[part 3 of 22: package /Cluster]
AUTOSAR XML (schema 4-3-0)
package /Cluster
  can cluster E3V_CCAN: baudrate=500000, protocol-name=CAN, protocol-version=2.0, bus-off-recovery={bor-counter-l-1-to-l-2=1, bor-time-l-1=0.05, bor-time-l-2=0.2}  # CAN Connect
    can physical channel CHNL: comm-connectors=CN_E3V_CCAN
      frame BCM_01_XIX_E3V_CCAN: id 0x65A, from SAM, frame-length=8, can-addressing-mode=STANDARD, can-frame-rx-behavior=CAN-20, can-frame-tx-behavior=CAN-20
        pdu BCM_01_XIX_E3V_CCAN_E2E: length=8, minimum-delay=0.03, transmission-mode-true-timing=event-controlled-timing={number-of-repetitions=0, repetition-period=0.0}, unused-bit-pattern=0  # Fuer die Botschaft ist das Cyclic-Timing 1.0 zu verwenden.
          signal BCM_01_CRC_XIX_BCM_01_XIX_E3V_CCAN: start 0, 8 bit, little-endian, data-type-policy=OVERRIDE, i-signal-type=PRIMITIVE, base-type=BT_BCM_01_CRC, compu {phys=raw for raw 0..255}, range phys 0..255, raw 0..255  # Für MLB: "Berechnung siehe Lastenheft "Kommunikationsabsicherung für FlexRay und CAN"" Ab MQB und MLBevo: "Berechnung siehe Lastenheft "End-to-End Kommunikationsabsicherung"" Endwerte siehe Begleitdokument "S-PDU Kennungsfolgen"
          signal BCM_01_BZ_XIX_BCM_01_XIX_E3V_CCAN: start 8, 4 bit, little-endian, data-type-policy=OVERRIDE, i-signal-type=PRIMITIVE, base-type=BT_BCM_01_BZ, compu {phys=raw for raw 0..15}, range phys 0..15, raw 0..15  # 4bit Botschaftszaehler; wird in jeder Sendebotschaft inkrementiert
          signal BCM_Bremsbelag_Sensor_XIX_BCM_01_XIX_E3V_CCAN: start 12, 1 bit, little-endian, data-type-policy=OVERRIDE, i-signal-type=PRIMITIVE, init-value=0, base-type=BT_BCM_Bremsbelag_Sensor, compu {0=Cx0_OK (CM_BCM_Bremsbelag_Sensor_Cx0_OK), 1=Cx1_Bremsbelag_unter_min (CM_BCM_Bremsbelag_Sensor_Cx1_Bremsbelag_unter_min)}, range raw 0..1  # Sensorsignal der Stromschleife für Bremsbelagverschleiß aktuell, entstört, unbewertet
          signal BCM_Bremsfluessigkeit_Sensor_XIX_BCM_01_XIX_E3V_CCAN: start 13, 1 bit, little-endian, data-type-policy=OVERRIDE, i-signal-type=PRIMITIVE, init-value=0, base-type=BT_BCM_Bremsfluessigkeit_Sensor, compu {0=Cx0_OK (CM_BCM_Bremsfluessigkeit_Sensor_Cx0_OK), 1=Cx1_Bremsfluessigkeit_unter_min (CM_BCM_Bremsfluessigkeit_Sensor_Cx1_Bremsfluessigkeit_unter_min)}, range raw 0..1  # Kontaktsignal des Sensorschalters für die Bremsflüssigkeitsreserve aktuell, entstört, unbewertet
          signal ISignalVoid_BCM_01_XIX_E3V_CCAN_0: start 14, 1 bit, little-endian, system signal SignalVoid_BCM_01_0, data-type-policy=OVERRIDE, i-signal-type=PRIMITIVE, base-type=BT_SignalVoid
          signal BCM_Waschwasser_Sensor_XIX_BCM_01_XIX_E3V_CCAN: start 15, 1 bit, little-endian, data-type-policy=OVERRIDE, i-signal-type=PRIMITIVE, init-value=0, base-type=BT_BCM_Waschwasser_Sensor, compu {0=Cx0_OK (CM_BCM_Waschwasser_Sensor_Cx0_OK), 1=Cx1_Waschwasser_unter_min (CM_BCM_Waschwasser_Sensor_Cx1_Waschwasser_unter_min)}, range raw 0..1  # Signal der Sensorelektroden für die Waschwasserreserve aktuell, entstört, bewertet (OK/Mangel)
          signal BCM_Kuehlmittel_Sensor_XIX_BCM_01_XIX_E3V_CCAN: start 16, 1 bit, little-endian, data-type-policy=OVERRIDE, i-signal-type=PRIMITIVE, init-value=0, base-type=BT_BCM_Kuehlmittel_Sensor, compu {0=Cx0_OK (CM_BCM_Kuehlmittel_Sensor_Cx0_OK), 1=Cx1_Kuehlmittel_unter_min (CM_BCM_Kuehlmittel_Sensor_Cx1_Kuehlmittel_unter_min)}, range raw 0..1  # Signal der Sensorelektroden für die Kühlmittelreserve aktuell, entstört, bewertet (OK/Mangel)
          signal BCM1_Kl_15_HW_erkannt_XIX_BCM_01_XIX_E3V_CCAN: start 17, 1 bit, little-endian, data-type-policy=OVERRIDE, i-signal-type=PRIMITIVE, init-value=0, base-type=BT_BCM1_Kl_15_HW_erkannt, compu {1=Cx1_Klemme_15_erkannt (CM_BCM1_Kl_15_HW_erkannt_Cx1_Klemme_15_erkannt) (Klemme 15 erkannt)}, range raw 1  # Erkennung Klemme 15 (Hardware) vom BCM1
          signal BCM1_Kl_15_Sig_HW_erkannt_XIX_BCM_01_XIX_E3V_CCAN: start 18, 1 bit, little-endian, data-type-policy=OVERRIDE, i-signal-type=PRIMITIVE, init-value=0, base-type=BT_BCM1_Kl_15_Sig_HW_erkannt, compu {0=Cx0_KL15_HW_Signal_von_BCM1_nicht_erkannt (CM_BCM1_Kl_15_Sig_HW_erkannt_Cx0_KL15_HW_Signal_von_BCM1_nicht_erkannt), 1=Cx1_KL15_HW_Signal_von_BCM1_erkannt (CM_BCM1_Kl_15_Sig_HW_erkannt_Cx1_KL15_HW_Signal_von_BCM1_erkannt)}, range raw 0..1  # Erkennung Klemme 15 Signal (Hardware) vom BCM1
          signal BCM_Kuehlmittel_Sensor_02_XIX_BCM_01_XIX_E3V_CCAN: start 19, 1 bit, little-endian, data-type-policy=OVERRIDE, i-signal-type=PRIMITIVE, init-value=0, base-type=BT_BCM_Kuehlmittel_Sensor_02, compu {0=Cx0_OK (CM_BCM_Kuehlmittel_Sensor_02_Cx0_OK), 1=Cx1_Kuehlmittel_unter_min (CM_BCM_Kuehlmittel_Sensor_02_Cx1_Kuehlmittel_unter_min)}, range raw 0..1  # Signal der zweiten Sensorelektroden für die Kühlmittelreserve aktuell, entstört, bewertet (OK/Mangel)
          signal ISignalVoid_BCM_01_XIX_E3V_CCAN_1: start 20, 1 bit, little-endian, system signal SignalVoid_BCM_01_1, data-type-policy=OVERRIDE, i-signal-type=PRIMITIVE, base-type=BT_SignalVoid
          signal BCM_Offroad_Taste_XIX_BCM_01_XIX_E3V_CCAN: start 21, 1 bit, little-endian, data-type-policy=OVERRIDE, i-signal-type=PRIMITIVE, init-value=0, base-type=BT_BCM_Offroad_Taste, compu {0=Cx0_Taster_nicht_betaetigt (CM_BCM_Offroad_Taste_Cx0_Taster_nicht_betaetigt), 1=Cx1_Taster_betaetigt (CM_BCM_Offroad_Taste_Cx1_Taster_betaetigt)}, range raw 0..1  # Betätigung der Offroad-Taste
          signal BCM_Charisma_Taste2_XIX_BCM_01_XIX_E3V_CCAN: start 22, 1 bit, little-endian, data-type-policy=OVERRIDE, i-signal-type=PRIMITIVE, init-value=0, base-type=BT_BCM_Charisma_Taste2, compu {0=Cx0_nicht_betaetigt (CM_BCM_Charisma_Taste2_Cx0_nicht_betaetigt), 1=Cx1_betaetigt (CM_BCM_Charisma_Taste2_Cx1_betaetigt)}, range raw 0..1  # Betätigung der Charisma-Taste 2
          signal BCM_Hybrid_StSt_Taste_Fehler_XIX_BCM_01_XIX_E3V_CCAN: start 23, 1 bit, little-endian, data-type-policy=OVERRIDE, i-signal-type=PRIMITIVE, init-value=0, base-type=BT_BCM_Hybrid_StSt_Taste_Fehler, compu {0=Cx0_kein_Fehler_StSt_Taster (CM_BCM_Hybrid_StSt_Taste_Fehler_Cx0_kein_Fehler_StSt_Taster), 1=Cx1_Fehler_StSt_Taster (CM_BCM_Hybrid_StSt_Taste_Fehler_Cx1_Fehler_StSt_Taster)}, range raw 0..1  # Fehlerflag, wenn Tasterdiagnose im BCM für den StSt-Taster anschlägt.
          signal BCM_Hybrid_StartStopp_Taste_XIX_BCM_01_XIX_E3V_CCAN: start 24, 1 bit, little-endian, data-type-policy=OVERRIDE, i-signal-type=PRIMITIVE, init-value=0, base-type=BT_BCM_Hybrid_StartStopp_Taste, compu {0=Cx0_nicht_betaetigt (CM_BCM_Hybrid_StartStopp_Taste_Cx0_nicht_betaetigt), 1=Cx1_betaetigt (CM_BCM_Hybrid_StartStopp_Taste_Cx1_betaetigt)}, range raw 0..1  # Betaetigung Taster "Hybrid" oder alternativ Taster "Start/Stopp Deaktivierung", je nach Verbau
          signal BCM1_Warnblink_Taster_XIX_BCM_01_XIX_E3V_CCAN: start 25, 1 bit, little-endian, data-type-policy=OVERRIDE, i-signal-type=PRIMITIVE, init-value=0, base-type=BT_BCM1_Warnblink_Taster, compu {0=Cx0_nicht_betaetigt (CM_BCM1_Warnblink_Taster_Cx0_nicht_betaetigt), 1=Cx1_betaetigt (CM_BCM1_Warnblink_Taster_Cx1_betaetigt)}, range raw 0..1  # Warnblinktaster
          signal BCM1_Valet_Parking_Taster_XIX_BCM_01_XIX_E3V_CCAN: start 26, 1 bit, little-endian, data-type-policy=OVERRIDE, i-signal-type=PRIMITIVE, init-value=0, base-type=BT_BCM1_Valet_Parking_Taster, compu {0=Cx0_nicht_betaetigt (CM_BCM1_Valet_Parking_Taster_Cx0_nicht_betaetigt), 1=Cx1_betaetigt (CM_BCM1_Valet_Parking_Taster_Cx1_betaetigt)}, range raw 0..1  # Valet Parking Taster
          signal ISignalVoid_BCM_01_XIX_E3V_CCAN_2: start 27, 3 bit, little-endian, system signal SignalVoid_BCM_01_2, data-type-policy=OVERRIDE, i-signal-type=PRIMITIVE, base-type=BT_SignalVoid
          signal BCM1_Rueckfahrlicht_Schalter_XIX_BCM_01_XIX_E3V_CCAN: start 30, 1 bit, little-endian, data-type-policy=OVERRIDE, i-signal-type=PRIMITIVE, init-value=0, base-type=BT_BCM1_Rueckfahrlicht_Schalter, compu {0=Cx0_nicht_betaetigt (CM_BCM1_Rueckfahrlicht_Schalter_Cx0_nicht_betaetigt), 1=Cx1_betaetigt (CM_BCM1_Rueckfahrlicht_Schalter_Cx1_betaetigt)}, range raw 0..1  # Rückfahrlichtschalter ab MQB/ MLBevo: Die Ganginformation wird unentprellt übertragen, im AT-Getriebe wird evtl. kurzzeitig der R-Gang angezeigt. Eine Entprellung muß im Empfänger erfolgen (typisch 400ms).
          signal BCM1_MH_Schalter_XIX_BCM_01_XIX_E3V_CCAN: start 31, 1 bit, little-endian, data-type-policy=OVERRIDE, i-signal-type=PRIMITIVE, init-value=0, base-type=BT_BCM1_MH_Schalter, compu {0=Cx0_MH_geschlossen (CM_BCM1_MH_Schalter_Cx0_MH_geschlossen), 1=Cx1_MH_offen (CM_BCM1_MH_Schalter_Cx1_MH_offen)}, range raw 0..1  # Motorhaubenkontakt
          signal BCM1_MH_WIV_Schalter_XIX_BCM_01_XIX_E3V_CCAN: start 32, 1 bit, little-endian, data-type-policy=OVERRIDE, i-signal-type=PRIMITIVE, init-value=0, base-type=BT_BCM1_MH_WIV_Schalter, compu {0=Cx0_MH_geschlossen (CM_BCM1_MH_WIV_Schalter_Cx0_MH_geschlossen), 1=Cx1_MH_offen (CM_BCM1_MH_WIV_Schalter_Cx1_MH_offen)}, range raw 0..1  # Bewerteter Motorhaubenkontakt fuer WIV
          signal BCM_Eco_Charisma_Taste_XIX_BCM_01_XIX_E3V_CCAN: start 33, 1 bit, little-endian, data-type-policy=OVERRIDE, i-signal-type=PRIMITIVE, init-value=0, base-type=BT_BCM_Eco_Charisma_Taste, compu {0=Cx0_nicht_betaetigt (CM_BCM_Eco_Charisma_Taste_Cx0_nicht_betaetigt), 1=Cx1_betaetigt (CM_BCM_Eco_Charisma_Taste_Cx1_betaetigt)}, range raw 0..1  # Betätigung Taster ECO alias BlueKey oder Charisma
          signal BCM1_NV_Taster_XIX_BCM_01_XIX_E3V_CCAN: start 34, 1 bit, little-endian, data-type-policy=OVERRIDE, i-signal-type=PRIMITIVE, init-value=0, base-type=BT_BCM1_NV_Taster, compu {0=Cx0_Taster_nicht_betaetigt (CM_BCM1_NV_Taster_Cx0_Taster_nicht_betaetigt), 1=Cx1_Taster_betaetigt (CM_BCM1_NV_Taster_Cx1_Taster_betaetigt)}, range raw 0..1  # BCM1_NV_Taster gibt an, ob der NightVision-Taster im Lichtdrehschalter-Modul aktuell betaetigt wird.
          signal BCM1_AFS_Lampe_XIX_BCM_01_XIX_E3V_CCAN: start 35, 1 bit, little-endian, data-type-policy=OVERRIDE, i-signal-type=PRIMITIVE, init-value=0, base-type=BT_BCM1_AFS_Lampe, compu {0=Cx0_Aus (CM_BCM1_AFS_Lampe_Cx0_Aus), 1=Cx1_Ein (CM_BCM1_AFS_Lampe_Cx1_Ein)}, range raw 0..1  # Ansteuerung der AFS-Fehlermeldung im Kombi
          signal BCM1_Reisemodus_Texte_XIX_BCM_01_XIX_E3V_CCAN: start 36, 2 bit, little-endian, data-type-policy=OVERRIDE, i-signal-type=PRIMITIVE, init-value=0, base-type=BT_BCM1_Reisemodus_Texte, compu {0=Cx0_keine_Anzeige (CM_BCM1_Reisemodus_Texte_Cx0_keine_Anzeige), 1=Cx1_Umschaltung_auf_Linksverkehr_aktiv (CM_BCM1_Reisemodus_Texte_Cx1_Umschaltung_auf_Linksverkehr_aktiv), 2=Cx2_Umschaltung_auf_Rechtsverkehr_aktiv (CM_BCM1_Reisemodus_Texte_Cx2_Umschaltung_auf_Rechtsverkehr_aktiv)}, range raw 0..2  # Ansteuerung der Reisemodus-Texte im Kombi
          signal ISignalVoid_BCM_01_XIX_E3V_CCAN_3: start 38, 2 bit, little-endian, system signal SignalVoid_BCM_01_3, data-type-policy=OVERRIDE, i-signal-type=PRIMITIVE, base-type=BT_SignalVoid
          signal Gong_TFL_Umschaltung_XIX_BCM_01_XIX_E3V_CCAN: start 40, 1 bit, little-endian, data-type-policy=OVERRIDE, i-signal-type=PRIMITIVE, init-value=0, base-type=BT_Gong_TFL_Umschaltung, compu {0=Cx0_kein_Gong (CM_Gong_TFL_Umschaltung_Cx0_kein_Gong), 1=Cx1_Gong_einmalig (CM_Gong_TFL_Umschaltung_Cx1_Gong_einmalig)}, range raw 0..1  # Aktivierung / Deaktivierung des TFL per Affengriff wird mit einem Gong im Kombi quittiert.
          signal ISignalVoid_BCM_01_XIX_E3V_CCAN_4: start 41, 1 bit, little-endian, system signal SignalVoid_BCM_01_4, data-type-policy=OVERRIDE, i-signal-type=PRIMITIVE, base-type=BT_SignalVoid
          signal BCM_ValetTaster_Fkts_LED_XIX_BCM_01_XIX_E3V_CCAN: start 42, 1 bit, little-endian, data-type-policy=OVERRIDE, i-signal-type=PRIMITIVE, init-value=0, base-type=BT_BCM_ValetTaster_Fkts_LED, compu {0=Cx0_LED_aus (CM_BCM_ValetTaster_Fkts_LED_Cx0_LED_aus), 1=Cx1_LED_ein (CM_BCM_ValetTaster_Fkts_LED_Cx1_LED_ein)}, range raw 0..1  # Im MQB beschreibt das Signal nur den Zustand der Funktion Valet Parking (aktiv/ inaktiv) Im MLBevo wird über das Signal zusätzlich die ValetTaster_Fkts_LED (an/ aus) gesteuert
          signal LRH_Taster_XIX_BCM_01_XIX_E3V_CCAN: start 43, 1 bit, little-endian, data-type-policy=OVERRIDE, i-signal-type=PRIMITIVE, init-value=0, base-type=BT_LRH_Taster, compu {0=Cx0_nicht_betaetigt (CM_LRH_Taster_Cx0_nicht_betaetigt), 1=Cx1_betaetigt (CM_LRH_Taster_Cx1_betaetigt)}, range raw 0..1  # Tasterbetätigung Lenkradheizung
          signal APS_Tongeber_defekt_XIX_BCM_01_XIX_E3V_CCAN: start 44, 1 bit, little-endian, data-type-policy=OVERRIDE, i-signal-type=PRIMITIVE, init-value=0, base-type=BT_APS_Tongeber_defekt, compu {0=Cx0_iO (CM_APS_Tongeber_defekt_Cx0_iO), 1=Cx1_defekt (CM_APS_Tongeber_defekt_Cx1_defekt)}, range raw 0..1  # Status APS-Tongeber zur HMI-Ansteuerng der RCTA-Funktion
          signal BCM1_EasyEntry_Status_XIX_BCM_01_XIX_E3V_CCAN: start 45, 1 bit, little-endian, data-type-policy=OVERRIDE, i-signal-type=PRIMITIVE, init-value=0, base-type=BT_BCM1_EasyEntry_Status, compu {0=Cx0_Aus (CM_BCM1_EasyEntry_Status_Cx0_Aus), 1=Cx1_Ein (CM_BCM1_EasyEntry_Status_Cx1_Ein)}, range raw 0..1  # Status EasyEntry für Lenksäule (wird auch von IVB verwendet)
          signal BCM1_Lenksaeule_aktiv_XIX_BCM_01_XIX_E3V_CCAN: start 46, 1 bit, little-endian, data-type-policy=OVERRIDE, i-signal-type=PRIMITIVE, init-value=0, base-type=BT_BCM1_Lenksaeule_aktiv, compu {0=Cx0_Lenksaeulenverstellung_nicht_aktiv (CM_BCM1_Lenksaeule_aktiv_Cx0_Lenksaeulenverstellung_nicht_aktiv) (Lenksaeulenverstellung nicht aktiv), 1=Cx1_Lenksaeulenverstellung_aktiv (CM_BCM1_Lenksaeule_aktiv_Cx1_Lenksaeulenverstellung_aktiv) (Lenksaeulenverstellung aktiv)}, range raw 0..1  # Lenksaeulenverstellung aktiv
          signal BCM1_Spannungs_Anf_XIX_BCM_01_XIX_E3V_CCAN: start 47, 2 bit, little-endian, data-type-policy=OVERRIDE, i-signal-type=PRIMITIVE, init-value=0, base-type=BT_BCM1_Spannungs_Anf, compu {0=Cx0_keine_Anforderung (CM_BCM1_Spannungs_Anf_Cx0_keine_Anforderung), 1=Cx1_Anforderung_Stufe_1 (CM_BCM1_Spannungs_Anf_Cx1_Anforderung_Stufe_1), 2=Cx2_Anforderung_Stufe_2 (CM_BCM1_Spannungs_Anf_Cx2_Anforderung_Stufe_2), 3=Cx3_Anforderung_Stufe_3 (CM_BCM1_Spannungs_Anf_Cx3_Anforderung_Stufe_3)}, range raw 0..3  # Forderung des BCM1-SG's zur Spannungsanhebung.
          signal ISignalVoid_BCM_01_XIX_E3V_CCAN_5: start 49, 7 bit, little-endian, system signal SignalVoid_BCM_01_5, data-type-policy=OVERRIDE, i-signal-type=PRIMITIVE, base-type=BT_SignalVoid
          signal ISignalVoid_BCM_01_XIX_E3V_CCAN_6: start 56, 2 bit, little-endian, system signal SignalVoid_BCM_01_6, data-type-policy=OVERRIDE, i-signal-type=PRIMITIVE, base-type=BT_SignalVoid
          signal BCM_Anf_AAW_MoLaWa_XIX_BCM_01_XIX_E3V_CCAN: start 58, 2 bit, little-endian, data-type-policy=OVERRIDE, i-signal-type=PRIMITIVE, init-value=0, base-type=BT_BCM_Anf_AAW_MoLaWa, compu {0=Cx0_Init (CM_BCM_Anf_AAW_MoLaWa_Cx0_Init), 1=Cx1_AAW_angefordert (CM_BCM_Anf_AAW_MoLaWa_Cx1_AAW_angefordert), 2=Cx2_MoLaWa_angefordert (CM_BCM_Anf_AAW_MoLaWa_Cx2_MoLaWa_angefordert)}, range raw 0..2  # Signal zur Anforderung der Antrieb-Aktiv-Warnung und Motorlaufwarnung. Die Berechnung erfolgt im BCM. Die Ausgabe der Warnungen wird vom Kombiinstrument realisiert
          signal BCM_Handbremse_Hinweis_XIX_BCM_01_XIX_E3V_CCAN: start 60, 1 bit, little-endian, data-type-policy=OVERRIDE, i-signal-type=PRIMITIVE, init-value=0, base-type=BT_BCM_Handbremse_Hinweis, compu {0=Cx0_inaktiv (CM_BCM_Handbremse_Hinweis_Cx0_inaktiv), 1=Cx1_aktiv (CM_BCM_Handbremse_Hinweis_Cx1_aktiv)}, range raw 0..1  # Infotext fuer das Kombiinstrument zur Oeffnung der elektr. Heckklappe.
          signal ISignalVoid_BCM_01_XIX_E3V_CCAN_7: start 61, 2 bit, little-endian, system signal SignalVoid_BCM_01_7, data-type-policy=OVERRIDE, i-signal-type=PRIMITIVE, base-type=BT_SignalVoid
          signal BCM_HDF_betaetigt_XIX_BCM_01_XIX_E3V_CCAN: start 63, 1 bit, little-endian, data-type-policy=OVERRIDE, i-signal-type=PRIMITIVE, init-value=0, base-type=BT_BCM_HDF_betaetigt, compu {0=Cx0_nicht_betaetigt (CM_BCM_HDF_betaetigt_Cx0_nicht_betaetigt), 1=Cx1_betaetigt (CM_BCM_HDF_betaetigt_Cx1_betaetigt)}, range raw 0..1  # Betätigung Taster für Heckdeckelfernentriegelung in Mittelkonsole
          mapping SG_BCM_01_XIX_E3V_CCAN: i-signal-group=SG_BCM_01_XIX_E3V_CCAN, transfer-property=TRIGGERED-WITHOUT-REPETITION
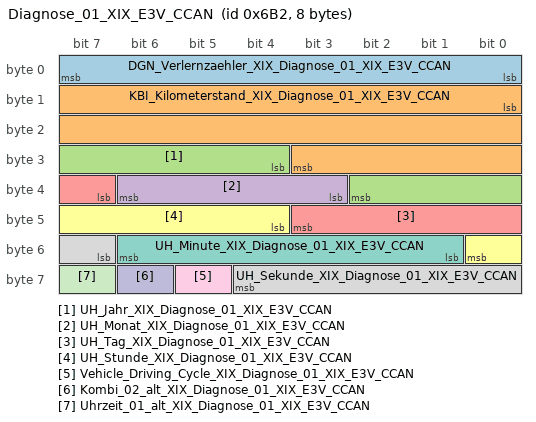
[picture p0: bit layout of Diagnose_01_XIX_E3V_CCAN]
      frame Diagnose_01_XIX_E3V_CCAN: id 0x6B2, to SAM, frame-length=8, can-addressing-mode=STANDARD, can-frame-rx-behavior=CAN-20, can-frame-tx-behavior=CAN-20
        pdu Diagnose_01_XIX_E3V_CCAN: length=8, transmission-mode-true-timing=cyclic-timing={time-offset=0.0, time-period=1.0}, unused-bit-pattern=0
          signal DGN_Verlernzaehler_XIX_Diagnose_01_XIX_E3V_CCAN: start 0, 8 bit, little-endian, data-type-policy=OVERRIDE, i-signal-type=PRIMITIVE, init-value=0, base-type=BT_DGN_Verlernzaehler, compu {phys=raw for raw 0..254, 255=Cxff_ungueltiger_Zaehlerstand_oder_kein_gueltiger_Fahrzyklus (CM_DGN_Verlernzaehler_Cxff_ungueltiger_Zaehlerstand_oder_kein_gueltiger_Fahrzyklus) (ungültiger Zählerstand oder kein gültiger Fahrzyklus)}, range phys 0..254, raw 0..255, transfer-property=PENDING, to SAM(timeout 5 s)  # wrap around 254 --> 0
          signal KBI_Kilometerstand_XIX_Diagnose_01_XIX_E3V_CCAN: start 8, 20 bit, little-endian, data-type-policy=OVERRIDE, i-signal-type=PRIMITIVE, init-value=1048574, base-type=BT_KBI_Kilometerstand, invalid-value=Invalid_KBI_Kilometerstand_XIX_Diagnose_01_XIX_E3V_CCAN:1048575, compu {phys=raw for raw 0..1048573, 1048574=Cxffffe_Init (CM_KBI_Kilometerstand_Cxffffe_Init), 1048575=Cxfffff_Fehler (CM_KBI_Kilometerstand_Cxfffff_Fehler); unit Unit_KiloMeter}, range phys 0..1048573 Unit_KiloMeter, raw 0..1048575, unit=Unit_KiloMeter, transfer-property=PENDING, to SAM(timeout 5 s)  # Fehler wird ausgegeben, falls Kilometerstand nicht restaurierbar
          signal UH_Jahr_XIX_Diagnose_01_XIX_E3V_CCAN: start 28, 7 bit, little-endian, data-type-policy=OVERRIDE, i-signal-type=PRIMITIVE, init-value=0, base-type=BT_UH_Jahr, compu {phys=raw+2000 for raw 0..127; unit Unit_Year}, range phys 2000..2127 Unit_Year, raw 0..127, unit=Unit_Year, transfer-property=PENDING, to SAM(timeout 5 s)
          signal UH_Monat_XIX_Diagnose_01_XIX_E3V_CCAN: start 35, 4 bit, little-endian, data-type-policy=OVERRIDE, i-signal-type=PRIMITIVE, init-value=0, base-type=BT_UH_Monat, invalid-value=Invalid_UH_Monat_XIX_Diagnose_01_XIX_E3V_CCAN:15, compu {0=Cx0_Init (CM_UH_Monat_Cx0_Init), phys=raw for raw 1..12, 14=Cxe_Relatives_Datum (CM_UH_Monat_Cxe_Relatives_Datum), 15=Cxf_Fehler (CM_UH_Monat_Cxf_Fehler); unit Unit_Month}, range phys 1..12 Unit_Month, raw 0..15, unit=Unit_Month, transfer-property=PENDING, to SAM(timeout 5 s)  # 0x0D, 0xF = Werte ungültig 0x0E = Relatives Datum (nur VW)
          signal UH_Tag_XIX_Diagnose_01_XIX_E3V_CCAN: start 39, 5 bit, little-endian, data-type-policy=OVERRIDE, i-signal-type=PRIMITIVE, init-value=0, base-type=BT_UH_Tag, compu {0=Cx0_Init (CM_UH_Tag_Cx0_Init), phys=raw for raw 1..31; unit Unit_Day}, range phys 1..31 Unit_Day, raw 0..31, unit=Unit_Day, transfer-property=PENDING, to SAM(timeout 5 s)  # 0x0: reserviert bei VW
          signal UH_Stunde_XIX_Diagnose_01_XIX_E3V_CCAN: start 44, 5 bit, little-endian, data-type-policy=OVERRIDE, i-signal-type=PRIMITIVE, init-value=0, base-type=BT_UH_Stunde, compu {phys=raw for raw 0..23; unit Unit_Hours}, range phys 0..23 Unit_Hours, raw 0..23, unit=Unit_Hours, transfer-property=PENDING, to SAM(timeout 5 s)  # 0x18 - 0x1F = Werte ungültig
          signal UH_Minute_XIX_Diagnose_01_XIX_E3V_CCAN: start 49, 6 bit, little-endian, data-type-policy=OVERRIDE, i-signal-type=PRIMITIVE, init-value=0, base-type=BT_UH_Minute, compu {phys=raw for raw 0..59; unit Unit_Minut}, range phys 0..59 Unit_Minut, raw 0..59, unit=Unit_Minut, transfer-property=PENDING, to SAM(timeout 5 s)  # 0x3C- 0x3f = Werte ungültig
          signal UH_Sekunde_XIX_Diagnose_01_XIX_E3V_CCAN: start 55, 6 bit, little-endian, data-type-policy=OVERRIDE, i-signal-type=PRIMITIVE, init-value=0, base-type=BT_UH_Sekunde, compu {phys=raw for raw 0..59; unit Unit_Secon}, range phys 0..59 Unit_Secon, raw 0..59, unit=Unit_Secon, transfer-property=PENDING, to SAM(timeout 5 s)  # 0x3C- 0x3f = Werte ungültig
          signal Vehicle_Driving_Cycle_XIX_Diagnose_01_XIX_E3V_CCAN: start 61, 1 bit, little-endian, data-type-policy=OVERRIDE, i-signal-type=PRIMITIVE, init-value=0, base-type=BT_Vehicle_Driving_Cycle, compu {0=Cx0_kein_Driving_Cycle_erkannt (CM_Vehicle_Driving_Cycle_Cx0_kein_Driving_Cycle_erkannt), 1=Cx1_Driving_Cycle_erkannt (CM_Vehicle_Driving_Cycle_Cx1_Driving_Cycle_erkannt)}, range raw 0..1, transfer-property=PENDING  # Optimierung der Inbetriebnahme von Steuergeräten in einem Teilverbau in der Produktion. Siehe VW80114. Signal bildet (durch eine Gateway-Funktion) den Inhalt des Signals OBD_Driving_Cycle ab.
          signal Kombi_02_alt_XIX_Diagnose_01_XIX_E3V_CCAN: start 62, 1 bit, little-endian, data-type-policy=OVERRIDE, i-signal-type=PRIMITIVE, init-value=1, base-type=BT_Kombi_02_alt, compu {0=Cx0_aktuell (CM_Kombi_02_alt_Cx0_aktuell), 1=Cx1_veraltet (CM_Kombi_02_alt_Cx1_veraltet)}, range raw 0..1, transfer-property=PENDING
          signal Uhrzeit_01_alt_XIX_Diagnose_01_XIX_E3V_CCAN: start 63, 1 bit, little-endian, data-type-policy=OVERRIDE, i-signal-type=PRIMITIVE, init-value=1, base-type=BT_Uhrzeit_01_alt, compu {0=Cx0_aktuell (CM_Uhrzeit_01_alt_Cx0_aktuell), 1=Cx1_veraltet (CM_Uhrzeit_01_alt_Cx1_veraltet)}, range raw 0..1, transfer-property=PENDING
      frame EM1_HYB_13_XIX_E3V_CCAN: id 0xB8, to SAM, frame-length=8, can-addressing-mode=STANDARD, can-frame-rx-behavior=CAN-20, can-frame-tx-behavior=CAN-20
        pdu EM1_HYB_13_XIX_E3V_CCAN_E2E: length=8, minimum-delay=0.02, transmission-mode-true-timing=event-controlled-timing={number-of-repetitions=0, repetition-period=0.0}, unused-bit-pattern=0  # Fuer die Botschaft ist das Cyclic-Timing 0.5 zu verwenden.
          signal EM1_HYB_13_CRC_XIX_EM1_HYB_13_XIX_E3V_CCAN: start 0, 8 bit, little-endian, data-type-policy=OVERRIDE, i-signal-type=PRIMITIVE, init-value=0, base-type=BT_EM1_HYB_13_CRC, compu {phys=raw for raw 0..255}, range phys 0..255, raw 0..255, to SAM(timeout 5 s)  # Für MLB: "Berechnung siehe Lastenheft "Kommunikationsabsicherung für FlexRay und CAN"" Ab MQB und MLBevo: "Berechnung siehe Lastenheft "End-to-End Kommunikationsabsicherung"" Endwerte siehe Begleitdokument "S-PDU Kennungsfolgen"
          signal EM1_HYB_13_BZ_XIX_EM1_HYB_13_XIX_E3V_CCAN: start 8, 4 bit, little-endian, data-type-policy=OVERRIDE, i-signal-type=PRIMITIVE, init-value=0, base-type=BT_EM1_HYB_13_BZ, compu {phys=raw for raw 0..15}, range phys 0..15, raw 0..15, to SAM(timeout 5 s)  # Fehlende Beschreibung (Import)
          signal EM1_Freigabe_Info_WFS_XIX_EM1_HYB_13_XIX_E3V_CCAN: start 12, 1 bit, little-endian, data-type-policy=OVERRIDE, i-signal-type=PRIMITIVE, init-value=0, base-type=BT_EM1_Freigabe_Info_WFS, compu {0=Cx0_ungueltig (CM_EM1_Freigabe_Info_WFS_Cx0_ungueltig), 1=Cx1_gueltig (CM_EM1_Freigabe_Info_WFS_Cx1_gueltig)}, range raw 0..1  # WFS-Freigabeinformation
          signal EM1_Sperr_Info_WFS_XIX_EM1_HYB_13_XIX_E3V_CCAN: start 13, 1 bit, little-endian, data-type-policy=OVERRIDE, i-signal-type=PRIMITIVE, init-value=0, base-type=BT_EM1_Sperr_Info_WFS, compu {0=Cx0_nicht_gesperrt (CM_EM1_Sperr_Info_WFS_Cx0_nicht_gesperrt), 1=Cx1_gesperrt (CM_EM1_Sperr_Info_WFS_Cx1_gesperrt)}, range raw 0..1  # WFS-Sperrinformation
          signal EM1_AR_aktiv_XIX_EM1_HYB_13_XIX_E3V_CCAN: start 14, 1 bit, little-endian, data-type-policy=OVERRIDE, i-signal-type=PRIMITIVE, init-value=0, base-type=BT_EM1_AR_aktiv, compu {0=Cx0_Init (CM_EM1_AR_aktiv_Cx0_Init), 1=Cx1_Ruckeldaempfer_aktiv (CM_EM1_AR_aktiv_Cx1_Ruckeldaempfer_aktiv)}, range raw 0..1  # Ruckeldämpfer aktiv
          signal EM1_Eta_Sys_XIX_EM1_HYB_13_XIX_E3V_CCAN: start 15, 9 bit, little-endian, data-type-policy=OVERRIDE, i-signal-type=PRIMITIVE, init-value=510, base-type=BT_EM1_Eta_Sys, invalid-value=Invalid_EM1_Eta_Sys_XIX_EM1_HYB_13_XIX_E3V_CCAN:511, compu {phys=raw*0.2 for raw 0..509, 510=Cx1fe_Init (CM_EM1_Eta_Sys_Cx1fe_Init), 511=Cx1ff_Fehler (CM_EM1_Eta_Sys_Cx1ff_Fehler); unit Unit_PerCent}, range phys 0..101.8 Unit_PerCent, raw 0..511, unit=Unit_PerCent  # Instantaneous efficiency of electrical drive EM1 / Momentaner Wirkungsgrad elektrischer Antrieb EM1
          signal EM1_IstStrom_XIX_EM1_HYB_13_XIX_E3V_CCAN: start 24, 11 bit, little-endian, data-type-policy=OVERRIDE, i-signal-type=PRIMITIVE, init-value=2046, base-type=BT_EM1_IstStrom, invalid-value=Invalid_EM1_IstStrom_XIX_EM1_HYB_13_XIX_E3V_CCAN:2047, compu {phys=raw-1023 for raw 0..2045, 2046=Cx7fe_Init (CM_EM1_IstStrom_Cx7fe_Init), 2047=Cx7ff_Fehler (CM_EM1_IstStrom_Cx7ff_Fehler); unit Unit_Amper}, range phys -1023..1022 Unit_Amper, raw 0..2047, unit=Unit_Amper  # Momentanwert: Strom über PWR
          signal EM1_Fehler_ElAntriebFreilauf_Anf_XIX_EM1_HYB_13_XIX_E3V_CCAN: start 35, 1 bit, little-endian, data-type-policy=OVERRIDE, i-signal-type=PRIMITIVE, init-value=0, base-type=BT_EM1_Fehler_ElAntriebFreilauf_Anf, compu {0=Cx0_Init (CM_EM1_Fehler_ElAntriebFreilauf_Anf_Cx0_Init), 1=Cx1_Fehler_EM_im_Freilauf (CM_EM1_Fehler_ElAntriebFreilauf_Anf_Cx1_Fehler_EM_im_Freilauf)}, range raw 0..1  # Wird gesetzt um den zwingenden Bedarf einer Umschaltung in den Freilauf anzuzeigen. Vergleiche Signal EM1_MaxZul_Drehzahl.
          signal EM1_Abregelung_Temperatur_XIX_EM1_HYB_13_XIX_E3V_CCAN: start 36, 1 bit, little-endian, data-type-policy=OVERRIDE, i-signal-type=PRIMITIVE, init-value=0, base-type=BT_EM1_Abregelung_Temperatur, compu {0=Cx0_Init (CM_EM1_Abregelung_Temperatur_Cx0_Init), 1=Cx1_Abregelung_Temperatur (CM_EM1_Abregelung_Temperatur_Cx1_Abregelung_Temperatur)}, range raw 0..1  # Leistungsbegrenzung aufgrund Übertemperatur der E-Maschine / des PWR
          signal ISignalVoid_EM1_HYB_13_XIX_E3V_CCAN_0: start 37, 3 bit, little-endian, system signal SignalVoid_EM1_HYB_13_0, data-type-policy=OVERRIDE, i-signal-type=PRIMITIVE, base-type=BT_SignalVoid
          signal ISignalVoid_EM1_HYB_13_XIX_E3V_CCAN_1: start 40, 3 bit, little-endian, system signal SignalVoid_EM1_HYB_13_1, data-type-policy=OVERRIDE, i-signal-type=PRIMITIVE, base-type=BT_SignalVoid
          signal EM1_AnlernenElMotor_Anf_XIX_EM1_HYB_13_XIX_E3V_CCAN: start 43, 1 bit, little-endian, data-type-policy=OVERRIDE, i-signal-type=PRIMITIVE, init-value=0, base-type=BT_EM1_AnlernenElMotor_Anf, compu {0=Cx0_kein_Diagnose_Request (CM_EM1_AnlernenElMotor_Anf_Cx0_kein_Diagnose_Request), 1=Cx1_Diagnose_Request (CM_EM1_AnlernenElMotor_Anf_Cx1_Diagnose_Request)}, range raw 0..1  # Diagnoseanforderung von E-Maschine/PWR: Hybrid-Controller schaltet über MO_EM_Sollmodus=6 bzw. MY3_EM_modeReq=6 E-Maschine/PWR aktiv in den Kalibriermodus (Strategie muss sicherstellen, dass kein Moment bei der EM angefordert wird.)
          signal EM1_Moment_HVVerbraucher_XIX_EM1_HYB_13_XIX_E3V_CCAN: start 44, 10 bit, little-endian, data-type-policy=OVERRIDE, i-signal-type=PRIMITIVE, init-value=1023, base-type=BT_EM1_Moment_HVVerbraucher, compu {phys=raw-511 for raw 0..1022, 1023=Cx3ff_Init (CM_EM1_Moment_HVVerbraucher_Cx3ff_Init); unit Unit_NewtoMeter}, range phys -511..511 Unit_NewtoMeter, raw 0..1023, unit=Unit_NewtoMeter  # rechnerisch benötigtes Generator-Moment, um den Bedarf der el. Nebenverbraucher incl. Batterieladung abzudecken
          signal ISignalVoid_EM1_HYB_13_XIX_E3V_CCAN_2: start 54, 1 bit, little-endian, system signal SignalVoid_EM1_HYB_13_2, data-type-policy=OVERRIDE, i-signal-type=PRIMITIVE, base-type=BT_SignalVoid
          signal EM1_Freigabe_Verfallsinfo_WFS_XIX_EM1_HYB_13_XIX_E3V_CCAN: start 55, 1 bit, little-endian, data-type-policy=OVERRIDE, i-signal-type=PRIMITIVE, init-value=0, base-type=BT_EM1_Freigabe_Verfallsinfo_WFS, compu {0=Cx0_Aus (CM_EM1_Freigabe_Verfallsinfo_WFS_Cx0_Aus), 1=Cx1_Ein (CM_EM1_Freigabe_Verfallsinfo_WFS_Cx1_Ein)}, range raw 0..1  # WFS
          signal EM1_Parken_WFS_Status_XIX_EM1_HYB_13_XIX_E3V_CCAN: start 56, 2 bit, little-endian, data-type-policy=OVERRIDE, i-signal-type=PRIMITIVE, init-value=0, base-type=BT_EM1_Parken_WFS_Status, compu {0=Cx0_Limitierung_Inaktiv (CM_EM1_Parken_WFS_Status_Cx0_Limitierung_Inaktiv), 1=Cx1_Limitierung_Aktiv (CM_EM1_Parken_WFS_Status_Cx1_Limitierung_Aktiv), 2=Cx2_Abbruch (CM_EM1_Parken_WFS_Status_Cx2_Abbruch)}, range raw 0..2  # Status der Limitierung
          signal EM1_HV_betriebsbereit_XIX_EM1_HYB_13_XIX_E3V_CCAN: start 58, 1 bit, little-endian, data-type-policy=OVERRIDE, i-signal-type=PRIMITIVE, init-value=0, base-type=BT_EM1_HV_betriebsbereit, compu {0=Cx0_Init (CM_EM1_HV_betriebsbereit_Cx0_Init), 1=Cx1_Ready_HV (CM_EM1_HV_betriebsbereit_Cx1_Ready_HV)}, range raw 0..1  # 1: Ready_HV / 1: HV-Netz Spannung im Betriebsbereich
          signal LE1_TorqueLockStatus_XIX_EM1_HYB_13_XIX_E3V_CCAN: start 59, 2 bit, little-endian, data-type-policy=OVERRIDE, i-signal-type=PRIMITIVE, init-value=0, base-type=BT_LE1_TorqueLockStatus, compu {0=Cx0_Idle (CM_LE1_TorqueLockStatus_Cx0_Idle), 1=Cx1_LockReleased (CM_LE1_TorqueLockStatus_Cx1_LockReleased), 2=Cx2_LockActive (CM_LE1_TorqueLockStatus_Cx2_LockActive)}, range raw 0..2, to SAM(timeout 5 s)  # Confirms the request for drive torque to zero coming from ORU_Guard2 on SAM
          signal ISignalVoid_EM1_HYB_13_XIX_E3V_CCAN_3: start 61, 3 bit, little-endian, system signal SignalVoid_EM1_HYB_13_3, data-type-policy=OVERRIDE, i-signal-type=PRIMITIVE, base-type=BT_SignalVoid
          mapping SG_EM1_HYB_13_XIX_E3V_CCAN: i-signal-group=SG_EM1_HYB_13_XIX_E3V_CCAN, transfer-property=TRIGGERED-WITHOUT-REPETITION
      frame EM2_HYB_13_XIX_E3V_CCAN: id 0xC7, to SAM, frame-length=8, can-addressing-mode=STANDARD, can-frame-rx-behavior=CAN-20, can-frame-tx-behavior=CAN-20
        pdu EM2_HYB_13_XIX_E3V_CCAN_E2E: length=8, minimum-delay=0.02, transmission-mode-true-timing=event-controlled-timing={number-of-repetitions=0, repetition-period=0.0}, unused-bit-pattern=0  # Fuer die Botschaft ist das Cyclic-Timing 0.5 zu verwenden.
          signal EM2_HYB_13_CRC_XIX_EM2_HYB_13_XIX_E3V_CCAN: start 0, 8 bit, little-endian, data-type-policy=OVERRIDE, i-signal-type=PRIMITIVE, init-value=0, base-type=BT_EM2_HYB_13_CRC, compu {phys=raw for raw 0..255}, range phys 0..255, raw 0..255, to SAM(timeout 5 s)  # Für MLB: "Berechnung siehe Lastenheft "Kommunikationsabsicherung für FlexRay und CAN"" Ab MQB und MLBevo: "Berechnung siehe Lastenheft "End-to-End Kommunikationsabsicherung"" Endwerte siehe Begleitdokument "S-PDU Kennungsfolgen"
          signal EM2_HYB_13_BZ_XIX_EM2_HYB_13_XIX_E3V_CCAN: start 8, 4 bit, little-endian, data-type-policy=OVERRIDE, i-signal-type=PRIMITIVE, init-value=0, base-type=BT_EM2_HYB_13_BZ, compu {phys=raw for raw 0..15}, range phys 0..15, raw 0..15, to SAM(timeout 5 s)  # Fehlende Beschreibung (Import)
          signal EM2_Freigabe_Info_WFS_XIX_EM2_HYB_13_XIX_E3V_CCAN: start 12, 1 bit, little-endian, data-type-policy=OVERRIDE, i-signal-type=PRIMITIVE, init-value=0, base-type=BT_EM2_Freigabe_Info_WFS, compu {0=Cx0_ungueltig (CM_EM2_Freigabe_Info_WFS_Cx0_ungueltig), 1=Cx1_gueltig (CM_EM2_Freigabe_Info_WFS_Cx1_gueltig)}, range raw 0..1  # WFS-Freigabeinformation
          signal EM2_Sperr_Info_WFS_XIX_EM2_HYB_13_XIX_E3V_CCAN: start 13, 1 bit, little-endian, data-type-policy=OVERRIDE, i-signal-type=PRIMITIVE, init-value=0, base-type=BT_EM2_Sperr_Info_WFS, compu {0=Cx0_nicht_gesperrt (CM_EM2_Sperr_Info_WFS_Cx0_nicht_gesperrt), 1=Cx1_gesperrt (CM_EM2_Sperr_Info_WFS_Cx1_gesperrt)}, range raw 0..1  # WFS-Sperrinformation
          signal EM2_AR_aktiv_XIX_EM2_HYB_13_XIX_E3V_CCAN: start 14, 1 bit, little-endian, data-type-policy=OVERRIDE, i-signal-type=PRIMITIVE, init-value=0, base-type=BT_EM2_AR_aktiv, compu {0=Cx0_Init (CM_EM2_AR_aktiv_Cx0_Init), 1=Cx1_Ruckeldaempfer_aktiv (CM_EM2_AR_aktiv_Cx1_Ruckeldaempfer_aktiv)}, range raw 0..1  # Ruckeldämpfer aktiv
          signal EM2_Eta_Sys_XIX_EM2_HYB_13_XIX_E3V_CCAN: start 15, 9 bit, little-endian, data-type-policy=OVERRIDE, i-signal-type=PRIMITIVE, init-value=510, base-type=BT_EM2_Eta_Sys, invalid-value=Invalid_EM2_Eta_Sys_XIX_EM2_HYB_13_XIX_E3V_CCAN:511, compu {phys=raw*0.2 for raw 0..509, 510=Cx1fe_Init (CM_EM2_Eta_Sys_Cx1fe_Init), 511=Cx1ff_Fehler (CM_EM2_Eta_Sys_Cx1ff_Fehler); unit Unit_PerCent}, range phys 0..101.8 Unit_PerCent, raw 0..511, unit=Unit_PerCent  # Instantaneous efficiency of electrical drive EM2 / Momentaner Wirkungsgrad elektrischer Antrieb EM2
          signal EM2_IstStrom_XIX_EM2_HYB_13_XIX_E3V_CCAN: start 24, 11 bit, little-endian, data-type-policy=OVERRIDE, i-signal-type=PRIMITIVE, init-value=2046, base-type=BT_EM2_IstStrom, invalid-value=Invalid_EM2_IstStrom_XIX_EM2_HYB_13_XIX_E3V_CCAN:2047, compu {phys=raw-1023 for raw 0..2045, 2046=Cx7fe_Init (CM_EM2_IstStrom_Cx7fe_Init), 2047=Cx7ff_Fehler (CM_EM2_IstStrom_Cx7ff_Fehler); unit Unit_Amper}, range phys -1023..1022 Unit_Amper, raw 0..2047, unit=Unit_Amper  # Momentanwert: Strom über PWR
          signal EM2_Fehler_ElAntriebFreilauf_Anf_XIX_EM2_HYB_13_XIX_E3V_CCAN: start 35, 1 bit, little-endian, data-type-policy=OVERRIDE, i-signal-type=PRIMITIVE, init-value=0, base-type=BT_EM2_Fehler_ElAntriebFreilauf_Anf, compu {0=Cx0_Init (CM_EM2_Fehler_ElAntriebFreilauf_Anf_Cx0_Init), 1=Cx1_Fehler_EM_im_Freilauf (CM_EM2_Fehler_ElAntriebFreilauf_Anf_Cx1_Fehler_EM_im_Freilauf)}, range raw 0..1  # Wird gesetzt um den zwingenden Bedarf einer Umschaltung in den Freilauf anzuzeigen. Vergleiche Signal EM1_MaxZul_Drehzahl.
          signal EM2_Abregelung_Temperatur_XIX_EM2_HYB_13_XIX_E3V_CCAN: start 36, 1 bit, little-endian, data-type-policy=OVERRIDE, i-signal-type=PRIMITIVE, init-value=0, base-type=BT_EM2_Abregelung_Temperatur, compu {0=Cx0_Init (CM_EM2_Abregelung_Temperatur_Cx0_Init), 1=Cx1_Abregelung_Temperatur (CM_EM2_Abregelung_Temperatur_Cx1_Abregelung_Temperatur)}, range raw 0..1  # Leistungsbegrenzung aufgrund Übertemperatur der E-Maschine / des PWR
          signal ISignalVoid_EM2_HYB_13_XIX_E3V_CCAN_0: start 37, 3 bit, little-endian, system signal SignalVoid_EM2_HYB_13_0, data-type-policy=OVERRIDE, i-signal-type=PRIMITIVE, base-type=BT_SignalVoid
          signal ISignalVoid_EM2_HYB_13_XIX_E3V_CCAN_1: start 40, 3 bit, little-endian, system signal SignalVoid_EM2_HYB_13_1, data-type-policy=OVERRIDE, i-signal-type=PRIMITIVE, base-type=BT_SignalVoid
          signal EM2_AnlernenElMotor_Anf_XIX_EM2_HYB_13_XIX_E3V_CCAN: start 43, 1 bit, little-endian, data-type-policy=OVERRIDE, i-signal-type=PRIMITIVE, init-value=0, base-type=BT_EM2_AnlernenElMotor_Anf, compu {0=Cx0_kein_Diagnose_Request (CM_EM2_AnlernenElMotor_Anf_Cx0_kein_Diagnose_Request), 1=Cx1_Diagnose_Request (CM_EM2_AnlernenElMotor_Anf_Cx1_Diagnose_Request)}, range raw 0..1  # Diagnoseanforderung von E-Maschine/PWR: Hybrid-Controller schaltet über MO_EM_Sollmodus=6 bzw. MY3_EM_modeReq=6 E-Maschine/PWR aktiv in den Kalibriermodus (Strategie muss sicherstellen, dass kein Moment bei der EM angefordert wird.)
          signal ISignalVoid_EM2_HYB_13_XIX_E3V_CCAN_2: start 44, 4 bit, little-endian, system signal SignalVoid_EM2_HYB_13_2, data-type-policy=OVERRIDE, i-signal-type=PRIMITIVE, base-type=BT_SignalVoid
          signal ISignalVoid_EM2_HYB_13_XIX_E3V_CCAN_3: start 48, 7 bit, little-endian, system signal SignalVoid_EM2_HYB_13_3, data-type-policy=OVERRIDE, i-signal-type=PRIMITIVE, base-type=BT_SignalVoid
          signal EM2_Freigabe_Verfallsinfo_WFS_XIX_EM2_HYB_13_XIX_E3V_CCAN: start 55, 1 bit, little-endian, data-type-policy=OVERRIDE, i-signal-type=PRIMITIVE, init-value=0, base-type=BT_EM2_Freigabe_Verfallsinfo_WFS, compu {0=Cx0_Aus (CM_EM2_Freigabe_Verfallsinfo_WFS_Cx0_Aus), 1=Cx1_Ein (CM_EM2_Freigabe_Verfallsinfo_WFS_Cx1_Ein)}, range raw 0..1  # WFS
          signal EM2_Parken_WFS_Status_XIX_EM2_HYB_13_XIX_E3V_CCAN: start 56, 2 bit, little-endian, data-type-policy=OVERRIDE, i-signal-type=PRIMITIVE, init-value=0, base-type=BT_EM2_Parken_WFS_Status, compu {0=Cx0_Limitierung_Inaktiv (CM_EM2_Parken_WFS_Status_Cx0_Limitierung_Inaktiv), 1=Cx1_Limitierung_Aktiv (CM_EM2_Parken_WFS_Status_Cx1_Limitierung_Aktiv), 2=Cx2_Abbruch (CM_EM2_Parken_WFS_Status_Cx2_Abbruch)}, range raw 0..2  # Status der Limitierung
          signal EM2_HV_betriebsbereit_XIX_EM2_HYB_13_XIX_E3V_CCAN: start 58, 1 bit, little-endian, data-type-policy=OVERRIDE, i-signal-type=PRIMITIVE, init-value=0, base-type=BT_EM2_HV_betriebsbereit, compu {0=Cx0_Init (CM_EM2_HV_betriebsbereit_Cx0_Init), 1=Cx1_Ready_HV (CM_EM2_HV_betriebsbereit_Cx1_Ready_HV)}, range raw 0..1  # 1: Ready_HV / 1: HV-Netz Spannung im Betriebsbereich
          signal LE2_TorqueLockStatus_XIX_EM2_HYB_13_XIX_E3V_CCAN: start 59, 2 bit, little-endian, data-type-policy=OVERRIDE, i-signal-type=PRIMITIVE, init-value=0, base-type=BT_LE2_TorqueLockStatus, compu {0=Cx0_Idle (CM_LE2_TorqueLockStatus_Cx0_Idle), 1=Cx1_LockReleased (CM_LE2_TorqueLockStatus_Cx1_LockReleased), 2=Cx2_LockActive (CM_LE2_TorqueLockStatus_Cx2_LockActive)}, range raw 0..2, to SAM(timeout 5 s)  # Confirms the request for drive torque to zero coming from ORU_Guard2 on SAM
          signal ISignalVoid_EM2_HYB_13_XIX_E3V_CCAN_4: start 61, 3 bit, little-endian, system signal SignalVoid_EM2_HYB_13_4, data-type-policy=OVERRIDE, i-signal-type=PRIMITIVE, base-type=BT_SignalVoid
          mapping SG_EM2_HYB_13_XIX_E3V_CCAN: i-signal-group=SG_EM2_HYB_13_XIX_E3V_CCAN, transfer-property=TRIGGERED-WITHOUT-REPETITION
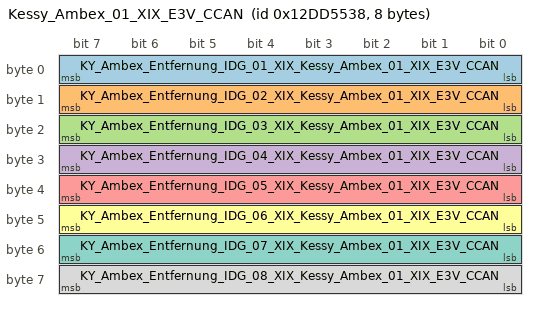
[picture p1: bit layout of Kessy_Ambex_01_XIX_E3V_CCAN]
      frame Kessy_Ambex_01_XIX_E3V_CCAN: id 0x12DD5538, to SAM, frame-length=8, can-addressing-mode=EXTENDED, can-frame-rx-behavior=CAN-20, can-frame-tx-behavior=CAN-20
        pdu Kessy_Ambex_01_XIX_E3V_CCAN: length=8, minimum-delay=0.01, transmission-mode-true-timing={cyclic-timing={time-offset=0.0, time-period=0.5}, event-controlled-timing={number-of-repetitions=0, repetition-period=0.0}}, unused-bit-pattern=0
          signal KY_Ambex_Entfernung_IDG_01_XIX_Kessy_Ambex_01_XIX_E3V_CCAN: start 0, 8 bit, little-endian, data-type-policy=OVERRIDE, i-signal-type=PRIMITIVE, init-value=254, base-type=BT_KY_Ambex_Entfernung_IDG_01, compu {phys=raw*0.05 for raw 0..250, 254=Cxfe_Init (CM_KY_Ambex_Entfernung_IDG_01_Cxfe_Init); unit Unit_Meter}, range phys 0..12.5 Unit_Meter, raw 0..254, unit=Unit_Meter, transfer-property=TRIGGERED-ON-CHANGE-WITHOUT-REPETITION, to SAM(timeout 5 s)  # Entfernung für ID-Geber 1 = Distanz zum Fahrzeugmittelpunkt in der der ID-Geber gefunden wurde
          signal KY_Ambex_Entfernung_IDG_02_XIX_Kessy_Ambex_01_XIX_E3V_CCAN: start 8, 8 bit, little-endian, data-type-policy=OVERRIDE, i-signal-type=PRIMITIVE, init-value=254, base-type=BT_KY_Ambex_Entfernung_IDG_02, compu {phys=raw*0.05 for raw 0..250, 254=Cxfe_Init (CM_KY_Ambex_Entfernung_IDG_02_Cxfe_Init); unit Unit_Meter}, range phys 0..12.5 Unit_Meter, raw 0..254, unit=Unit_Meter, transfer-property=TRIGGERED-ON-CHANGE-WITHOUT-REPETITION, to SAM(timeout 5 s)  # Entfernung für ID-Geber 2 = Distanz zum Fahrzeugmittelpunkt in der der ID-Geber gefunden wurde
          signal KY_Ambex_Entfernung_IDG_03_XIX_Kessy_Ambex_01_XIX_E3V_CCAN: start 16, 8 bit, little-endian, data-type-policy=OVERRIDE, i-signal-type=PRIMITIVE, init-value=254, base-type=BT_KY_Ambex_Entfernung_IDG_03, compu {phys=raw*0.05 for raw 0..250, 254=Cxfe_Init (CM_KY_Ambex_Entfernung_IDG_03_Cxfe_Init); unit Unit_Meter}, range phys 0..12.5 Unit_Meter, raw 0..254, unit=Unit_Meter, transfer-property=TRIGGERED-ON-CHANGE-WITHOUT-REPETITION, to SAM(timeout 5 s)  # Entfernung für ID-Geber 3 = Distanz zum Fahrzeugmittelpunkt in der der ID-Geber gefunden wurde
          signal KY_Ambex_Entfernung_IDG_04_XIX_Kessy_Ambex_01_XIX_E3V_CCAN: start 24, 8 bit, little-endian, data-type-policy=OVERRIDE, i-signal-type=PRIMITIVE, init-value=254, base-type=BT_KY_Ambex_Entfernung_IDG_04, compu {phys=raw*0.05 for raw 0..250, 254=Cxfe_Init (CM_KY_Ambex_Entfernung_IDG_04_Cxfe_Init); unit Unit_Meter}, range phys 0..12.5 Unit_Meter, raw 0..254, unit=Unit_Meter, transfer-property=TRIGGERED-ON-CHANGE-WITHOUT-REPETITION, to SAM(timeout 5 s)  # Entfernung für ID-Geber 4 = Distanz zum Fahrzeugmittelpunkt in der der ID-Geber gefunden wurde
          signal KY_Ambex_Entfernung_IDG_05_XIX_Kessy_Ambex_01_XIX_E3V_CCAN: start 32, 8 bit, little-endian, data-type-policy=OVERRIDE, i-signal-type=PRIMITIVE, init-value=254, base-type=BT_KY_Ambex_Entfernung_IDG_05, compu {phys=raw*0.05 for raw 0..250, 254=Cxfe_Init (CM_KY_Ambex_Entfernung_IDG_05_Cxfe_Init); unit Unit_Meter}, range phys 0..12.5 Unit_Meter, raw 0..254, unit=Unit_Meter, transfer-property=TRIGGERED-ON-CHANGE-WITHOUT-REPETITION, to SAM(timeout 5 s)  # Entfernung für ID-Geber 5 = Distanz zum Fahrzeugmittelpunkt in der der ID-Geber gefunden wurde
          signal KY_Ambex_Entfernung_IDG_06_XIX_Kessy_Ambex_01_XIX_E3V_CCAN: start 40, 8 bit, little-endian, data-type-policy=OVERRIDE, i-signal-type=PRIMITIVE, init-value=254, base-type=BT_KY_Ambex_Entfernung_IDG_06, compu {phys=raw*0.05 for raw 0..250, 254=Cxfe_Init (CM_KY_Ambex_Entfernung_IDG_06_Cxfe_Init); unit Unit_Meter}, range phys 0..12.5 Unit_Meter, raw 0..254, unit=Unit_Meter, transfer-property=TRIGGERED-ON-CHANGE-WITHOUT-REPETITION, to SAM(timeout 5 s)  # Entfernung für ID-Geber 6 = Distanz zum Fahrzeugmittelpunkt in der der ID-Geber gefunden wurde
          signal KY_Ambex_Entfernung_IDG_07_XIX_Kessy_Ambex_01_XIX_E3V_CCAN: start 48, 8 bit, little-endian, data-type-policy=OVERRIDE, i-signal-type=PRIMITIVE, init-value=254, base-type=BT_KY_Ambex_Entfernung_IDG_07, compu {phys=raw*0.05 for raw 0..250, 254=Cxfe_Init (CM_KY_Ambex_Entfernung_IDG_07_Cxfe_Init); unit Unit_Meter}, range phys 0..12.5 Unit_Meter, raw 0..254, unit=Unit_Meter, transfer-property=TRIGGERED-ON-CHANGE-WITHOUT-REPETITION, to SAM(timeout 5 s)  # Entfernung für ID-Geber 7 = Distanz zum Fahrzeugmittelpunkt in der der ID-Geber gefunden wurde
          signal KY_Ambex_Entfernung_IDG_08_XIX_Kessy_Ambex_01_XIX_E3V_CCAN: start 56, 8 bit, little-endian, data-type-policy=OVERRIDE, i-signal-type=PRIMITIVE, init-value=254, base-type=BT_KY_Ambex_Entfernung_IDG_08, compu {phys=raw*0.05 for raw 0..250, 254=Cxfe_Init (CM_KY_Ambex_Entfernung_IDG_08_Cxfe_Init); unit Unit_Meter}, range phys 0..12.5 Unit_Meter, raw 0..254, unit=Unit_Meter, transfer-property=TRIGGERED-ON-CHANGE-WITHOUT-REPETITION, to SAM(timeout 5 s)  # Entfernung für ID-Geber 8 = Distanz zum Fahrzeugmittelpunkt in der der ID-Geber gefunden wurde
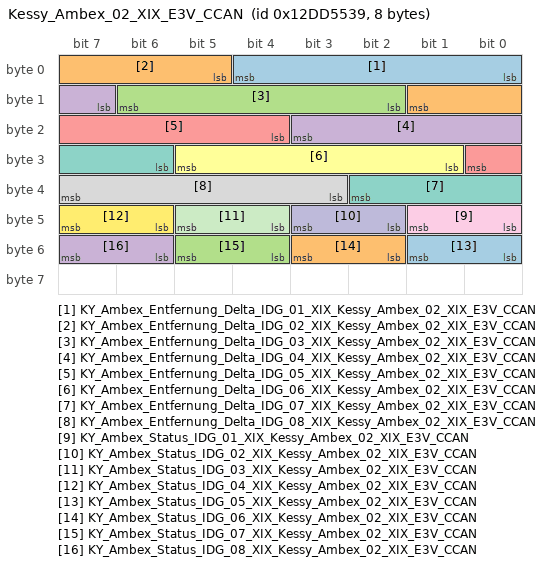
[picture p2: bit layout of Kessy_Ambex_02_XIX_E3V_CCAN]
      frame Kessy_Ambex_02_XIX_E3V_CCAN: id 0x12DD5539, to SAM, frame-length=8, can-addressing-mode=EXTENDED, can-frame-rx-behavior=CAN-20, can-frame-tx-behavior=CAN-20
        pdu Kessy_Ambex_02_XIX_E3V_CCAN: length=8, minimum-delay=0.01, transmission-mode-true-timing={cyclic-timing={time-offset=0.0, time-period=0.5}, event-controlled-timing={number-of-repetitions=0, repetition-period=0.0}}, unused-bit-pattern=0
          signal KY_Ambex_Entfernung_Delta_IDG_01_XIX_Kessy_Ambex_02_XIX_E3V_CCAN: start 0, 5 bit, little-endian, data-type-policy=OVERRIDE, i-signal-type=PRIMITIVE, init-value=0, base-type=BT_KY_Ambex_Entfernung_Delta_IDG_01, compu {phys=raw*0.05 for raw 0..20; unit Unit_Meter}, range phys 0..1 Unit_Meter, raw 0..20, unit=Unit_Meter, transfer-property=TRIGGERED-ON-CHANGE-WITHOUT-REPETITION, to SAM(timeout 5 s)  # Entfernungsabweichung für ID-Geber 1 = Maximale (betragsmäßige) Abweichung von der Distanz in der der ID-Geber gefunden wurde
          signal KY_Ambex_Entfernung_Delta_IDG_02_XIX_Kessy_Ambex_02_XIX_E3V_CCAN: start 5, 5 bit, little-endian, data-type-policy=OVERRIDE, i-signal-type=PRIMITIVE, init-value=0, base-type=BT_KY_Ambex_Entfernung_Delta_IDG_02, compu {phys=raw*0.05 for raw 0..20; unit Unit_Meter}, range phys 0..1 Unit_Meter, raw 0..20, unit=Unit_Meter, transfer-property=TRIGGERED-ON-CHANGE-WITHOUT-REPETITION, to SAM(timeout 5 s)  # Entfernungsabweichung für ID-Geber 2 = Maximale (betragsmäßige) Abweichung von der Distanz in der der ID-Geber gefunden wurde
          signal KY_Ambex_Entfernung_Delta_IDG_03_XIX_Kessy_Ambex_02_XIX_E3V_CCAN: start 10, 5 bit, little-endian, data-type-policy=OVERRIDE, i-signal-type=PRIMITIVE, init-value=0, base-type=BT_KY_Ambex_Entfernung_Delta_IDG_03, compu {phys=raw*0.05 for raw 0..20; unit Unit_Meter}, range phys 0..1 Unit_Meter, raw 0..20, unit=Unit_Meter, transfer-property=TRIGGERED-ON-CHANGE-WITHOUT-REPETITION, to SAM(timeout 5 s)  # Entfernungsabweichung für ID-Geber 3 = Maximale (betragsmäßige) Abweichung von der Distanz in der der ID-Geber gefunden wurde
          signal KY_Ambex_Entfernung_Delta_IDG_04_XIX_Kessy_Ambex_02_XIX_E3V_CCAN: start 15, 5 bit, little-endian, data-type-policy=OVERRIDE, i-signal-type=PRIMITIVE, init-value=0, base-type=BT_KY_Ambex_Entfernung_Delta_IDG_04, compu {phys=raw*0.05 for raw 0..20; unit Unit_Meter}, range phys 0..1 Unit_Meter, raw 0..20, unit=Unit_Meter, transfer-property=TRIGGERED-ON-CHANGE-WITHOUT-REPETITION, to SAM(timeout 5 s)  # Entfernungsabweichung für ID-Geber 4 = Maximale (betragsmäßige) Abweichung von der Distanz in der der ID-Geber gefunden wurde
          signal KY_Ambex_Entfernung_Delta_IDG_05_XIX_Kessy_Ambex_02_XIX_E3V_CCAN: start 20, 5 bit, little-endian, data-type-policy=OVERRIDE, i-signal-type=PRIMITIVE, init-value=0, base-type=BT_KY_Ambex_Entfernung_Delta_IDG_05, compu {phys=raw*0.05 for raw 0..20; unit Unit_Meter}, range phys 0..1 Unit_Meter, raw 0..20, unit=Unit_Meter, transfer-property=TRIGGERED-ON-CHANGE-WITHOUT-REPETITION, to SAM(timeout 5 s)  # Entfernungsabweichung für ID-Geber 5 = Maximale (betragsmäßige) Abweichung von der Distanz in der der ID-Geber gefunden wurde
          signal KY_Ambex_Entfernung_Delta_IDG_06_XIX_Kessy_Ambex_02_XIX_E3V_CCAN: start 25, 5 bit, little-endian, data-type-policy=OVERRIDE, i-signal-type=PRIMITIVE, init-value=0, base-type=BT_KY_Ambex_Entfernung_Delta_IDG_06, compu {phys=raw*0.05 for raw 0..20; unit Unit_Meter}, range phys 0..1 Unit_Meter, raw 0..20, unit=Unit_Meter, transfer-property=TRIGGERED-ON-CHANGE-WITHOUT-REPETITION, to SAM(timeout 5 s)  # Entfernungsabweichung für ID-Geber 6 = Maximale (betragsmäßige) Abweichung von der Distanz in der der ID-Geber gefunden wurde
          signal KY_Ambex_Entfernung_Delta_IDG_07_XIX_Kessy_Ambex_02_XIX_E3V_CCAN: start 30, 5 bit, little-endian, data-type-policy=OVERRIDE, i-signal-type=PRIMITIVE, init-value=0, base-type=BT_KY_Ambex_Entfernung_Delta_IDG_07, compu {phys=raw*0.05 for raw 0..20; unit Unit_Meter}, range phys 0..1 Unit_Meter, raw 0..20, unit=Unit_Meter, transfer-property=TRIGGERED-ON-CHANGE-WITHOUT-REPETITION, to SAM(timeout 5 s)  # Entfernungsabweichung für ID-Geber 7 = Maximale (betragsmäßige) Abweichung von der Distanz in der der ID-Geber gefunden wurde
          signal KY_Ambex_Entfernung_Delta_IDG_08_XIX_Kessy_Ambex_02_XIX_E3V_CCAN: start 35, 5 bit, little-endian, data-type-policy=OVERRIDE, i-signal-type=PRIMITIVE, init-value=0, base-type=BT_KY_Ambex_Entfernung_Delta_IDG_08, compu {phys=raw*0.05 for raw 0..20; unit Unit_Meter}, range phys 0..1 Unit_Meter, raw 0..20, unit=Unit_Meter, transfer-property=TRIGGERED-ON-CHANGE-WITHOUT-REPETITION, to SAM(timeout 5 s)  # Entfernungsabweichung für ID-Geber 8 = Maximale (betragsmäßige) Abweichung von der Distanz in der der ID-Geber gefunden wurde
          signal KY_Ambex_Status_IDG_01_XIX_Kessy_Ambex_02_XIX_E3V_CCAN: start 40, 2 bit, little-endian, data-type-policy=OVERRIDE, i-signal-type=PRIMITIVE, init-value=0, base-type=BT_KY_Ambex_Status_IDG_01, compu {0=Cx0_Init (CM_KY_Ambex_Status_IDG_01_Cx0_Init), 1=Cx1_nicht_gefunden (CM_KY_Ambex_Status_IDG_01_Cx1_nicht_gefunden), 2=Cx2_gefunden_nicht_authentifiziert (CM_KY_Ambex_Status_IDG_01_Cx2_gefunden_nicht_authentifiziert), 3=Cx3_gefunden_authentifiziert (CM_KY_Ambex_Status_IDG_01_Cx3_gefunden_authentifiziert)}, range raw 0..3, transfer-property=TRIGGERED-ON-CHANGE-WITHOUT-REPETITION  # Status des ID-Gebers 1 aus der letzten durchgeführten ID-Geber-Suche
          signal KY_Ambex_Status_IDG_02_XIX_Kessy_Ambex_02_XIX_E3V_CCAN: start 42, 2 bit, little-endian, data-type-policy=OVERRIDE, i-signal-type=PRIMITIVE, init-value=0, base-type=BT_KY_Ambex_Status_IDG_02, compu {0=Cx0_Init (CM_KY_Ambex_Status_IDG_02_Cx0_Init), 1=Cx1_nicht_gefunden (CM_KY_Ambex_Status_IDG_02_Cx1_nicht_gefunden), 2=Cx2_gefunden_nicht_authentifiziert (CM_KY_Ambex_Status_IDG_02_Cx2_gefunden_nicht_authentifiziert), 3=Cx3_gefunden_authentifiziert (CM_KY_Ambex_Status_IDG_02_Cx3_gefunden_authentifiziert)}, range raw 0..3, transfer-property=TRIGGERED-ON-CHANGE-WITHOUT-REPETITION  # Status des ID-Gebers 2 aus der letzten durchgeführten ID-Geber-Suche
          signal KY_Ambex_Status_IDG_03_XIX_Kessy_Ambex_02_XIX_E3V_CCAN: start 44, 2 bit, little-endian, data-type-policy=OVERRIDE, i-signal-type=PRIMITIVE, init-value=0, base-type=BT_KY_Ambex_Status_IDG_03, compu {0=Cx0_Init (CM_KY_Ambex_Status_IDG_03_Cx0_Init), 1=Cx1_nicht_gefunden (CM_KY_Ambex_Status_IDG_03_Cx1_nicht_gefunden), 2=Cx2_gefunden_nicht_authentifiziert (CM_KY_Ambex_Status_IDG_03_Cx2_gefunden_nicht_authentifiziert), 3=Cx3_gefunden_authentifiziert (CM_KY_Ambex_Status_IDG_03_Cx3_gefunden_authentifiziert)}, range raw 0..3, transfer-property=TRIGGERED-ON-CHANGE-WITHOUT-REPETITION  # Status des ID-Gebers 3 aus der letzten durchgeführten ID-Geber-Suche
          signal KY_Ambex_Status_IDG_04_XIX_Kessy_Ambex_02_XIX_E3V_CCAN: start 46, 2 bit, little-endian, data-type-policy=OVERRIDE, i-signal-type=PRIMITIVE, init-value=0, base-type=BT_KY_Ambex_Status_IDG_04, compu {0=Cx0_Init (CM_KY_Ambex_Status_IDG_04_Cx0_Init), 1=Cx1_nicht_gefunden (CM_KY_Ambex_Status_IDG_04_Cx1_nicht_gefunden), 2=Cx2_gefunden_nicht_authentifiziert (CM_KY_Ambex_Status_IDG_04_Cx2_gefunden_nicht_authentifiziert), 3=Cx3_gefunden_authentifiziert (CM_KY_Ambex_Status_IDG_04_Cx3_gefunden_authentifiziert)}, range raw 0..3, transfer-property=TRIGGERED-ON-CHANGE-WITHOUT-REPETITION  # Status des ID-Gebers 4 aus der letzten durchgeführten ID-Geber-Suche
          signal KY_Ambex_Status_IDG_05_XIX_Kessy_Ambex_02_XIX_E3V_CCAN: start 48, 2 bit, little-endian, data-type-policy=OVERRIDE, i-signal-type=PRIMITIVE, init-value=0, base-type=BT_KY_Ambex_Status_IDG_05, compu {0=Cx0_Init (CM_KY_Ambex_Status_IDG_05_Cx0_Init), 1=Cx1_nicht_gefunden (CM_KY_Ambex_Status_IDG_05_Cx1_nicht_gefunden), 2=Cx2_gefunden_nicht_authentifiziert (CM_KY_Ambex_Status_IDG_05_Cx2_gefunden_nicht_authentifiziert), 3=Cx3_gefunden_authentifiziert (CM_KY_Ambex_Status_IDG_05_Cx3_gefunden_authentifiziert)}, range raw 0..3, transfer-property=TRIGGERED-ON-CHANGE-WITHOUT-REPETITION  # Status des ID-Gebers 5 aus der letzten durchgeführten ID-Geber-Suche
          signal KY_Ambex_Status_IDG_06_XIX_Kessy_Ambex_02_XIX_E3V_CCAN: start 50, 2 bit, little-endian, data-type-policy=OVERRIDE, i-signal-type=PRIMITIVE, init-value=0, base-type=BT_KY_Ambex_Status_IDG_06, compu {0=Cx0_Init (CM_KY_Ambex_Status_IDG_06_Cx0_Init), 1=Cx1_nicht_gefunden (CM_KY_Ambex_Status_IDG_06_Cx1_nicht_gefunden), 2=Cx2_gefunden_nicht_authentifiziert (CM_KY_Ambex_Status_IDG_06_Cx2_gefunden_nicht_authentifiziert), 3=Cx3_gefunden_authentifiziert (CM_KY_Ambex_Status_IDG_06_Cx3_gefunden_authentifiziert)}, range raw 0..3, transfer-property=TRIGGERED-ON-CHANGE-WITHOUT-REPETITION  # Status des ID-Gebers 6 aus der letzten durchgeführten ID-Geber-Suche
          signal KY_Ambex_Status_IDG_07_XIX_Kessy_Ambex_02_XIX_E3V_CCAN: start 52, 2 bit, little-endian, data-type-policy=OVERRIDE, i-signal-type=PRIMITIVE, init-value=0, base-type=BT_KY_Ambex_Status_IDG_07, compu {0=Cx0_Init (CM_KY_Ambex_Status_IDG_07_Cx0_Init), 1=Cx1_nicht_gefunden (CM_KY_Ambex_Status_IDG_07_Cx1_nicht_gefunden), 2=Cx2_gefunden_nicht_authentifiziert (CM_KY_Ambex_Status_IDG_07_Cx2_gefunden_nicht_authentifiziert), 3=Cx3_gefunden_authentifiziert (CM_KY_Ambex_Status_IDG_07_Cx3_gefunden_authentifiziert)}, range raw 0..3, transfer-property=TRIGGERED-ON-CHANGE-WITHOUT-REPETITION  # Status des ID-Gebers 7 aus der letzten durchgeführten ID-Geber-Suche
          signal KY_Ambex_Status_IDG_08_XIX_Kessy_Ambex_02_XIX_E3V_CCAN: start 54, 2 bit, little-endian, data-type-policy=OVERRIDE, i-signal-type=PRIMITIVE, init-value=0, base-type=BT_KY_Ambex_Status_IDG_08, compu {0=Cx0_Init (CM_KY_Ambex_Status_IDG_08_Cx0_Init), 1=Cx1_nicht_gefunden (CM_KY_Ambex_Status_IDG_08_Cx1_nicht_gefunden), 2=Cx2_gefunden_nicht_authentifiziert (CM_KY_Ambex_Status_IDG_08_Cx2_gefunden_nicht_authentifiziert), 3=Cx3_gefunden_authentifiziert (CM_KY_Ambex_Status_IDG_08_Cx3_gefunden_authentifiziert)}, range raw 0..3, transfer-property=TRIGGERED-ON-CHANGE-WITHOUT-REPETITION  # Status des ID-Gebers 8 aus der letzten durchgeführten ID-Geber-Suche
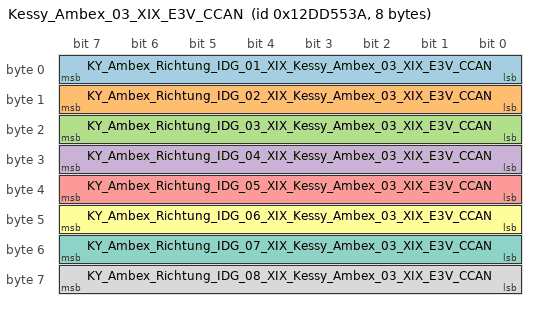
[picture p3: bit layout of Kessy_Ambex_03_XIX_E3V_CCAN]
      frame Kessy_Ambex_03_XIX_E3V_CCAN: id 0x12DD553A, to SAM, frame-length=8, can-addressing-mode=EXTENDED, can-frame-rx-behavior=CAN-20, can-frame-tx-behavior=CAN-20
        pdu Kessy_Ambex_03_XIX_E3V_CCAN: length=8, minimum-delay=0.01, transmission-mode-true-timing={cyclic-timing={time-offset=0.0, time-period=0.5}, event-controlled-timing={number-of-repetitions=0, repetition-period=0.0}}, unused-bit-pattern=0
          signal KY_Ambex_Richtung_IDG_01_XIX_Kessy_Ambex_03_XIX_E3V_CCAN: start 0, 8 bit, little-endian, data-type-policy=OVERRIDE, i-signal-type=PRIMITIVE, init-value=254, base-type=BT_KY_Ambex_Richtung_IDG_01, compu {phys=raw*5-180 for raw 0..72, 254=Cxfe_Init (CM_KY_Ambex_Richtung_IDG_01_Cxfe_Init); unit Unit_DegreOfArc}, range phys -180..180 Unit_DegreOfArc, raw 0..254, unit=Unit_DegreOfArc, transfer-property=TRIGGERED-ON-CHANGE-WITHOUT-REPETITION, to SAM(timeout 5 s)  # Winkelrichtung für ID-Geber 1 = Richtung in der der ID-Geber gefunden wurde
          signal KY_Ambex_Richtung_IDG_02_XIX_Kessy_Ambex_03_XIX_E3V_CCAN: start 8, 8 bit, little-endian, data-type-policy=OVERRIDE, i-signal-type=PRIMITIVE, init-value=254, base-type=BT_KY_Ambex_Richtung_IDG_02, compu {phys=raw*5-180 for raw 0..72, 254=Cxfe_Init (CM_KY_Ambex_Richtung_IDG_02_Cxfe_Init); unit Unit_DegreOfArc}, range phys -180..180 Unit_DegreOfArc, raw 0..254, unit=Unit_DegreOfArc, transfer-property=TRIGGERED-ON-CHANGE-WITHOUT-REPETITION, to SAM(timeout 5 s)  # Winkelrichtung für ID-Geber 2 = Richtung in der der ID-Geber gefunden wurde
          signal KY_Ambex_Richtung_IDG_03_XIX_Kessy_Ambex_03_XIX_E3V_CCAN: start 16, 8 bit, little-endian, data-type-policy=OVERRIDE, i-signal-type=PRIMITIVE, init-value=254, base-type=BT_KY_Ambex_Richtung_IDG_03, compu {phys=raw*5-180 for raw 0..72, 254=Cxfe_Init (CM_KY_Ambex_Richtung_IDG_03_Cxfe_Init); unit Unit_DegreOfArc}, range phys -180..180 Unit_DegreOfArc, raw 0..254, unit=Unit_DegreOfArc, transfer-property=TRIGGERED-ON-CHANGE-WITHOUT-REPETITION, to SAM(timeout 5 s)  # Winkelrichtung für ID-Geber 3 = Richtung in der der ID-Geber gefunden wurde
          signal KY_Ambex_Richtung_IDG_04_XIX_Kessy_Ambex_03_XIX_E3V_CCAN: start 24, 8 bit, little-endian, data-type-policy=OVERRIDE, i-signal-type=PRIMITIVE, init-value=254, base-type=BT_KY_Ambex_Richtung_IDG_04, compu {phys=raw*5-180 for raw 0..72, 254=Cxfe_Init (CM_KY_Ambex_Richtung_IDG_04_Cxfe_Init); unit Unit_DegreOfArc}, range phys -180..180 Unit_DegreOfArc, raw 0..254, unit=Unit_DegreOfArc, transfer-property=TRIGGERED-ON-CHANGE-WITHOUT-REPETITION, to SAM(timeout 5 s)  # Winkelrichtung für ID-Geber 4 = Richtung in der der ID-Geber gefunden wurde
          signal KY_Ambex_Richtung_IDG_05_XIX_Kessy_Ambex_03_XIX_E3V_CCAN: start 32, 8 bit, little-endian, data-type-policy=OVERRIDE, i-signal-type=PRIMITIVE, init-value=254, base-type=BT_KY_Ambex_Richtung_IDG_05, compu {phys=raw*5-180 for raw 0..72, 254=Cxfe_Init (CM_KY_Ambex_Richtung_IDG_05_Cxfe_Init); unit Unit_DegreOfArc}, range phys -180..180 Unit_DegreOfArc, raw 0..254, unit=Unit_DegreOfArc, transfer-property=TRIGGERED-ON-CHANGE-WITHOUT-REPETITION, to SAM(timeout 5 s)  # Winkelrichtung für ID-Geber 5 = Richtung in der der ID-Geber gefunden wurde
          signal KY_Ambex_Richtung_IDG_06_XIX_Kessy_Ambex_03_XIX_E3V_CCAN: start 40, 8 bit, little-endian, data-type-policy=OVERRIDE, i-signal-type=PRIMITIVE, init-value=254, base-type=BT_KY_Ambex_Richtung_IDG_06, compu {phys=raw*5-180 for raw 0..72, 254=Cxfe_Init (CM_KY_Ambex_Richtung_IDG_06_Cxfe_Init); unit Unit_DegreOfArc}, range phys -180..180 Unit_DegreOfArc, raw 0..254, unit=Unit_DegreOfArc, transfer-property=TRIGGERED-ON-CHANGE-WITHOUT-REPETITION, to SAM(timeout 5 s)  # Winkelrichtung für ID-Geber 6 = Richtung in der der ID-Geber gefunden wurde
          signal KY_Ambex_Richtung_IDG_07_XIX_Kessy_Ambex_03_XIX_E3V_CCAN: start 48, 8 bit, little-endian, data-type-policy=OVERRIDE, i-signal-type=PRIMITIVE, init-value=254, base-type=BT_KY_Ambex_Richtung_IDG_07, compu {phys=raw*5-180 for raw 0..72, 254=Cxfe_Init (CM_KY_Ambex_Richtung_IDG_07_Cxfe_Init); unit Unit_DegreOfArc}, range phys -180..180 Unit_DegreOfArc, raw 0..254, unit=Unit_DegreOfArc, transfer-property=TRIGGERED-ON-CHANGE-WITHOUT-REPETITION, to SAM(timeout 5 s)  # Winkelrichtung für ID-Geber 7 = Richtung in der der ID-Geber gefunden wurde
          signal KY_Ambex_Richtung_IDG_08_XIX_Kessy_Ambex_03_XIX_E3V_CCAN: start 56, 8 bit, little-endian, data-type-policy=OVERRIDE, i-signal-type=PRIMITIVE, init-value=254, base-type=BT_KY_Ambex_Richtung_IDG_08, compu {phys=raw*5-180 for raw 0..72, 254=Cxfe_Init (CM_KY_Ambex_Richtung_IDG_08_Cxfe_Init); unit Unit_DegreOfArc}, range phys -180..180 Unit_DegreOfArc, raw 0..254, unit=Unit_DegreOfArc, transfer-property=TRIGGERED-ON-CHANGE-WITHOUT-REPETITION, to SAM(timeout 5 s)  # Winkelrichtung für ID-Geber 8 = Richtung in der der ID-Geber gefunden wurde
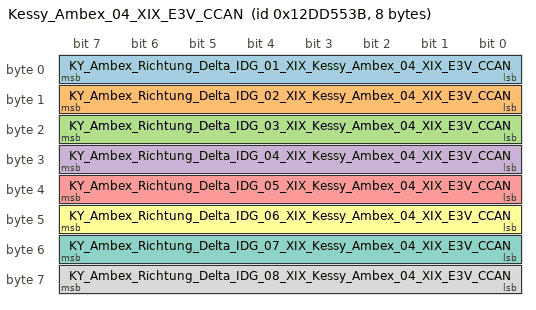
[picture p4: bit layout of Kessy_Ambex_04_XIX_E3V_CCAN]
      frame Kessy_Ambex_04_XIX_E3V_CCAN: id 0x12DD553B, to SAM, frame-length=8, can-addressing-mode=EXTENDED, can-frame-rx-behavior=CAN-20, can-frame-tx-behavior=CAN-20
        pdu Kessy_Ambex_04_XIX_E3V_CCAN: length=8, minimum-delay=0.01, transmission-mode-true-timing={cyclic-timing={time-offset=0.0, time-period=0.5}, event-controlled-timing={number-of-repetitions=0, repetition-period=0.0}}, unused-bit-pattern=0
          signal KY_Ambex_Richtung_Delta_IDG_01_XIX_Kessy_Ambex_04_XIX_E3V_CCAN: start 0, 8 bit, little-endian, data-type-policy=OVERRIDE, i-signal-type=PRIMITIVE, init-value=0, base-type=BT_KY_Ambex_Richtung_Delta_IDG_01, compu {phys=raw for raw 0..90; unit Unit_DegreOfArc}, range phys 0..90 Unit_DegreOfArc, raw 0..90, unit=Unit_DegreOfArc, transfer-property=TRIGGERED-ON-CHANGE-WITHOUT-REPETITION, to SAM(timeout 5 s)  # Winkelabweichung für ID-Geber 1 = Maximale (betragsmäßige) Abweichung von der Richtung in der der ID-Geber gefunden wurde
          signal KY_Ambex_Richtung_Delta_IDG_02_XIX_Kessy_Ambex_04_XIX_E3V_CCAN: start 8, 8 bit, little-endian, data-type-policy=OVERRIDE, i-signal-type=PRIMITIVE, init-value=0, base-type=BT_KY_Ambex_Richtung_Delta_IDG_02, compu {phys=raw for raw 0..90; unit Unit_DegreOfArc}, range phys 0..90 Unit_DegreOfArc, raw 0..90, unit=Unit_DegreOfArc, transfer-property=TRIGGERED-ON-CHANGE-WITHOUT-REPETITION, to SAM(timeout 5 s)  # Winkelabweichung für ID-Geber 2 = Maximale (betragsmäßige) Abweichung von der Richtung in der der ID-Geber gefunden wurde
          signal KY_Ambex_Richtung_Delta_IDG_03_XIX_Kessy_Ambex_04_XIX_E3V_CCAN: start 16, 8 bit, little-endian, data-type-policy=OVERRIDE, i-signal-type=PRIMITIVE, init-value=0, base-type=BT_KY_Ambex_Richtung_Delta_IDG_03, compu {phys=raw for raw 0..90; unit Unit_DegreOfArc}, range phys 0..90 Unit_DegreOfArc, raw 0..90, unit=Unit_DegreOfArc, transfer-property=TRIGGERED-ON-CHANGE-WITHOUT-REPETITION, to SAM(timeout 5 s)  # Winkelabweichung für ID-Geber 3 = Maximale (betragsmäßige) Abweichung von der Richtung in der der ID-Geber gefunden wurde
          signal KY_Ambex_Richtung_Delta_IDG_04_XIX_Kessy_Ambex_04_XIX_E3V_CCAN: start 24, 8 bit, little-endian, data-type-policy=OVERRIDE, i-signal-type=PRIMITIVE, init-value=0, base-type=BT_KY_Ambex_Richtung_Delta_IDG_04, compu {phys=raw for raw 0..90; unit Unit_DegreOfArc}, range phys 0..90 Unit_DegreOfArc, raw 0..90, unit=Unit_DegreOfArc, transfer-property=TRIGGERED-ON-CHANGE-WITHOUT-REPETITION, to SAM(timeout 5 s)  # Winkelabweichung für ID-Geber 4 = Maximale (betragsmäßige) Abweichung von der Richtung in der der ID-Geber gefunden wurde
          signal KY_Ambex_Richtung_Delta_IDG_05_XIX_Kessy_Ambex_04_XIX_E3V_CCAN: start 32, 8 bit, little-endian, data-type-policy=OVERRIDE, i-signal-type=PRIMITIVE, init-value=0, base-type=BT_KY_Ambex_Richtung_Delta_IDG_05, compu {phys=raw for raw 0..90; unit Unit_DegreOfArc}, range phys 0..90 Unit_DegreOfArc, raw 0..90, unit=Unit_DegreOfArc, transfer-property=TRIGGERED-ON-CHANGE-WITHOUT-REPETITION, to SAM(timeout 5 s)  # Winkelabweichung für ID-Geber 5 = Maximale (betragsmäßige) Abweichung von der Richtung in der der ID-Geber gefunden wurde
          signal KY_Ambex_Richtung_Delta_IDG_06_XIX_Kessy_Ambex_04_XIX_E3V_CCAN: start 40, 8 bit, little-endian, data-type-policy=OVERRIDE, i-signal-type=PRIMITIVE, init-value=0, base-type=BT_KY_Ambex_Richtung_Delta_IDG_06, compu {phys=raw for raw 0..90; unit Unit_DegreOfArc}, range phys 0..90 Unit_DegreOfArc, raw 0..90, unit=Unit_DegreOfArc, transfer-property=TRIGGERED-ON-CHANGE-WITHOUT-REPETITION, to SAM(timeout 5 s)  # Winkelabweichung für ID-Geber 6 = Maximale (betragsmäßige) Abweichung von der Richtung in der der ID-Geber gefunden wurde
          signal KY_Ambex_Richtung_Delta_IDG_07_XIX_Kessy_Ambex_04_XIX_E3V_CCAN: start 48, 8 bit, little-endian, data-type-policy=OVERRIDE, i-signal-type=PRIMITIVE, init-value=0, base-type=BT_KY_Ambex_Richtung_Delta_IDG_07, compu {phys=raw for raw 0..90; unit Unit_DegreOfArc}, range phys 0..90 Unit_DegreOfArc, raw 0..90, unit=Unit_DegreOfArc, transfer-property=TRIGGERED-ON-CHANGE-WITHOUT-REPETITION, to SAM(timeout 5 s)  # Winkelabweichung für ID-Geber 7 = Maximale (betragsmäßige) Abweichung von der Richtung in der der ID-Geber gefunden wurde
          signal KY_Ambex_Richtung_Delta_IDG_08_XIX_Kessy_Ambex_04_XIX_E3V_CCAN: start 56, 8 bit, little-endian, data-type-policy=OVERRIDE, i-signal-type=PRIMITIVE, init-value=0, base-type=BT_KY_Ambex_Richtung_Delta_IDG_08, compu {phys=raw for raw 0..90; unit Unit_DegreOfArc}, range phys 0..90 Unit_DegreOfArc, raw 0..90, unit=Unit_DegreOfArc, transfer-property=TRIGGERED-ON-CHANGE-WITHOUT-REPETITION, to SAM(timeout 5 s)  # Winkelabweichung für ID-Geber 8 = Maximale (betragsmäßige) Abweichung von der Richtung in der der ID-Geber gefunden wurde
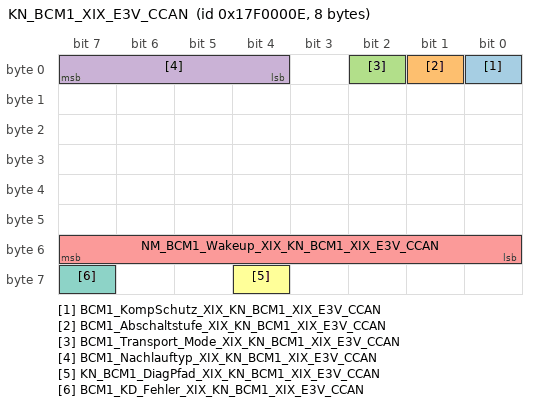
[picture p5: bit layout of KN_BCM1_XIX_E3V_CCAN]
      frame KN_BCM1_XIX_E3V_CCAN: id 0x17F0000E, from SAM, frame-length=8, can-addressing-mode=EXTENDED, can-frame-rx-behavior=CAN-20, can-frame-tx-behavior=CAN-20
        pdu KN_BCM1_XIX_E3V_CCAN: length=8, transmission-mode-true-timing=cyclic-timing={time-offset=0.0, time-period=0.5}, unused-bit-pattern=0
          signal BCM1_KompSchutz_XIX_KN_BCM1_XIX_E3V_CCAN: start 0, 1 bit, little-endian, data-type-policy=OVERRIDE, i-signal-type=PRIMITIVE, init-value=0, base-type=BT_BCM1_KompSchutz, compu {0=Cx0_inaktiv (CM_BCM1_KompSchutz_Cx0_inaktiv), 1=Cx1_aktiv (CM_BCM1_KompSchutz_Cx1_aktiv)}, range raw 0..1, transfer-property=PENDING  # Funktionseinschränkung aufgrund Komponentenschutz aktiv
          signal BCM1_Abschaltstufe_XIX_KN_BCM1_XIX_E3V_CCAN: start 1, 1 bit, little-endian, data-type-policy=OVERRIDE, i-signal-type=PRIMITIVE, init-value=0, base-type=BT_BCM1_Abschaltstufe, compu {0=Cx0_keine_Einschraenkung (CM_BCM1_Abschaltstufe_Cx0_keine_Einschraenkung), 1=Cx1_Funktionseinschraenkung (CM_BCM1_Abschaltstufe_Cx1_Funktionseinschraenkung)}, range raw 0..1, transfer-property=PENDING  # Funktionseinschränkung aufgrund aktiver Abschaltstufe
          signal BCM1_Transport_Mode_XIX_KN_BCM1_XIX_E3V_CCAN: start 2, 1 bit, little-endian, data-type-policy=OVERRIDE, i-signal-type=PRIMITIVE, init-value=0, base-type=BT_BCM1_Transport_Mode, compu {0=Cx0_keine_Einschraenkung (CM_BCM1_Transport_Mode_Cx0_keine_Einschraenkung), 1=Cx1_Funktionseinschraenkung (CM_BCM1_Transport_Mode_Cx1_Funktionseinschraenkung)}, range raw 0..1, transfer-property=PENDING  # Funktionseinschränkung aufgrund aktivem Transport Mode und/oder Transport Schutz
          signal BCM1_Nachlauftyp_XIX_KN_BCM1_XIX_E3V_CCAN: start 4, 4 bit, little-endian, data-type-policy=OVERRIDE, i-signal-type=PRIMITIVE, init-value=2, base-type=BT_BCM1_Nachlauftyp, compu {0=Cx0_Komm_bei_KL15_EIN (CM_BCM1_Nachlauftyp_Cx0_Komm_bei_KL15_EIN), 1=Cx1_Komm_nach_KL15_AUS (CM_BCM1_Nachlauftyp_Cx1_Komm_nach_KL15_AUS), 2=Cx2_Komm_bei_KL15_AUS (CM_BCM1_Nachlauftyp_Cx2_Komm_bei_KL15_AUS)}, range raw 0..2, transfer-property=PENDING  # Abgebildet wird die von der Hardware vorgegebene Möglichkeit, die Kommunikation nach Klemme 15 = AUS aufrecht zu erhalten. Es wird ein Init-Wert gesendet.
          signal NM_BCM1_Wakeup_XIX_KN_BCM1_XIX_E3V_CCAN: start 48, 8 bit, little-endian, data-type-policy=OVERRIDE, i-signal-type=PRIMITIVE, init-value=0, base-type=BT_NM_BCM1_Wakeup, compu {0=Cx0_Peripherie_Wakeup_Ursache_nicht_bekannt (CM_NM_BCM1_Wakeup_Cx0_Peripherie_Wakeup_Ursache_nicht_bekannt) (Peripherie_Wakeup__Ursache_nicht_bekannt), 1=Cx1_CAN_Wakeup (CM_NM_BCM1_Wakeup_Cx1_CAN_Wakeup), 2=Cx2_KL15_HW (CM_NM_BCM1_Wakeup_Cx2_KL15_HW), 3=Cx3_KL30 (CM_NM_BCM1_Wakeup_Cx3_KL30), 4=Cx4_KL58_xs_xt_xd (CM_NM_BCM1_Wakeup_Cx4_KL58_xs_xt_xd), 5=Cx5_Warnblinktaster_EIN (CM_NM_BCM1_Wakeup_Cx5_Warnblinktaster_EIN), 6=Cx6_LDS_Standlicht (CM_NM_BCM1_Wakeup_Cx6_LDS_Standlicht), 7=Cx7_Klemme_S (CM_NM_BCM1_Wakeup_Cx7_Klemme_S), 8=Cx8_Lock_Unlock_Taster (CM_NM_BCM1_Wakeup_Cx8_Lock_Unlock_Taster), 9=Cx9_Heckdeckel_Grifftaster (CM_NM_BCM1_Wakeup_Cx9_Heckdeckel_Grifftaster), 10=Cxa_Funkbefehl (CM_NM_BCM1_Wakeup_Cxa_Funkbefehl), 11=Cxb_Drehfalle_HL (CM_NM_BCM1_Wakeup_Cxb_Drehfalle_HL), 12=Cxc_Drehfalle_HR (CM_NM_BCM1_Wakeup_Cxc_Drehfalle_HR), 13=Cxd_Motorhaubenkontakt (CM_NM_BCM1_Wakeup_Cxd_Motorhaubenkontakt), 14=Cxe_Heckdeckel_Vorraste (CM_NM_BCM1_Wakeup_Cxe_Heckdeckel_Vorraste), 15=Cxf_Heckdeckel_Hauptraste (CM_NM_BCM1_Wakeup_Cxf_Heckdeckel_Hauptraste), 16=Cx10_LDS_Abblendlicht (CM_NM_BCM1_Wakeup_Cx10_LDS_Abblendlicht), 17=Cx11_Drehfalle_FT (CM_NM_BCM1_Wakeup_Cx11_Drehfalle_FT), 18=Cx12_Drehfalle_BT (CM_NM_BCM1_Wakeup_Cx12_Drehfalle_BT), 19=Cx13_Kessy_Schluessel_erkannt (CM_NM_BCM1_Wakeup_Cx13_Kessy_Schluessel_erkannt), 20=Cx14_Heckdeckel_Entriegelungstaster (CM_NM_BCM1_Wakeup_Cx14_Heckdeckel_Entriegelungstaster), 21=Cx15_Schlossrueckmeldung_HL (CM_NM_BCM1_Wakeup_Cx15_Schlossrueckmeldung_HL), 22=Cx16_Schlossrueckmeldung_HR (CM_NM_BCM1_Wakeup_Cx16_Schlossrueckmeldung_HR), 23=Cx17_Lichthupe (CM_NM_BCM1_Wakeup_Cx17_Lichthupe), 25=Cx19_DWA_Heckscheibenbruch (CM_NM_BCM1_Wakeup_Cx19_DWA_Heckscheibenbruch), 26=Cx1a_LIN1 (CM_NM_BCM1_Wakeup_Cx1a_LIN1), 27=Cx1b_LIN2 (CM_NM_BCM1_Wakeup_Cx1b_LIN2), 28=Cx1c_LIN3 (CM_NM_BCM1_Wakeup_Cx1c_LIN3), 29=Cx1d_LIN4 (CM_NM_BCM1_Wakeup_Cx1d_LIN4), 30=Cx1e_LIN5 (CM_NM_BCM1_Wakeup_Cx1e_LIN5), 31=Cx1f_LIN6 (CM_NM_BCM1_Wakeup_Cx1f_LIN6), 33=Cx21_LIN8 (CM_NM_BCM1_Wakeup_Cx21_LIN8), 36=Cx24_LDS_Nebellicht_Nebelschlusslicht (CM_NM_BCM1_Wakeup_Cx24_LDS_Nebellicht_Nebelschlusslicht), 37=Cx25_Valet_Taster (CM_NM_BCM1_Wakeup_Cx25_Valet_Taster), 38=Cx26_Scheinwerferdiebstahlueberwachung (CM_NM_BCM1_Wakeup_Cx26_Scheinwerferdiebstahlueberwachung), 39=Cx27_Versorgung_Innenlicht_KL30g (CM_NM_BCM1_Wakeup_Cx27_Versorgung_Innenlicht_KL30g), 40=Cx28_Display_Taster (CM_NM_BCM1_Wakeup_Cx28_Display_Taster), 41=Cx29_RearMode_Taster (CM_NM_BCM1_Wakeup_Cx29_RearMode_Taster), 42=Cx2a_SAD_Taster (CM_NM_BCM1_Wakeup_Cx2a_SAD_Taster), 43=Cx2b_Rollo_Taster (CM_NM_BCM1_Wakeup_Cx2b_Rollo_Taster), 44=Cx2c_bCall_Taster (CM_NM_BCM1_Wakeup_Cx2c_bCall_Taster), 45=Cx2d_eCall_Taster (CM_NM_BCM1_Wakeup_Cx2d_eCall_Taster), 46=Cx2e_Sitzpneumatikregler (CM_NM_BCM1_Wakeup_Cx2e_Sitzpneumatikregler), 47=Cx2f_Signalhorn (CM_NM_BCM1_Wakeup_Cx2f_Signalhorn), 48=Cx30_Zustandswechsel_ZV_BEV_PHEV (CM_NM_BCM1_Wakeup_Cx30_Zustandswechsel_ZV_BEV_PHEV), 49=Cx31_Ladesteckerentriegelung_BEV_PHEV (CM_NM_BCM1_Wakeup_Cx31_Ladesteckerentriegelung_BEV_PHEV), 50=Cx32_LIN10_WakeUp (CM_NM_BCM1_Wakeup_Cx32_LIN10_WakeUp), 51=Cx33_Taster_Laderaumschliessung (CM_NM_BCM1_Wakeup_Cx33_Taster_Laderaumschliessung), 52=Cx34_STH_Taster (CM_NM_BCM1_Wakeup_Cx34_STH_Taster), 53=Cx35_Defrost_Taster_Betaetigt (CM_NM_BCM1_Wakeup_Cx35_Defrost_Taster_Betaetigt), 54=Cx36_Ladesteckerverriegelung_BEV_PHEV (CM_NM_BCM1_Wakeup_Cx36_Ladesteckerverriegelung_BEV_PHEV), 55=Cx37_TuerInnenGriff_HBFS (CM_NM_BCM1_Wakeup_Cx37_TuerInnenGriff_HBFS), 56=Cx38_TuerInnenGriff_HFS (CM_NM_BCM1_Wakeup_Cx38_TuerInnenGriff_HFS), 57=Cx39_TuerAussenGriff_HBFS (CM_NM_BCM1_Wakeup_Cx39_TuerAussenGriff_HBFS), 58=Cx3a_TuerAussenGriff_HFS (CM_NM_BCM1_Wakeup_Cx3a_TuerAussenGriff_HFS), 60=Cx3c_LIN7_WakeUp (CM_NM_BCM1_Wakeup_Cx3c_LIN7_WakeUp), 61=Cx3d_LIN9_WakeUp (CM_NM_BCM1_Wakeup_Cx3d_LIN9_WakeUp), 62=Cx3e_LIN11_WakeUp (CM_NM_BCM1_Wakeup_Cx3e_LIN11_WakeUp), 63=Cx3f_LIN12_WakeUp (CM_NM_BCM1_Wakeup_Cx3f_LIN12_WakeUp), 64=Cx40_LIN13_WakeUp (CM_NM_BCM1_Wakeup_Cx40_LIN13_WakeUp), 65=Cx41_LIN14_WakeUp (CM_NM_BCM1_Wakeup_Cx41_LIN14_WakeUp), 128=Cx80_ZV_Wiederverriegelung (CM_NM_BCM1_Wakeup_Cx80_ZV_Wiederverriegelung), 129=Cx81_Coming_Home_Ende (CM_NM_BCM1_Wakeup_Cx81_Coming_Home_Ende), 130=Cx82_Leaving_Home_Ende (CM_NM_BCM1_Wakeup_Cx82_Leaving_Home_Ende), 131=Cx83_Softtouch_Freigabe_entziehen (CM_NM_BCM1_Wakeup_Cx83_Softtouch_Freigabe_entziehen), 132=Cx84_Fensterheber_Freigabe_entziehen (CM_NM_BCM1_Wakeup_Cx84_Fensterheber_Freigabe_entziehen), 133=Cx85_Schiebedach_Freigabe_entziehen (CM_NM_BCM1_Wakeup_Cx85_Schiebedach_Freigabe_entziehen), 134=Cx86_Verdeck_Freigabe_entziehen (CM_NM_BCM1_Wakeup_Cx86_Verdeck_Freigabe_entziehen), 135=Cx87_ELV_Freigabe (CM_NM_BCM1_Wakeup_Cx87_ELV_Freigabe), 136=Cx88_KL58xt_Ende (CM_NM_BCM1_Wakeup_Cx88_KL58xt_Ende), 137=Cx89_IRUE_Ausloesung (CM_NM_BCM1_Wakeup_Cx89_IRUE_Ausloesung), 138=Cx8a_NGS_Ausloesung (CM_NM_BCM1_Wakeup_Cx8a_NGS_Ausloesung), 139=Cx8b_Sounder_Alarm (CM_NM_BCM1_Wakeup_Cx8b_Sounder_Alarm), 140=Cx8c_Regenschliessen (CM_NM_BCM1_Wakeup_Cx8c_Regenschliessen), 141=Cx8d_Remotestart (CM_NM_BCM1_Wakeup_Cx8d_Remotestart), 142=Cx8e_Lichtwarnung_Ende (CM_NM_BCM1_Wakeup_Cx8e_Lichtwarnung_Ende), 143=Cx8f_DWA_Alarm (CM_NM_BCM1_Wakeup_Cx8f_DWA_Alarm), 144=Cx90_Innenlicht (CM_NM_BCM1_Wakeup_Cx90_Innenlicht), 145=Cx91_Tankklappe_wurde_geschlossen (CM_NM_BCM1_Wakeup_Cx91_Tankklappe_wurde_geschlossen), 146=Cx92_Parklicht (CM_NM_BCM1_Wakeup_Cx92_Parklicht), 147=Cx93_Klimafunktion (CM_NM_BCM1_Wakeup_Cx93_Klimafunktion), 148=Cx94_Standlicht (CM_NM_BCM1_Wakeup_Cx94_Standlicht), 149=Cx95_Tankklappe_wurde_geoeffnet (CM_NM_BCM1_Wakeup_Cx95_Tankklappe_wurde_geoeffnet), 150=Cx96_SAFE_LED (CM_NM_BCM1_Wakeup_Cx96_SAFE_LED), 151=Cx97_ZV_TAG_aus_einfahren (CM_NM_BCM1_Wakeup_Cx97_ZV_TAG_aus_einfahren), 152=Cx98_CPD_Nutzerwarnung (CM_NM_BCM1_Wakeup_Cx98_CPD_Nutzerwarnung), 254=Cxfe_Watchdog_Test (CM_NM_BCM1_Wakeup_Cxfe_Watchdog_Test), 255=Cxff_Entwicklungsursache (CM_NM_BCM1_Wakeup_Cxff_Entwicklungsursache)}, range raw 0..255, transfer-property=PENDING  # enthält die Weckursache; stehen mehrere Weckursachen parallel an, dann muss der kleinste Wert übertragen werden
          signal KN_BCM1_DiagPfad_XIX_KN_BCM1_XIX_E3V_CCAN: start 60, 1 bit, little-endian, data-type-policy=OVERRIDE, i-signal-type=PRIMITIVE, init-value=0, base-type=BT_KN_BCM1_DiagPfad, compu {0=Cx0_aktiv (CM_KN_BCM1_DiagPfad_Cx0_aktiv), 1=Cx1_inaktiv (CM_KN_BCM1_DiagPfad_Cx1_inaktiv)}, range raw 0..1, transfer-property=PENDING  # Kennzeichnung der Diagnosefähigkeit des BusInterfaces eines Steuergerätes (Knoten) Umfang LAH 80127 Bei Nutzung des Signal explizit pro angebundenem BusInterface zu setzen: MQB auf K-CAN = 0 (aktiv) MQB2020 auf K-CAN = 0 (aktiv) MLBevo Gen1 auf K-CAN = 0 (aktiv) MLBevo Gen2 auf K2-CAN = 0 (aktiv) MQBw_Baseline auf K2-CANFD = 0 (aktiv) E3_1_1_MEB auf K-CAN = 0 (aktiv) E3_1_1_UNECE auf K2-CANFD = 0 (aktiv)
          signal BCM1_KD_Fehler_XIX_KN_BCM1_XIX_E3V_CCAN: start 63, 1 bit, little-endian, data-type-policy=OVERRIDE, i-signal-type=PRIMITIVE, init-value=0, base-type=BT_BCM1_KD_Fehler, compu {0=Cx0_Kein_KD_Fehler (CM_BCM1_KD_Fehler_Cx0_Kein_KD_Fehler), 1=Cx1_KD_Fehler (CM_BCM1_KD_Fehler_Cx1_KD_Fehler)}, range raw 0..1, transfer-property=PENDING  # Bei gesetztem Bit ist mindestens ein Kundendienstfehler eingetragen
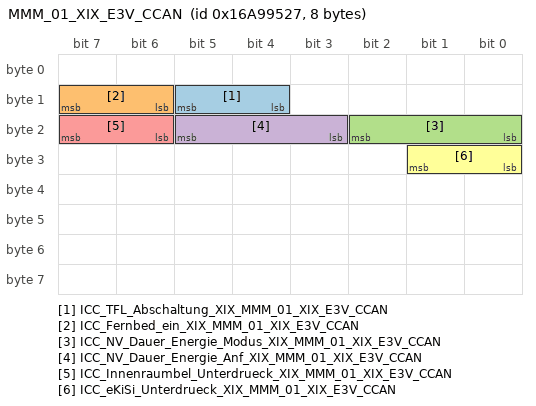
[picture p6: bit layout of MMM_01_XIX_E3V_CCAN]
      frame MMM_01_XIX_E3V_CCAN: id 0x16A99527, to SAM, frame-length=8, can-addressing-mode=EXTENDED, can-frame-rx-behavior=CAN-20, can-frame-tx-behavior=CAN-20
        pdu MMM_01_XIX_E3V_CCAN: length=8, transmission-mode-true-timing=cyclic-timing={time-offset=0, time-period=0.2}, unused-bit-pattern=0
          signal ICC_TFL_Abschaltung_XIX_MMM_01_XIX_E3V_CCAN: start 12, 2 bit, little-endian, data-type-policy=OVERRIDE, i-signal-type=PRIMITIVE, init-value=3, base-type=BT_ICC_TFL_Abschaltung, invalid-value=Invalid_ICC_TFL_Abschaltung_XIX_MMM_01_XIX_E3V_CCAN:2, compu {0=Cx0_inaktiv (CM_ICC_TFL_Abschaltung_Cx0_inaktiv), 1=Cx1_aktiv (CM_ICC_TFL_Abschaltung_Cx1_aktiv), 2=Cx2_Fehler (CM_ICC_TFL_Abschaltung_Cx2_Fehler), 3=Cx3_Init (CM_ICC_TFL_Abschaltung_Cx3_Init)}, range raw 0..3, transfer-property=PENDING  # Abschaltung des Tagfahrlicht 0 = keine Auswirkung 1 = Tagfahrlicht deaktiviert
          signal ICC_Fernbed_ein_XIX_MMM_01_XIX_E3V_CCAN: start 14, 2 bit, little-endian, data-type-policy=OVERRIDE, i-signal-type=PRIMITIVE, init-value=3, base-type=BT_ICC_Fernbed_ein, invalid-value=Invalid_ICC_Fernbed_ein_XIX_MMM_01_XIX_E3V_CCAN:2, compu {0=Cx0_inaktiv (CM_ICC_Fernbed_ein_Cx0_inaktiv), 1=Cx1_aktiv (CM_ICC_Fernbed_ein_Cx1_aktiv), 2=Cx2_Fehler (CM_ICC_Fernbed_ein_Cx2_Fehler), 3=Cx3_Init (CM_ICC_Fernbed_ein_Cx3_Init)}, range raw 0..3, transfer-property=PENDING, to SAM(timeout 2 s)  # Fernbedienung für Petri+Lehr; Versehrte und Fahrschule
          signal ICC_NV_Dauer_Energie_Modus_XIX_MMM_01_XIX_E3V_CCAN: start 16, 3 bit, little-endian, data-type-policy=OVERRIDE, i-signal-type=PRIMITIVE, init-value=7, base-type=BT_ICC_NV_Dauer_Energie_Modus, invalid-value=Invalid_ICC_NV_Dauer_Energie_Modus_XIX_MMM_01_XIX_E3V_CCAN:6, compu {0=Cx0_Kein_Modus (CM_ICC_NV_Dauer_Energie_Modus_Cx0_Kein_Modus), 1=Cx1_Comfort (CM_ICC_NV_Dauer_Energie_Modus_Cx1_Comfort), 2=Cx2_Camping (CM_ICC_NV_Dauer_Energie_Modus_Cx2_Camping), 3=Cx3_Pet (CM_ICC_NV_Dauer_Energie_Modus_Cx3_Pet), 6=Cx6_Fehler (CM_ICC_NV_Dauer_Energie_Modus_Cx6_Fehler), 7=Cx7_Init (CM_ICC_NV_Dauer_Energie_Modus_Cx7_Init)}, range raw 0..7, transfer-property=PENDING  # Aktiver Modus, für den eine dauerhafte oder längerfristige Versrogung des 12V-Bordnetzes außerhalb des Fahrbetriebs benötigt wird.
          signal ICC_NV_Dauer_Energie_Anf_XIX_MMM_01_XIX_E3V_CCAN: start 19, 3 bit, little-endian, data-type-policy=OVERRIDE, i-signal-type=PRIMITIVE, init-value=7, base-type=BT_ICC_NV_Dauer_Energie_Anf, invalid-value=Invalid_ICC_NV_Dauer_Energie_Anf_XIX_MMM_01_XIX_E3V_CCAN:6, compu {0=Cx0_Keine_Anforderung (CM_ICC_NV_Dauer_Energie_Anf_Cx0_Keine_Anforderung), 1=Cx1_Automatisches_Nachladen (CM_ICC_NV_Dauer_Energie_Anf_Cx1_Automatisches_Nachladen), 2=Cx2_Sofort_Nachladen (CM_ICC_NV_Dauer_Energie_Anf_Cx2_Sofort_Nachladen), 3=Cx3_Dauerhafte_Versorgung (CM_ICC_NV_Dauer_Energie_Anf_Cx3_Dauerhafte_Versorgung), 6=Cx6_Fehler (CM_ICC_NV_Dauer_Energie_Anf_Cx6_Fehler), 7=Cx7_Init (CM_ICC_NV_Dauer_Energie_Anf_Cx7_Init)}, range raw 0..7, transfer-property=PENDING  # Anforderung zur dauerhaften oder längerfristigen Versorgung des 12V-Bordnetzes außerhalb des Fahrbetriebs.
          signal ICC_Innenraumbel_Unterdrueck_XIX_MMM_01_XIX_E3V_CCAN: start 22, 2 bit, little-endian, data-type-policy=OVERRIDE, i-signal-type=PRIMITIVE, init-value=3, base-type=BT_ICC_Innenraumbel_Unterdrueck, invalid-value=Invalid_ICC_Innenraumbel_Unterdrueck_XIX_MMM_01_XIX_E3V_CCAN:2, compu {0=Cx0_inaktiv (CM_ICC_Innenraumbel_Unterdrueck_Cx0_inaktiv), 1=Cx1_aktiv (CM_ICC_Innenraumbel_Unterdrueck_Cx1_aktiv), 2=Cx2_Fehler (CM_ICC_Innenraumbel_Unterdrueck_Cx2_Fehler), 3=Cx3_Init (CM_ICC_Innenraumbel_Unterdrueck_Cx3_Init)}, range raw 0..3, transfer-property=PENDING, to SAM(timeout 2 s)  # Unterdrückung des Innenlichts/Fussraumbeleuchtung, sowie Schließblinken
          signal ICC_eKiSi_Unterdrueck_XIX_MMM_01_XIX_E3V_CCAN: start 24, 2 bit, little-endian, data-type-policy=OVERRIDE, i-signal-type=PRIMITIVE, init-value=3, base-type=BT_ICC_eKiSi_Unterdrueck, compu {0=Cx0_FALSE (CM_ICC_eKiSi_Unterdrueck_Cx0_FALSE), 1=Cx1_TRUE (CM_ICC_eKiSi_Unterdrueck_Cx1_TRUE), 2=Cx2_ERROR (CM_ICC_eKiSi_Unterdrueck_Cx2_ERROR), 3=Cx3_INIT (CM_ICC_eKiSi_Unterdrueck_Cx3_INIT)}, range raw 0..3, transfer-property=PENDING, to SAM(timeout 2 s)  # Deaktivieren Kinderschutz bei aktivem Campingmodus
      frame NMH_BCM1_XIX_E3V_CCAN: id 0x1B00000E, from SAM, frame-length=8, can-addressing-mode=EXTENDED, can-frame-rx-behavior=CAN-20, can-frame-tx-behavior=CAN-20, rx-identifier-range={lower-can-id=452984832, upper-can-id=452985855}
        nm pdu NMH_BCM1_XIX_E3V_CCAN: length=8, unused-bit-pattern=0
          signal NM_BCM1_CBV_AWB_XIX_NMH_BCM1_XIX_E3V_CCAN: start 12, 1 bit, little-endian, data-type-policy=OVERRIDE, i-signal-type=PRIMITIVE, init-value=0, base-type=BT_NM_BCM1_CBV_AWB, compu {0=Cx0_Passiver_WakeUp (CM_NM_BCM1_CBV_AWB_Cx0_Passiver_WakeUp), 1=Cx1_Aktiver_WakeUp (CM_NM_BCM1_CBV_AWB_Cx1_Aktiver_WakeUp)}, range raw 0..1, transfer-property=TRIGGERED  # Das Signal ist zu setzen, wenn das SG aktiv den Bus geweckt hat 0 = Passiver_WakeUp = SG hat das Netzwerk nicht aktiv geweckt 1 = Akitiver_WakeUp = SG hat das Netzwerk aktiv geweckt
          signal NM_BCM1_CBV_CRI_XIX_NMH_BCM1_XIX_E3V_CCAN: start 14, 1 bit, little-endian, data-type-policy=OVERRIDE, i-signal-type=PRIMITIVE, base-type=BT_NM_BCM1_CBV_CRI, compu {0=Cx0_NM_ohne_Clusteranforderungen (CM_NM_BCM1_CBV_CRI_Cx0_NM_ohne_Clusteranforderungen), 1=Cx1_NM_mit_Clusteranforderungen (CM_NM_BCM1_CBV_CRI_Cx1_NM_mit_Clusteranforderungen)}, range raw 0..1, transfer-property=TRIGGERED  # Das Signal ist dauerhaft gesetzt, wenn das NM-Layout Cluster- Anforderungen enthält
          signal NM_BCM1_NM_State_XIX_NMH_BCM1_XIX_E3V_CCAN: start 16, 6 bit, little-endian, data-type-policy=OVERRIDE, i-signal-type=PRIMITIVE, init-value=0, base-type=BT_NM_BCM1_NM_State, compu {0=Cx0_Init (CM_NM_BCM1_NM_State_Cx0_Init), 1=Cx1_NM_RM_aus_BSM (CM_NM_BCM1_NM_State_Cx1_NM_RM_aus_BSM), 2=Cx2_NM_RM_aus_PBSM (CM_NM_BCM1_NM_State_Cx2_NM_RM_aus_PBSM), 4=Cx4_NM_NO_aus_RM (CM_NM_BCM1_NM_State_Cx4_NM_NO_aus_RM), 8=Cx8_NM_NO_aus_RS (CM_NM_BCM1_NM_State_Cx8_NM_NO_aus_RS), 16=Cx10_reserved (CM_NM_BCM1_NM_State_Cx10_reserved), 32=Cx20_reserved (CM_NM_BCM1_NM_State_Cx20_reserved)}, range raw 0..32, transfer-property=TRIGGERED  # 1 = Zustand Repeat Message (<-- Bus-Sleep Mode) 2 = Zustand Repeat Message (<-- Prepare Bus-Sleep Mode) 4 = Zustand Normal Operation (<-- Repeat Message) 8 = Zustand Normal Operation (<-- Ready Sleep)
          signal NM_BCM1_Car_Wakeup_XIX_NMH_BCM1_XIX_E3V_CCAN: start 22, 1 bit, little-endian, data-type-policy=OVERRIDE, i-signal-type=PRIMITIVE, init-value=0, base-type=BT_NM_BCM1_Car_Wakeup, compu {0=Cx0_Inaktiv (CM_NM_BCM1_Car_Wakeup_Cx0_Inaktiv), 1=Cx1_Car_Wakeup (CM_NM_BCM1_Car_Wakeup_Cx1_Car_Wakeup)}, range raw 0..1, transfer-property=TRIGGERED  # Car Wakeup (Gateway wertet aus) MQB: -Kl.58xd, Kl.58xs, Kl.58xt eingeschaltet oder ausgeschaltet oder Dimmungssignal wurde vom Kunden geändert (nicht vom Fototransistor) -S-Kontakt wurde ein- oder ausgeschaltet -Remotestartbetrieb -Tankklappe wurde geschlossen (Drucktank) -ValetParking-Taster MQB BEV/PHEV: -Zustandswechsel_ZV -Ladesteckerentriegelung und Ladesteckerverriegelung MQB2020 & MQBw_Baseline: -KL.58x an/aus: Licht ein-/ausschalten -Beleuchtung für Schalter, Displays ein/aus -S-Kontakt an auf aus: Deaktivierung Infotainment, EPB anziehen, u.a. -S-Kontakt aus auf an: Aktivierung Infotainment u.a. - Remotestartbetrieb: angefordert (maximal 2x10 Minuten), mit HW Kl.15 ein und ZAS Kl.15 aus - Einfrierschutz: Einfrierschutz angefordert, mit HW Kl.15 ein und ZAS Kl.15 aus MLBevo: - LIN_1: Drehen Lichtdrehschalter in Stellung Standlicht - LIN_3: Visualisierung Secundärfunktionen - KL58xt Ende
          signal NM_BCM1_UDS_CC_XIX_NMH_BCM1_XIX_E3V_CCAN: start 23, 1 bit, little-endian, data-type-policy=OVERRIDE, i-signal-type=PRIMITIVE, init-value=0, base-type=BT_NM_BCM1_UDS_CC, compu {0=Cx0_Inaktiv (CM_NM_BCM1_UDS_CC_Cx0_Inaktiv), 1=Cx1_CC_aktiv (CM_NM_BCM1_UDS_CC_Cx1_CC_aktiv)}, range raw 0..1, transfer-property=TRIGGERED  # Funktionseinschränkung aufgrund aktivem UDS-Communication Control, siehe VW80124
          signal NM_BCM1_NM_aktiv_KL15_XIX_NMH_BCM1_XIX_E3V_CCAN: start 24, 1 bit, little-endian, data-type-policy=OVERRIDE, i-signal-type=PRIMITIVE, init-value=0, base-type=BT_NM_BCM1_NM_aktiv_KL15, compu {0=Cx0_Inaktiv (CM_NM_BCM1_NM_aktiv_KL15_Cx0_Inaktiv), 1=Cx1_KL15_EIN (CM_NM_BCM1_NM_aktiv_KL15_Cx1_KL15_EIN)}, range raw 0..1, transfer-property=TRIGGERED  # Steuergerät hat KL15-EIN erkannt
          signal NM_BCM1_NM_aktiv_Diagnose_XIX_NMH_BCM1_XIX_E3V_CCAN: start 25, 1 bit, little-endian, data-type-policy=OVERRIDE, i-signal-type=PRIMITIVE, init-value=0, base-type=BT_NM_BCM1_NM_aktiv_Diagnose, compu {0=Cx0_Init (CM_NM_BCM1_NM_aktiv_Diagnose_Cx0_Init), 1=Cx1_Diagnose_aktiv (CM_NM_BCM1_NM_aktiv_Diagnose_Cx1_Diagnose_aktiv)}, range raw 0..1, transfer-property=TRIGGERED  # Diagnose befindet sich nach VW80124 in einer NonDefaultDiagnostic-Session, z.B. ExtendedDiagnostic-Session
          signal NM_BCM1_NM_aktiv_Tmin_XIX_NMH_BCM1_XIX_E3V_CCAN: start 26, 1 bit, little-endian, data-type-policy=OVERRIDE, i-signal-type=PRIMITIVE, init-value=0, base-type=BT_NM_BCM1_NM_aktiv_Tmin, compu {0=Cx0_Inaktiv (CM_NM_BCM1_NM_aktiv_Tmin_Cx0_Inaktiv), 1=Cx1_Mindestaktivzeit (CM_NM_BCM1_NM_aktiv_Tmin_Cx1_Mindestaktivzeit)}, range raw 0..1, transfer-property=TRIGGERED  # Mindestaktivzeit ist noch nicht abgelaufen (bei jedem Weckereignis wird die Mindestaktivzeit neu gestartet)
          signal NM_BCM1_NM_aktiv_Aussenlicht_XIX_NMH_BCM1_XIX_E3V_CCAN: start 27, 1 bit, little-endian, data-type-policy=OVERRIDE, i-signal-type=PRIMITIVE, init-value=0, base-type=BT_NM_BCM1_NM_aktiv_Aussenlicht, compu {0=Cx0_Init (CM_NM_BCM1_NM_aktiv_Aussenlicht_Cx0_Init), 1=Cx1_Aussenlicht_aktiv (CM_NM_BCM1_NM_aktiv_Aussenlicht_Cx1_Aussenlicht_aktiv)}, range raw 0..1, transfer-property=TRIGGERED  # Funktionsnachlauf Außenlicht (inkl. Blinken, Warnblinken, Lichthupe)
          signal NM_BCM1_NM_aktiv_ZV_XIX_NMH_BCM1_XIX_E3V_CCAN: start 28, 1 bit, little-endian, data-type-policy=OVERRIDE, i-signal-type=PRIMITIVE, init-value=0, base-type=BT_NM_BCM1_NM_aktiv_ZV, compu {0=Cx0_Init (CM_NM_BCM1_NM_aktiv_ZV_Cx0_Init), 1=Cx1_ZV_aktiv (CM_NM_BCM1_NM_aktiv_ZV_Cx1_ZV_aktiv)}, range raw 0..1, transfer-property=TRIGGERED  # Funktionsnachlauf Zentralverriegelung
          signal NM_BCM1_NM_aktiv_Heizung_XIX_NMH_BCM1_XIX_E3V_CCAN: start 29, 1 bit, little-endian, data-type-policy=OVERRIDE, i-signal-type=PRIMITIVE, init-value=0, base-type=BT_NM_BCM1_NM_aktiv_Heizung, compu {0=Cx0_Init (CM_NM_BCM1_NM_aktiv_Heizung_Cx0_Init), 1=Cx1_Heizung_aktiv (CM_NM_BCM1_NM_aktiv_Heizung_Cx1_Heizung_aktiv)}, range raw 0..1, transfer-property=TRIGGERED  # Funktionsnachlauf Klima/Heizung
          signal NM_BCM1_NM_aktiv_Innenlicht_XIX_NMH_BCM1_XIX_E3V_CCAN: start 30, 1 bit, little-endian, data-type-policy=OVERRIDE, i-signal-type=PRIMITIVE, init-value=0, base-type=BT_NM_BCM1_NM_aktiv_Innenlicht, compu {0=Cx0_Init (CM_NM_BCM1_NM_aktiv_Innenlicht_Cx0_Init), 1=Cx1_Innenlicht_aktiv (CM_NM_BCM1_NM_aktiv_Innenlicht_Cx1_Innenlicht_aktiv)}, range raw 0..1, transfer-property=TRIGGERED  # Funktionsnachlauf Innenlicht (inkl. KL 58x)
          signal NM_BCM1_NM_aktiv_DWA_XIX_NMH_BCM1_XIX_E3V_CCAN: start 31, 1 bit, little-endian, data-type-policy=OVERRIDE, i-signal-type=PRIMITIVE, init-value=0, base-type=BT_NM_BCM1_NM_aktiv_DWA, compu {0=Cx0_Init (CM_NM_BCM1_NM_aktiv_DWA_Cx0_Init), 1=Cx1_DWA_aktiv (CM_NM_BCM1_NM_aktiv_DWA_Cx1_DWA_aktiv)}, range raw 0..1, transfer-property=TRIGGERED  # Funktionsnachlauf Diebstahlwarnanlage
          signal NM_BCM1_NM_aktiv_Funk_XIX_NMH_BCM1_XIX_E3V_CCAN: start 32, 1 bit, little-endian, data-type-policy=OVERRIDE, i-signal-type=PRIMITIVE, init-value=0, base-type=BT_NM_BCM1_NM_aktiv_Funk, compu {0=Cx0_Init (CM_NM_BCM1_NM_aktiv_Funk_Cx0_Init), 1=Cx1_Funk_aktiv (CM_NM_BCM1_NM_aktiv_Funk_Cx1_Funk_aktiv)}, range raw 0..1, transfer-property=TRIGGERED  # Funktionsnachlauf Funk
          signal NM_BCM1_NM_aktiv_Kessy_XIX_NMH_BCM1_XIX_E3V_CCAN: start 33, 1 bit, little-endian, data-type-policy=OVERRIDE, i-signal-type=PRIMITIVE, init-value=0, base-type=BT_NM_BCM1_NM_aktiv_Kessy, compu {0=Cx0_Init (CM_NM_BCM1_NM_aktiv_Kessy_Cx0_Init), 1=Cx1_Kessy_Komm_aktiv (CM_NM_BCM1_NM_aktiv_Kessy_Cx1_Kessy_Komm_aktiv)}, range raw 0..1, transfer-property=TRIGGERED  # Funktionsnachlauf Kessy
          signal NM_BCM1_NM_aktiv_TK_geschlossen_XIX_NMH_BCM1_XIX_E3V_CCAN: start 34, 1 bit, little-endian, data-type-policy=OVERRIDE, i-signal-type=PRIMITIVE, init-value=0, base-type=BT_NM_BCM1_NM_aktiv_TK_geschlossen, compu {0=Cx0_Init (CM_NM_BCM1_NM_aktiv_TK_geschlossen_Cx0_Init), 1=Cx1_TK_geschlossen_aktiv (CM_NM_BCM1_NM_aktiv_TK_geschlossen_Cx1_TK_geschlossen_aktiv)}, range raw 0..1, transfer-property=TRIGGERED  # Drucktank: Rückmeldung des Tankklappenstatus (Tankklappe wurde geschlossen)
          signal NM_BCM1_NM_aktiv_Applikation_XIX_NMH_BCM1_XIX_E3V_CCAN: start 35, 1 bit, little-endian, data-type-policy=OVERRIDE, i-signal-type=PRIMITIVE, init-value=0, base-type=BT_NM_BCM1_NM_aktiv_Applikation, compu {1=Cx1_Applikationsanforderung_CAN (CM_NM_BCM1_NM_aktiv_Applikation_Cx1_Applikationsanforderung_CAN)}, range raw 1, transfer-property=TRIGGERED  # Eine Applikationsanforderung fordert den Bus.
          signal NM_BCM1_NM_aktiv_Remotestart_XIX_NMH_BCM1_XIX_E3V_CCAN: start 36, 1 bit, little-endian, data-type-policy=OVERRIDE, i-signal-type=PRIMITIVE, init-value=0, base-type=BT_NM_BCM1_NM_aktiv_Remotestart, compu {0=Cx0_Init (CM_NM_BCM1_NM_aktiv_Remotestart_Cx0_Init), 1=Cx1_Remotestart_aktiv (CM_NM_BCM1_NM_aktiv_Remotestart_Cx1_Remotestart_aktiv)}, range raw 0..1, transfer-property=TRIGGERED  # Funktionsnachlauf Remotestart
          signal NM_BCM1_NM_aktiv_Remot_Door_L_Un_XIX_NMH_BCM1_XIX_E3V_CCAN: start 37, 1 bit, little-endian, data-type-policy=OVERRIDE, i-signal-type=PRIMITIVE, init-value=0, base-type=BT_NM_BCM1_NM_aktiv_Remot_Door_L_Un, compu {0=Cx0_Inaktiv (CM_NM_BCM1_NM_aktiv_Remot_Door_L_Un_Cx0_Inaktiv), 1=Cx1_Remote_Door_Lock_Unlock_aktiv (CM_NM_BCM1_NM_aktiv_Remot_Door_L_Un_Cx1_Remote_Door_Lock_Unlock_aktiv)}, range raw 0..1, transfer-property=TRIGGERED  # Remote Door Lock oder Unlock wird ausgefuehrt
          signal NM_BCM1_CAB_V15_XIX_NMH_BCM1_XIX_E3V_CCAN: start 40, 24 bit, opaque, data-type-policy=OVERRIDE, i-signal-type=ARRAY, init-value=[0b00000000, 0b00000000, 0b00000000], base-type=BT_NM_BCM1_CAB_V15, compu {0=Cx0_Init (CM_NM_BCM1_CAB_V15_Cx0_Init), 1=Cx1_CAB_01_Antrieb (CM_NM_BCM1_CAB_V15_Cx1_CAB_01_Antrieb), 2=Cx2_CAB_02_Hybrid_Laden (CM_NM_BCM1_CAB_V15_Cx2_CAB_02_Hybrid_Laden), 4=Cx4_CAB_03_Fahrwerk (CM_NM_BCM1_CAB_V15_Cx4_CAB_03_Fahrwerk), 8=Cx8_CAB_04_Fahrerassistenz (CM_NM_BCM1_CAB_V15_Cx8_CAB_04_Fahrerassistenz), 16=Cx10_CAB_05_Komfort (CM_NM_BCM1_CAB_V15_Cx10_CAB_05_Komfort), 32=Cx20_CAB_06_Anzeige (CM_NM_BCM1_CAB_V15_Cx20_CAB_06_Anzeige), 64=Cx40_CAB_07_Connect (CM_NM_BCM1_CAB_V15_Cx40_CAB_07_Connect), 128=Cx80_CAB_08_MIB (CM_NM_BCM1_CAB_V15_Cx80_CAB_08_MIB), 256=Cx100_CAB_09_Standheizung (CM_NM_BCM1_CAB_V15_Cx100_CAB_09_Standheizung), 512=Cx200_CAB_10_MDK (CM_NM_BCM1_CAB_V15_Cx200_CAB_10_MDK), 1024=Cx400_CAB_11_VLAN_Fahrerassistenz (CM_NM_BCM1_CAB_V15_Cx400_CAB_11_VLAN_Fahrerassistenz), 4096=Cx1000_CAB_13_VLAN_Connect (CM_NM_BCM1_CAB_V15_Cx1000_CAB_13_VLAN_Connect), 8192=Cx2000_CAB_14_VLAN_Infotainment (CM_NM_BCM1_CAB_V15_Cx2000_CAB_14_VLAN_Infotainment), 16384=Cx4000_CAB_15_Laden (CM_NM_BCM1_CAB_V15_Cx4000_CAB_15_Laden), 32768=Cx8000_CAB_16_Licht (CM_NM_BCM1_CAB_V15_Cx8000_CAB_16_Licht), 65536=Cx10000_CAB_17_RTM (CM_NM_BCM1_CAB_V15_Cx10000_CAB_17_RTM)}, range raw 0..65536, transfer-property=TRIGGERED  # CAB = Clusteraktivbits (V15) CAB_03_Fahrwerk Änderung Türstatus (ELock Aktivierung ü. Airbag-SG) CAB_04_Fahrerassistenz Änderung Türstatus (weckt CPD)
      frame NMH_eCall_XIX_E3V_CCAN: id 0x1B000067, to SAM, frame-length=8, can-addressing-mode=EXTENDED, can-frame-rx-behavior=CAN-20, can-frame-tx-behavior=CAN-20, rx-identifier-range={lower-can-id=452984832, upper-can-id=452985855}
        nm pdu NMH_eCall_XIX_E3V_CCAN: length=8, unused-bit-pattern=0
          signal NM_eCall_CBV_AWB_XIX_NMH_eCall_XIX_E3V_CCAN: start 12, 1 bit, little-endian, data-type-policy=OVERRIDE, i-signal-type=PRIMITIVE, init-value=0, base-type=BT_NM_eCall_CBV_AWB, compu {0=Cx0_Passiver_WakeUp (CM_NM_eCall_CBV_AWB_Cx0_Passiver_WakeUp), 1=Cx1_Aktiver_WakeUp (CM_NM_eCall_CBV_AWB_Cx1_Aktiver_WakeUp)}, range raw 0..1, transfer-property=TRIGGERED  # Das Signal ist zu setzen, wenn das SG aktiv den Bus geweckt hat 0 = Passiver_WakeUp = SG hat das Netzwerk nicht aktiv geweckt 1 = Akitiver_WakeUp = SG hat das Netzwerk aktiv geweckt
          signal NM_eCall_CBV_CRI_XIX_NMH_eCall_XIX_E3V_CCAN: start 14, 1 bit, little-endian, data-type-policy=OVERRIDE, i-signal-type=PRIMITIVE, init-value=0, base-type=BT_NM_eCall_CBV_CRI, compu {0=Cx0_NM_ohne_Clusteranforderungen (CM_NM_eCall_CBV_CRI_Cx0_NM_ohne_Clusteranforderungen), 1=Cx1_NM_mit_Clusteranforderungen (CM_NM_eCall_CBV_CRI_Cx1_NM_mit_Clusteranforderungen)}, range raw 0..1, transfer-property=TRIGGERED  # Das Signal ist dauerhaft gesetzt, wenn das NM-Layout Cluster- Anforderungen enthält
          signal NM_eCall_NM_State_XIX_NMH_eCall_XIX_E3V_CCAN: start 16, 6 bit, little-endian, data-type-policy=OVERRIDE, i-signal-type=PRIMITIVE, init-value=0, base-type=BT_NM_eCall_NM_State, compu {0=Cx0_Init (CM_NM_eCall_NM_State_Cx0_Init), 1=Cx1_NM_RM_aus_BSM (CM_NM_eCall_NM_State_Cx1_NM_RM_aus_BSM), 2=Cx2_NM_RM_aus_PBSM (CM_NM_eCall_NM_State_Cx2_NM_RM_aus_PBSM), 4=Cx4_NM_NO_aus_RM (CM_NM_eCall_NM_State_Cx4_NM_NO_aus_RM), 8=Cx8_NM_NO_aus_RS (CM_NM_eCall_NM_State_Cx8_NM_NO_aus_RS), 16=Cx10_reserved (CM_NM_eCall_NM_State_Cx10_reserved), 32=Cx20_reserved (CM_NM_eCall_NM_State_Cx20_reserved)}, range raw 0..32, transfer-property=TRIGGERED, to SAM(timeout 2 s)  # 1 = Zustand Repeat Message (<-- Bus-Sleep Mode) 2 = Zustand Repeat Message (<-- Prepare Bus-Sleep Mode) 4 = Zustand Normal Operation (<-- Repeat Message) 8 = Zustand Normal Operation (<-- Ready Sleep)
          signal NM_eCall_Car_Wakeup_XIX_NMH_eCall_XIX_E3V_CCAN: start 22, 1 bit, little-endian, data-type-policy=OVERRIDE, i-signal-type=PRIMITIVE, init-value=0, base-type=BT_NM_eCall_Car_Wakeup, compu {0=Cx0_Inaktiv (CM_NM_eCall_Car_Wakeup_Cx0_Inaktiv), 1=Cx1_Car_Wakeup (CM_NM_eCall_Car_Wakeup_Cx1_Car_Wakeup)}, range raw 0..1, transfer-property=TRIGGERED  # Car Wakeup (Gateway wertet aus) MQB: -Laden an/aus, Klimatisieren an/aus, Programmieren, Abfrage Fahrzeugstatus/Batteriestatus, Anruf aktiv (max 10 Min). -IAA: Identifizieren, Authentisieren, Autorisieren - Nutzeridentifikation/ Management (max. 10sec) -Personalisierung 2.0, Abschluss der Teilfunktionen bzw. Ein/Auslagern von Daten (max 60sec) - Installations-POP-Up für ORU 3 in der OCU3 für 5 Minuten oder bis Klemme S aus (<5min oder KL.S aus) MQB2020: -Abfrage Fahrzeugstatus MQBw_Baseline: -Abfrage Fahrzeugstatus
          signal NM_eCall_UDS_CC_XIX_NMH_eCall_XIX_E3V_CCAN: start 23, 1 bit, little-endian, data-type-policy=OVERRIDE, i-signal-type=PRIMITIVE, init-value=0, base-type=BT_NM_eCall_UDS_CC, compu {0=Cx0_Inaktiv (CM_NM_eCall_UDS_CC_Cx0_Inaktiv), 1=Cx1_CC_aktiv (CM_NM_eCall_UDS_CC_Cx1_CC_aktiv)}, range raw 0..1, transfer-property=TRIGGERED  # Funktionseinschränkung aufgrund aktivem UDS-Communication Control, siehe VW80124
          signal NM_eCall_NM_aktiv_KL15_XIX_NMH_eCall_XIX_E3V_CCAN: start 24, 1 bit, little-endian, data-type-policy=OVERRIDE, i-signal-type=PRIMITIVE, init-value=0, base-type=BT_NM_eCall_NM_aktiv_KL15, compu {0=Cx0_Inaktiv (CM_NM_eCall_NM_aktiv_KL15_Cx0_Inaktiv), 1=Cx1_KL15_EIN (CM_NM_eCall_NM_aktiv_KL15_Cx1_KL15_EIN)}, range raw 0..1, transfer-property=TRIGGERED  # Steuergerät hat KL15-EIN erkannt
          signal NM_eCall_NM_aktiv_Diagnose_XIX_NMH_eCall_XIX_E3V_CCAN: start 25, 1 bit, little-endian, data-type-policy=OVERRIDE, i-signal-type=PRIMITIVE, init-value=0, base-type=BT_NM_eCall_NM_aktiv_Diagnose, compu {0=Cx0_Init (CM_NM_eCall_NM_aktiv_Diagnose_Cx0_Init), 1=Cx1_Diagnose_aktiv (CM_NM_eCall_NM_aktiv_Diagnose_Cx1_Diagnose_aktiv)}, range raw 0..1, transfer-property=TRIGGERED  # Diagnose befindet sich nach VW80124 in einer NonDefaultDiagnostic-Session, z.B. ExtendedDiagnostic-Session
          signal NM_eCall_NM_aktiv_Tmin_XIX_NMH_eCall_XIX_E3V_CCAN: start 26, 1 bit, little-endian, data-type-policy=OVERRIDE, i-signal-type=PRIMITIVE, init-value=0, base-type=BT_NM_eCall_NM_aktiv_Tmin, compu {0=Cx0_Inaktiv (CM_NM_eCall_NM_aktiv_Tmin_Cx0_Inaktiv), 1=Cx1_Mindestaktivzeit (CM_NM_eCall_NM_aktiv_Tmin_Cx1_Mindestaktivzeit)}, range raw 0..1, transfer-property=TRIGGERED  # Mindestaktivzeit ist noch nicht abgelaufen (bei jedem Weckereignis wird die Mindestaktivzeit neu gestartet)
          signal NM_eCall_NM_aktiv_Laden_XIX_NMH_eCall_XIX_E3V_CCAN: start 27, 1 bit, little-endian, data-type-policy=OVERRIDE, i-signal-type=PRIMITIVE, init-value=0, base-type=BT_NM_eCall_NM_aktiv_Laden, compu {0=Cx0_Init (CM_NM_eCall_NM_aktiv_Laden_Cx0_Init), 1=Cx1_Remote_Charging_aktiv (CM_NM_eCall_NM_aktiv_Laden_Cx1_Remote_Charging_aktiv)}, range raw 0..1, transfer-property=TRIGGERED  # Laden an/aus, Abfrage SOC
          signal NM_eCall_NM_aktiv_Settings_XIX_NMH_eCall_XIX_E3V_CCAN: start 28, 1 bit, little-endian, data-type-policy=OVERRIDE, i-signal-type=PRIMITIVE, init-value=0, base-type=BT_NM_eCall_NM_aktiv_Settings, compu {0=Cx0_Init (CM_NM_eCall_NM_aktiv_Settings_Cx0_Init), 1=Cx1_Remote_Settings_aktiv (CM_NM_eCall_NM_aktiv_Settings_Cx1_Remote_Settings_aktiv)}, range raw 0..1, transfer-property=TRIGGERED  # Settings aktiv
          signal NM_eCall_NM_aktiv_Klimatisieren_XIX_NMH_eCall_XIX_E3V_CCAN: start 29, 1 bit, little-endian, data-type-policy=OVERRIDE, i-signal-type=PRIMITIVE, init-value=0, base-type=BT_NM_eCall_NM_aktiv_Klimatisieren, compu {0=Cx0_Init (CM_NM_eCall_NM_aktiv_Klimatisieren_Cx0_Init), 1=Cx1_Remote_Clima_aktiv (CM_NM_eCall_NM_aktiv_Klimatisieren_Cx1_Remote_Clima_aktiv)}, range raw 0..1, transfer-property=TRIGGERED  # Klimatisieren aktiv
          signal NM_eCall_NM_aktiv_Status_XIX_NMH_eCall_XIX_E3V_CCAN: start 30, 1 bit, little-endian, data-type-policy=OVERRIDE, i-signal-type=PRIMITIVE, init-value=0, base-type=BT_NM_eCall_NM_aktiv_Status, compu {0=Cx0_Init (CM_NM_eCall_NM_aktiv_Status_Cx0_Init), 1=Cx1_Remote_Status_aktiv (CM_NM_eCall_NM_aktiv_Status_Cx1_Remote_Status_aktiv)}, range raw 0..1, transfer-property=TRIGGERED  # Statusabfrage aktiv
          signal NM_eCall_NM_aktiv_Remote_Control_XIX_NMH_eCall_XIX_E3V_CCAN: start 31, 1 bit, little-endian, data-type-policy=OVERRIDE, i-signal-type=PRIMITIVE, init-value=0, base-type=BT_NM_eCall_NM_aktiv_Remote_Control, compu {0=Cx0_Init (CM_NM_eCall_NM_aktiv_Remote_Control_Cx0_Init), 1=Cx1_Remote_Control_aktiv (CM_NM_eCall_NM_aktiv_Remote_Control_Cx1_Remote_Control_aktiv)}, range raw 0..1, transfer-property=TRIGGERED  # Remote Control aktiv
          signal NM_eCall_NM_aktiv_Call_XIX_NMH_eCall_XIX_E3V_CCAN: start 32, 1 bit, little-endian, data-type-policy=OVERRIDE, i-signal-type=PRIMITIVE, init-value=0, base-type=BT_NM_eCall_NM_aktiv_Call, compu {0=Cx0_Init (CM_NM_eCall_NM_aktiv_Call_Cx0_Init), 1=Cx1_Anruf_aktiv (CM_NM_eCall_NM_aktiv_Call_Cx1_Anruf_aktiv)}, range raw 0..1, transfer-property=TRIGGERED  # Anruf aktiv (Automatic Crash Notification, Manual Emergency Call, Concierge Information Call, Roadside Assistance Call)
          signal NM_eCall_NM_aktiv_Dienstabfrage_XIX_NMH_eCall_XIX_E3V_CCAN: start 33, 1 bit, little-endian, data-type-policy=OVERRIDE, i-signal-type=PRIMITIVE, init-value=0, base-type=BT_NM_eCall_NM_aktiv_Dienstabfrage, compu {0=Cx0_Init (CM_NM_eCall_NM_aktiv_Dienstabfrage_Cx0_Init), 1=Cx1_Abfrage_aktiv (CM_NM_eCall_NM_aktiv_Dienstabfrage_Cx1_Abfrage_aktiv)}, range raw 0..1, transfer-property=TRIGGERED  # Nach Ausschalten der Klemme 15 werden erst alle Dienste in der OCU-SW abgefragt, bevor die CAN Kommunikation beendet wird. (Das hat nichts mit den Online-Diensten zu tun). Die Abfrage dauert normalerweise ca. 1s. Spätestens nach 5s ist die Abfrage beendet bzw. erfolgt der Timeout. Abfrage der Daten für den Regulatory Data Upload Service (RDUS) nach Beendigung des Fahrzykluses im Nachlauf.
          signal NM_eCall_NM_aktiv_IAA_XIX_NMH_eCall_XIX_E3V_CCAN: start 34, 1 bit, little-endian, data-type-policy=OVERRIDE, i-signal-type=PRIMITIVE, init-value=0, base-type=BT_NM_eCall_NM_aktiv_IAA, compu {0=Cx0_Init (CM_NM_eCall_NM_aktiv_IAA_Cx0_Init), 1=Cx1_IAA_aktiv (CM_NM_eCall_NM_aktiv_IAA_Cx1_IAA_aktiv)}, range raw 0..1, transfer-property=TRIGGERED  # IAA: Nutzeridentifikation/ Management ist aktiv
          signal NM_eCall_NM_aktiv_C2X_XIX_NMH_eCall_XIX_E3V_CCAN: start 35, 1 bit, little-endian, data-type-policy=OVERRIDE, i-signal-type=PRIMITIVE, init-value=0, base-type=BT_NM_eCall_NM_aktiv_C2X, compu {0=Cx0_Inaktiv (CM_NM_eCall_NM_aktiv_C2X_Cx0_Inaktiv), 1=Cx1_C2X_aktiv (CM_NM_eCall_NM_aktiv_C2X_Cx1_C2X_aktiv)}, range raw 0..1, transfer-property=TRIGGERED  # C2X Funktion benötigt Kommunikation
          signal NM_eCall_NM_aktiv_MQTT_GW_XIX_NMH_eCall_XIX_E3V_CCAN: start 36, 1 bit, little-endian, data-type-policy=OVERRIDE, i-signal-type=PRIMITIVE, init-value=0, base-type=BT_NM_eCall_NM_aktiv_MQTT_GW, compu {0=Cx0_Init (CM_NM_eCall_NM_aktiv_MQTT_GW_Cx0_Init), 1=Cx1_MQTT_GW_aktiv (CM_NM_eCall_NM_aktiv_MQTT_GW_Cx1_MQTT_GW_aktiv)}, range raw 0..1, transfer-property=TRIGGERED  # MQTT Gateway ist aktiv
          signal NM_eCall_NM_aktiv_RPA_XIX_NMH_eCall_XIX_E3V_CCAN: start 37, 1 bit, little-endian, data-type-policy=OVERRIDE, i-signal-type=PRIMITIVE, init-value=0, base-type=BT_NM_eCall_NM_aktiv_RPA, compu {0=Cx0_Inaktiv (CM_NM_eCall_NM_aktiv_RPA_Cx0_Inaktiv), 1=Cx1_RPA_aktiv (CM_NM_eCall_NM_aktiv_RPA_Cx1_RPA_aktiv)}, range raw 0..1, transfer-property=PENDING  # RPA Funktion benötigt Kommunikation
          signal NM_ecall_NM_aktiv_PredWakeUp_XIX_NMH_eCall_XIX_E3V_CCAN: start 38, 1 bit, little-endian, data-type-policy=OVERRIDE, i-signal-type=PRIMITIVE, init-value=0, base-type=BT_NM_ecall_NM_aktiv_PredWakeUp, compu {0=Cx0_Init (CM_NM_ecall_NM_aktiv_PredWakeUp_Cx0_Init), 1=Cx1_Predictive_WakeUp_aktiv (CM_NM_ecall_NM_aktiv_PredWakeUp_Cx1_Predictive_WakeUp_aktiv)}, range raw 0..1, transfer-property=TRIGGERED  # User Predictive wakeup is active
          signal NM_eCall_NM_aktiv_PSO_XIX_NMH_eCall_XIX_E3V_CCAN: start 39, 1 bit, little-endian, data-type-policy=OVERRIDE, i-signal-type=PRIMITIVE, init-value=0, base-type=BT_NM_eCall_NM_aktiv_PSO, compu {0=Cx0_Init (CM_NM_eCall_NM_aktiv_PSO_Cx0_Init), 1=Cx1_PSO_aktiv (CM_NM_eCall_NM_aktiv_PSO_Cx1_PSO_aktiv)}, range raw 0..1, transfer-property=TRIGGERED  # Personalisierung benötigt Kommunikation (nur ConMod)
          signal NM_eCall_CAB_V15_XIX_NMH_eCall_XIX_E3V_CCAN: start 40, 24 bit, opaque, data-type-policy=OVERRIDE, i-signal-type=ARRAY, init-value=[0b00000000, 0b00000000, 0b00000000], base-type=BT_NM_eCall_CAB_V15, compu {0=Cx0_Init (CM_NM_eCall_CAB_V15_Cx0_Init), 1=Cx1_CAB_01_Antrieb (CM_NM_eCall_CAB_V15_Cx1_CAB_01_Antrieb), 2=Cx2_CAB_02_Hybrid_Laden (CM_NM_eCall_CAB_V15_Cx2_CAB_02_Hybrid_Laden), 4=Cx4_CAB_03_Fahrwerk (CM_NM_eCall_CAB_V15_Cx4_CAB_03_Fahrwerk), 8=Cx8_CAB_04_Fahrerassistenz (CM_NM_eCall_CAB_V15_Cx8_CAB_04_Fahrerassistenz), 16=Cx10_CAB_05_Komfort (CM_NM_eCall_CAB_V15_Cx10_CAB_05_Komfort), 32=Cx20_CAB_06_Anzeige (CM_NM_eCall_CAB_V15_Cx20_CAB_06_Anzeige), 64=Cx40_CAB_07_Connect (CM_NM_eCall_CAB_V15_Cx40_CAB_07_Connect), 128=Cx80_CAB_08_MIB (CM_NM_eCall_CAB_V15_Cx80_CAB_08_MIB), 256=Cx100_CAB_09_Standheizung (CM_NM_eCall_CAB_V15_Cx100_CAB_09_Standheizung), 512=Cx200_CAB_10_MDK (CM_NM_eCall_CAB_V15_Cx200_CAB_10_MDK), 1024=Cx400_CAB_11_VLAN_Fahrerassistenz (CM_NM_eCall_CAB_V15_Cx400_CAB_11_VLAN_Fahrerassistenz), 4096=Cx1000_CAB_13_VLAN_Connect (CM_NM_eCall_CAB_V15_Cx1000_CAB_13_VLAN_Connect), 8192=Cx2000_CAB_14_VLAN_Infotainment (CM_NM_eCall_CAB_V15_Cx2000_CAB_14_VLAN_Infotainment), 16384=Cx4000_CAB_15_Laden (CM_NM_eCall_CAB_V15_Cx4000_CAB_15_Laden), 32768=Cx8000_CAB_16_Licht (CM_NM_eCall_CAB_V15_Cx8000_CAB_16_Licht), 65536=Cx10000_CAB_17_RTM (CM_NM_eCall_CAB_V15_Cx10000_CAB_17_RTM)}, range raw 0..65536, transfer-property=TRIGGERED  # CAB = Clusteraktivbits (V15) Cluster - CAB_08_MIB -Vehicle Integration Layer (IAA WakeUp (Nutzerlisten-/Nutzerprofile Update im ICAS1 und ICAS3)) -Call-Dienste Cluster - CAB_13_VLAN_Connect - Grauer/ Grüner Dienst (Nutzung der Ethernet Strecke für Graue oder Grüne Dienste im ICAS1) -Vehicle Integration Layer (IAA WakeUp (Nutzerlisten-/Nutzerprofile Update im ICAS1 und ICAS3)) Cluster - CAB_14_VLAN_Infotainment -Vehicle Integration Layer (IAA WakeUp (Nutzerlisten-/Nutzerprofile Update im ICAS1 und ICAS3)) -Call-Dienste
      frame NMH_Gateway_XIX_E3V_CCAN: id 0x1B000010, to SAM, frame-length=8, can-addressing-mode=EXTENDED, can-frame-rx-behavior=CAN-20, can-frame-tx-behavior=CAN-20, rx-identifier-range={lower-can-id=452984832, upper-can-id=452985855}
        nm pdu NMH_Gateway_XIX_E3V_CCAN: length=8, unused-bit-pattern=0
          signal NM_Gateway_CBV_AWB_XIX_NMH_Gateway_XIX_E3V_CCAN: start 12, 1 bit, little-endian, data-type-policy=OVERRIDE, i-signal-type=PRIMITIVE, init-value=0, base-type=BT_NM_Gateway_CBV_AWB, compu {0=Cx0_Passiver_WakeUp (CM_NM_Gateway_CBV_AWB_Cx0_Passiver_WakeUp), 1=Cx1_Aktiver_WakeUp (CM_NM_Gateway_CBV_AWB_Cx1_Aktiver_WakeUp)}, range raw 0..1, transfer-property=TRIGGERED  # Das Signal ist zu setzen, wenn das SG aktiv den Bus geweckt hat 0 = Passiver_WakeUp = SG hat das Netzwerk nicht aktiv geweckt 1 = Akitiver_WakeUp = SG hat das Netzwerk aktiv geweckt
          signal NM_Gateway_CBV_CRI_XIX_NMH_Gateway_XIX_E3V_CCAN: start 14, 1 bit, little-endian, data-type-policy=OVERRIDE, i-signal-type=PRIMITIVE, base-type=BT_NM_Gateway_CBV_CRI, compu {0=Cx0_NM_ohne_Clusteranforderungen (CM_NM_Gateway_CBV_CRI_Cx0_NM_ohne_Clusteranforderungen), 1=Cx1_NM_mit_Clusteranforderungen (CM_NM_Gateway_CBV_CRI_Cx1_NM_mit_Clusteranforderungen)}, range raw 0..1, transfer-property=TRIGGERED  # Das Signal ist dauerhaft gesetzt, wenn das NM-Layout Cluster- Anforderungen enthält
          signal NM_Gateway_NM_State_XIX_NMH_Gateway_XIX_E3V_CCAN: start 16, 6 bit, little-endian, data-type-policy=OVERRIDE, i-signal-type=PRIMITIVE, init-value=0, base-type=BT_NM_Gateway_NM_State, compu {0=Cx0_Init (CM_NM_Gateway_NM_State_Cx0_Init), 1=Cx1_NM_RM_aus_BSM (CM_NM_Gateway_NM_State_Cx1_NM_RM_aus_BSM), 2=Cx2_NM_RM_aus_PBSM (CM_NM_Gateway_NM_State_Cx2_NM_RM_aus_PBSM), 4=Cx4_NM_NO_aus_RM (CM_NM_Gateway_NM_State_Cx4_NM_NO_aus_RM), 8=Cx8_NM_NO_aus_RS (CM_NM_Gateway_NM_State_Cx8_NM_NO_aus_RS), 16=Cx10_NM_RM_aus_RS (CM_NM_Gateway_NM_State_Cx10_NM_RM_aus_RS), 32=Cx20_NM_RM_aus_NO (CM_NM_Gateway_NM_State_Cx20_NM_RM_aus_NO)}, range raw 0..32, transfer-property=TRIGGERED, to SAM(timeout 2 s)  # 1 = Zustand Repeat Message (<-- Bus-Sleep Mode) 2 = Zustand Repeat Message (<-- Prepare Bus-Sleep Mode) 4 = Zustand Normal Operation (<-- Repeat Message) 8 = Zustand Normal Operation (<-- Ready Sleep) 16 = Zustand Repeat Message (<-- Ready Sleep) 32 = Zustand Repeat Message (<-- Normal Operation)
          signal NM_Gateway_Car_Wakeup_XIX_NMH_Gateway_XIX_E3V_CCAN: start 22, 1 bit, little-endian, data-type-policy=OVERRIDE, i-signal-type=PRIMITIVE, init-value=0, base-type=BT_NM_Gateway_Car_Wakeup, compu {0=Cx0_Inaktiv (CM_NM_Gateway_Car_Wakeup_Cx0_Inaktiv), 1=Cx1_Car_Wakeup (CM_NM_Gateway_Car_Wakeup_Cx1_Car_Wakeup)}, range raw 0..1, transfer-property=TRIGGERED  # Car Wakeup (Subbusmaster wertet aus) MQB: -Diagnose- oder Komponentenschutzmaster-Funktion weckt den schlafenden Subbus (z.B. MOST) E3_Volumen: - Diagnose aktiv -aktive Diagnosekommunikation am OBD-Stecker MQBw_Baseline: - Diagnose aktiv -aktive Diagnosekommunikation am OBD-Stecker
          signal NM_Gateway_UDS_CC_XIX_NMH_Gateway_XIX_E3V_CCAN: start 23, 1 bit, little-endian, data-type-policy=OVERRIDE, i-signal-type=PRIMITIVE, init-value=0, base-type=BT_NM_Gateway_UDS_CC, compu {0=Cx0_Inaktiv (CM_NM_Gateway_UDS_CC_Cx0_Inaktiv), 1=Cx1_CC_aktiv (CM_NM_Gateway_UDS_CC_Cx1_CC_aktiv)}, range raw 0..1, transfer-property=TRIGGERED  # Funktionseinschränkung aufgrund aktivem UDS-Communication Control, siehe VW80124
          signal NM_Gateway_NM_aktiv_KL15_XIX_NMH_Gateway_XIX_E3V_CCAN: start 24, 1 bit, little-endian, data-type-policy=OVERRIDE, i-signal-type=PRIMITIVE, init-value=0, base-type=BT_NM_Gateway_NM_aktiv_KL15, compu {0=Cx0_Inaktiv (CM_NM_Gateway_NM_aktiv_KL15_Cx0_Inaktiv), 1=Cx1_KL15_EIN (CM_NM_Gateway_NM_aktiv_KL15_Cx1_KL15_EIN)}, range raw 0..1, transfer-property=TRIGGERED  # Steuergerät hat KL15-EIN erkannt
          signal NM_Gateway_NM_aktiv_Diagnose_XIX_NMH_Gateway_XIX_E3V_CCAN: start 25, 1 bit, little-endian, data-type-policy=OVERRIDE, i-signal-type=PRIMITIVE, init-value=0, base-type=BT_NM_Gateway_NM_aktiv_Diagnose, compu {0=Cx0_Init (CM_NM_Gateway_NM_aktiv_Diagnose_Cx0_Init), 1=Cx1_Diagnose_aktiv (CM_NM_Gateway_NM_aktiv_Diagnose_Cx1_Diagnose_aktiv)}, range raw 0..1, transfer-property=TRIGGERED  # Diagnose befindet sich nach VW80124 in einer NonDefaultDiagnostic-Session, z.B. ExtendedDiagnostic-Session
          signal NM_Gateway_NM_aktiv_Tmin_XIX_NMH_Gateway_XIX_E3V_CCAN: start 26, 1 bit, little-endian, data-type-policy=OVERRIDE, i-signal-type=PRIMITIVE, init-value=0, base-type=BT_NM_Gateway_NM_aktiv_Tmin, compu {0=Cx0_Inaktiv (CM_NM_Gateway_NM_aktiv_Tmin_Cx0_Inaktiv), 1=Cx1_Mindestaktivzeit (CM_NM_Gateway_NM_aktiv_Tmin_Cx1_Mindestaktivzeit)}, range raw 0..1, transfer-property=TRIGGERED  # Mindestaktivzeit ist noch nicht abgelaufen (bei jedem Weckereignis wird die Mindestaktivzeit neu gestartet)
          signal NM_Gateway_NM_aktiv_Kessy_XIX_NMH_Gateway_XIX_E3V_CCAN: start 27, 1 bit, little-endian, data-type-policy=OVERRIDE, i-signal-type=PRIMITIVE, init-value=0, base-type=BT_NM_Gateway_NM_aktiv_Kessy, compu {0=Cx0_Inaktiv (CM_NM_Gateway_NM_aktiv_Kessy_Cx0_Inaktiv), 1=Cx1_Kessy_aktiv (CM_NM_Gateway_NM_aktiv_Kessy_Cx1_Kessy_aktiv)}, range raw 0..1, transfer-property=TRIGGERED  # Dieser Bus wird auf Grund einer Aktivität der Funktion Kessy wachgehalten
          signal NM_Gateway_NM_aktiv_Energie_XIX_NMH_Gateway_XIX_E3V_CCAN: start 28, 1 bit, little-endian, data-type-policy=OVERRIDE, i-signal-type=PRIMITIVE, init-value=0, base-type=BT_NM_Gateway_NM_aktiv_Energie, compu {0=Cx0_Inaktiv (CM_NM_Gateway_NM_aktiv_Energie_Cx0_Inaktiv), 1=Cx1_Energie_aktiv (CM_NM_Gateway_NM_aktiv_Energie_Cx1_Energie_aktiv)}, range raw 0..1, transfer-property=TRIGGERED  # Dieser Bus wird auf Grund einer Aktivität der Funktion EMHLR, HVEM, Dynamic Charging POI, Charging-Management-Server oder Extended Charging Monitoring wachgehalten
          signal NM_Gateway_NM_aktiv_Licht_XIX_NMH_Gateway_XIX_E3V_CCAN: start 29, 1 bit, little-endian, data-type-policy=OVERRIDE, i-signal-type=PRIMITIVE, init-value=0, base-type=BT_NM_Gateway_NM_aktiv_Licht, compu {0=Cx0_Inaktiv (CM_NM_Gateway_NM_aktiv_Licht_Cx0_Inaktiv), 1=Cx1_Licht_aktiv (CM_NM_Gateway_NM_aktiv_Licht_Cx1_Licht_aktiv)}, range raw 0..1, transfer-property=TRIGGERED  # Dieser Bus wird auf Grund einer Aktivität der Funktion Dimmung oder Standard Außenlicht wachgehalten
          signal NM_Gateway_NM_aktiv_USS_XIX_NMH_Gateway_XIX_E3V_CCAN: start 30, 1 bit, little-endian, data-type-policy=OVERRIDE, i-signal-type=PRIMITIVE, init-value=0, base-type=BT_NM_Gateway_NM_aktiv_USS, compu {0=Cx0_Inaktiv (CM_NM_Gateway_NM_aktiv_USS_Cx0_Inaktiv), 1=Cx1_USS_aktiv (CM_NM_Gateway_NM_aktiv_USS_Cx1_USS_aktiv)}, range raw 0..1, transfer-property=TRIGGERED  # Dieser Bus wird auf Grund einer Aktivität des User State Servers wachgehalten
          signal NM_Gateway_NM_aktiv_IAA_PSO_XIX_NMH_Gateway_XIX_E3V_CCAN: start 31, 1 bit, little-endian, data-type-policy=OVERRIDE, i-signal-type=PRIMITIVE, init-value=0, base-type=BT_NM_Gateway_NM_aktiv_IAA_PSO, compu {0=Cx0_Inaktiv (CM_NM_Gateway_NM_aktiv_IAA_PSO_Cx0_Inaktiv), 1=Cx1_Personalisierung_aktiv (CM_NM_Gateway_NM_aktiv_IAA_PSO_Cx1_Personalisierung_aktiv)}, range raw 0..1, transfer-property=TRIGGERED  # Dieser Bus wird auf Grund einer Aktivität der Personalisierung wachgehalten
          signal NM_Gateway_NM_aktiv_CAB_XIX_NMH_Gateway_XIX_E3V_CCAN: start 32, 1 bit, little-endian, data-type-policy=OVERRIDE, i-signal-type=PRIMITIVE, init-value=0, base-type=BT_NM_Gateway_NM_aktiv_CAB, compu {0=Cx0_Inaktiv (CM_NM_Gateway_NM_aktiv_CAB_Cx0_Inaktiv), 1=Cx1_CAB_aktiv (CM_NM_Gateway_NM_aktiv_CAB_Cx1_CAB_aktiv)}, range raw 0..1, transfer-property=TRIGGERED  # Nachlauf aufgrund Kopplung mehrerer Busse. z.B. K-CAN und K2-CAN, Clusteranforderung über CAB und Car Wakeup Anforderung.
          signal NM_Gateway_NM_aktiv_KS_XIX_NMH_Gateway_XIX_E3V_CCAN: start 33, 1 bit, little-endian, data-type-policy=OVERRIDE, i-signal-type=PRIMITIVE, init-value=0, base-type=BT_NM_Gateway_NM_aktiv_KS, compu {0=Cx0_Inaktiv (CM_NM_Gateway_NM_aktiv_KS_Cx0_Inaktiv), 1=Cx1_KS_aktiv (CM_NM_Gateway_NM_aktiv_KS_Cx1_KS_aktiv)}, range raw 0..1, transfer-property=TRIGGERED  # Dieser Bus wird auf Grund einer Aktivität des Komponentenschutzes wachgehalten
          signal NM_Gateway_NM_aktiv_PaCo_XIX_NMH_Gateway_XIX_E3V_CCAN: start 34, 1 bit, little-endian, data-type-policy=OVERRIDE, i-signal-type=PRIMITIVE, init-value=0, base-type=BT_NM_Gateway_NM_aktiv_PaCo, compu {0=Cx0_Inaktiv (CM_NM_Gateway_NM_aktiv_PaCo_Cx0_Inaktiv), 1=Cx1_PaCo_aktiv (CM_NM_Gateway_NM_aktiv_PaCo_Cx1_PaCo_aktiv)}, range raw 0..1, transfer-property=TRIGGERED  # Dieser Bus wird auf Grund einer Aktivität des Park Koordinators wachgehalten
          signal NM_Gateway_NM_aktiv_Standklima_XIX_NMH_Gateway_XIX_E3V_CCAN: start 35, 1 bit, little-endian, data-type-policy=OVERRIDE, i-signal-type=PRIMITIVE, init-value=0, base-type=BT_NM_Gateway_NM_aktiv_Standklima, compu {0=Cx0_Inaktiv (CM_NM_Gateway_NM_aktiv_Standklima_Cx0_Inaktiv), 1=Cx1_STK_aktiv (CM_NM_Gateway_NM_aktiv_Standklima_Cx1_STK_aktiv)}, range raw 0..1, transfer-property=TRIGGERED  # Dieser Bus wird auf Grund einer Aktivität der Standklimatisierung wachgehalten
          signal NM_Gateway_NM_aktiv_ZV_XIX_NMH_Gateway_XIX_E3V_CCAN: start 36, 1 bit, little-endian, data-type-policy=OVERRIDE, i-signal-type=PRIMITIVE, init-value=0, base-type=BT_NM_Gateway_NM_aktiv_ZV, compu {0=Cx0_Inaktiv (CM_NM_Gateway_NM_aktiv_ZV_Cx0_Inaktiv), 1=Cx1_ZV_aktiv (CM_NM_Gateway_NM_aktiv_ZV_Cx1_ZV_aktiv)}, range raw 0..1, transfer-property=TRIGGERED  # Dieser Bus wird auf Grund einer Aktivität der Zentralverriegelung wachgehalten
          signal NM_Gateway_NM_aktiv_RTM_XIX_NMH_Gateway_XIX_E3V_CCAN: start 37, 1 bit, little-endian, data-type-policy=OVERRIDE, i-signal-type=PRIMITIVE, init-value=0, base-type=BT_NM_Gateway_NM_aktiv_RTM, compu {0=Cx0_Inaktiv (CM_NM_Gateway_NM_aktiv_RTM_Cx0_Inaktiv), 1=Cx1_RTM_aktiv (CM_NM_Gateway_NM_aktiv_RTM_Cx1_RTM_aktiv)}, range raw 0..1, transfer-property=TRIGGERED  # Dieser Bus wird auf Grund einer Aktivität des Real Time Monitors wachgehalten
          signal NM_Gateway_NM_aktiv_ZM_XIX_NMH_Gateway_XIX_E3V_CCAN: start 38, 1 bit, little-endian, data-type-policy=OVERRIDE, i-signal-type=PRIMITIVE, init-value=0, base-type=BT_NM_Gateway_NM_aktiv_ZM, compu {0=Cx0_Inaktiv (CM_NM_Gateway_NM_aktiv_ZM_Cx0_Inaktiv), 1=Cx1_ZM_aktiv (CM_NM_Gateway_NM_aktiv_ZM_Cx1_ZM_aktiv)}, range raw 0..1, transfer-property=TRIGGERED  # Dieser Bus wird auf Grund einer Aktivität des Zeitmasters wachgehalten
          signal NM_Gateway_NM_aktiv_FoD_XIX_NMH_Gateway_XIX_E3V_CCAN: start 39, 1 bit, little-endian, data-type-policy=OVERRIDE, i-signal-type=PRIMITIVE, init-value=0, base-type=BT_NM_Gateway_NM_aktiv_FoD, compu {0=Cx0_Inaktiv (CM_NM_Gateway_NM_aktiv_FoD_Cx0_Inaktiv), 1=Cx1_FoD_aktiv (CM_NM_Gateway_NM_aktiv_FoD_Cx1_FoD_aktiv)}, range raw 0..1, transfer-property=TRIGGERED  # Dieser Bus wird auf Grund einer Aktivität der Function on Demand wachgehalten
          signal NM_Gateway_CAB_V15_XIX_NMH_Gateway_XIX_E3V_CCAN: start 40, 24 bit, opaque, data-type-policy=OVERRIDE, i-signal-type=ARRAY, init-value=[0b00000000, 0b00000000, 0b00000000], base-type=BT_NM_Gateway_CAB_V15, compu {0=Cx0_Init (CM_NM_Gateway_CAB_V15_Cx0_Init), 1=Cx1_CAB_01_Antrieb (CM_NM_Gateway_CAB_V15_Cx1_CAB_01_Antrieb), 2=Cx2_CAB_02_Hybrid_Laden (CM_NM_Gateway_CAB_V15_Cx2_CAB_02_Hybrid_Laden), 4=Cx4_CAB_03_Fahrwerk (CM_NM_Gateway_CAB_V15_Cx4_CAB_03_Fahrwerk), 8=Cx8_CAB_04_Fahrerassistenz (CM_NM_Gateway_CAB_V15_Cx8_CAB_04_Fahrerassistenz), 16=Cx10_CAB_05_Komfort (CM_NM_Gateway_CAB_V15_Cx10_CAB_05_Komfort), 32=Cx20_CAB_06_Anzeige (CM_NM_Gateway_CAB_V15_Cx20_CAB_06_Anzeige), 64=Cx40_CAB_07_Connect (CM_NM_Gateway_CAB_V15_Cx40_CAB_07_Connect), 128=Cx80_CAB_08_MIB (CM_NM_Gateway_CAB_V15_Cx80_CAB_08_MIB), 256=Cx100_CAB_09_Standheizung (CM_NM_Gateway_CAB_V15_Cx100_CAB_09_Standheizung), 512=Cx200_CAB_10_MDK (CM_NM_Gateway_CAB_V15_Cx200_CAB_10_MDK), 1024=Cx400_CAB_11_VLAN_Fahrerassistenz (CM_NM_Gateway_CAB_V15_Cx400_CAB_11_VLAN_Fahrerassistenz), 4096=Cx1000_CAB_13_VLAN_Connect (CM_NM_Gateway_CAB_V15_Cx1000_CAB_13_VLAN_Connect), 8192=Cx2000_CAB_14_VLAN_Infotainment (CM_NM_Gateway_CAB_V15_Cx2000_CAB_14_VLAN_Infotainment), 16384=Cx4000_CAB_15_Laden (CM_NM_Gateway_CAB_V15_Cx4000_CAB_15_Laden), 32768=Cx8000_CAB_16_Licht (CM_NM_Gateway_CAB_V15_Cx8000_CAB_16_Licht), 65536=Cx10000_CAB_17_RTM (CM_NM_Gateway_CAB_V15_Cx10000_CAB_17_RTM)}, range raw 0..65536, transfer-property=TRIGGERED  # CAB = Clusteraktivbits (V15)
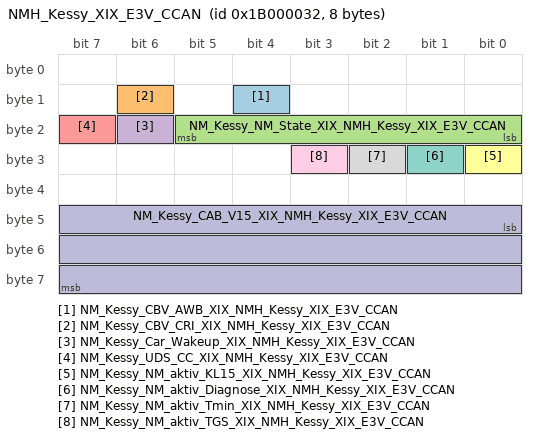
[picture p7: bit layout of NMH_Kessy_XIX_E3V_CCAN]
      frame NMH_Kessy_XIX_E3V_CCAN: id 0x1B000032, to SAM, frame-length=8, can-addressing-mode=EXTENDED, can-frame-rx-behavior=CAN-20, can-frame-tx-behavior=CAN-20, rx-identifier-range={lower-can-id=452984832, upper-can-id=452985855}
        nm pdu NMH_Kessy_XIX_E3V_CCAN: length=8, unused-bit-pattern=0
          signal NM_Kessy_CBV_AWB_XIX_NMH_Kessy_XIX_E3V_CCAN: start 12, 1 bit, little-endian, data-type-policy=OVERRIDE, i-signal-type=PRIMITIVE, init-value=0, base-type=BT_NM_Kessy_CBV_AWB, compu {0=Cx0_Passiver_WakeUp (CM_NM_Kessy_CBV_AWB_Cx0_Passiver_WakeUp), 1=Cx1_Aktiver_WakeUp (CM_NM_Kessy_CBV_AWB_Cx1_Aktiver_WakeUp)}, range raw 0..1, transfer-property=TRIGGERED  # Das Signal ist zu setzen, wenn das SG aktiv den Bus geweckt hat
          signal NM_Kessy_CBV_CRI_XIX_NMH_Kessy_XIX_E3V_CCAN: start 14, 1 bit, little-endian, data-type-policy=OVERRIDE, i-signal-type=PRIMITIVE, base-type=BT_NM_Kessy_CBV_CRI, compu {0=Cx0_Standard_Layout (CM_NM_Kessy_CBV_CRI_Cx0_Standard_Layout), 1=Cx1_TNB_Layout (CM_NM_Kessy_CBV_CRI_Cx1_TNB_Layout)}, range raw 0..1, transfer-property=TRIGGERED  # Das Signal ist dauerhaft gesetzt, wenn das NM-Layout dem neuen NM-Layout für Teilnetzbetrieb entspricht
          signal NM_Kessy_NM_State_XIX_NMH_Kessy_XIX_E3V_CCAN: start 16, 6 bit, little-endian, data-type-policy=OVERRIDE, i-signal-type=PRIMITIVE, init-value=0, base-type=BT_NM_Kessy_NM_State, compu {1=Cx1_NM_RM_aus_BSM (CM_NM_Kessy_NM_State_Cx1_NM_RM_aus_BSM), 2=Cx2_NM_RM_aus_PBSM (CM_NM_Kessy_NM_State_Cx2_NM_RM_aus_PBSM), 4=Cx4_NM_NO_aus_RM (CM_NM_Kessy_NM_State_Cx4_NM_NO_aus_RM), 8=Cx8_NM_NO_aus_RS (CM_NM_Kessy_NM_State_Cx8_NM_NO_aus_RS)}, range raw 1..8, transfer-property=TRIGGERED, to SAM(timeout 2 s)  # 1 = Zustand Repeat Message (<-- Bus-Sleep Mode) 2 = Zustand Repeat Message (<-- Prepare Bus-Sleep Mode) 4 = Zustand Normal Operation (<-- Repeat Message) 8 = Zustand Normal Operation (<-- Ready Sleep)
          signal NM_Kessy_Car_Wakeup_XIX_NMH_Kessy_XIX_E3V_CCAN: start 22, 1 bit, little-endian, data-type-policy=OVERRIDE, i-signal-type=PRIMITIVE, init-value=0, base-type=BT_NM_Kessy_Car_Wakeup, compu {0=Cx0_Inaktiv (CM_NM_Kessy_Car_Wakeup_Cx0_Inaktiv), 1=Cx1_Car_Wakeup (CM_NM_Kessy_Car_Wakeup_Cx1_Car_Wakeup)}, range raw 0..1, transfer-property=TRIGGERED  # Car Wakeup (Gateway wertet aus) MQB: ZAT Betätigung (ZAT = Zündanlass-Taster) bei Zündung == AUS (vor Einschalten Klemme 15 durch das Kessy, muss eine gültige Geschwindigkeitsinformation vom ESC empfangen werden)
          signal NM_Kessy_UDS_CC_XIX_NMH_Kessy_XIX_E3V_CCAN: start 23, 1 bit, little-endian, data-type-policy=OVERRIDE, i-signal-type=PRIMITIVE, init-value=0, base-type=BT_NM_Kessy_UDS_CC, compu {0=Cx0_Init (CM_NM_Kessy_UDS_CC_Cx0_Init), 1=Cx1_CC_aktiv (CM_NM_Kessy_UDS_CC_Cx1_CC_aktiv)}, range raw 0..1, transfer-property=TRIGGERED  # Funktionseinschränkung aufgrund aktivem UDS-Communication Control; siehe VW80124
          signal NM_Kessy_NM_aktiv_KL15_XIX_NMH_Kessy_XIX_E3V_CCAN: start 24, 1 bit, little-endian, data-type-policy=OVERRIDE, i-signal-type=PRIMITIVE, init-value=0, base-type=BT_NM_Kessy_NM_aktiv_KL15, compu {0=Cx0_Inaktiv (CM_NM_Kessy_NM_aktiv_KL15_Cx0_Inaktiv), 1=Cx1_KL15_EIN (CM_NM_Kessy_NM_aktiv_KL15_Cx1_KL15_EIN)}, range raw 0..1, transfer-property=TRIGGERED  # Steuergerät hat KL15-EIN erkannt
          signal NM_Kessy_NM_aktiv_Diagnose_XIX_NMH_Kessy_XIX_E3V_CCAN: start 25, 1 bit, little-endian, data-type-policy=OVERRIDE, i-signal-type=PRIMITIVE, init-value=0, base-type=BT_NM_Kessy_NM_aktiv_Diagnose, compu {0=Cx0_Init (CM_NM_Kessy_NM_aktiv_Diagnose_Cx0_Init), 1=Cx1_Diagnose_aktiv (CM_NM_Kessy_NM_aktiv_Diagnose_Cx1_Diagnose_aktiv)}, range raw 0..1, transfer-property=TRIGGERED  # Diagnose befindet sich nach VW80124 in einer NonDefaultDiagnostic-Session, z.B. ExtendedDiagnostic-Session
          signal NM_Kessy_NM_aktiv_Tmin_XIX_NMH_Kessy_XIX_E3V_CCAN: start 26, 1 bit, little-endian, data-type-policy=OVERRIDE, i-signal-type=PRIMITIVE, init-value=0, base-type=BT_NM_Kessy_NM_aktiv_Tmin, compu {0=Cx0_Inaktiv (CM_NM_Kessy_NM_aktiv_Tmin_Cx0_Inaktiv), 1=Cx1_Mindestaktivzeit (CM_NM_Kessy_NM_aktiv_Tmin_Cx1_Mindestaktivzeit)}, range raw 0..1, transfer-property=TRIGGERED  # Mindestaktivzeit ist noch nicht abgelaufen (bei jedem Weckereignis wird die Mindestaktivzeit neu gestartet)
          signal NM_Kessy_NM_aktiv_TGS_XIX_NMH_Kessy_XIX_E3V_CCAN: start 27, 1 bit, little-endian, data-type-policy=OVERRIDE, i-signal-type=PRIMITIVE, init-value=0, base-type=BT_NM_Kessy_NM_aktiv_TGS, compu {0=Cx0_Init (CM_NM_Kessy_NM_aktiv_TGS_Cx0_Init), 1=Cx1_TGS_aktiv (CM_NM_Kessy_NM_aktiv_TGS_Cx1_TGS_aktiv)}, range raw 0..1, transfer-property=TRIGGERED  # TGS ist aktiv
          signal NM_Kessy_CAB_V15_XIX_NMH_Kessy_XIX_E3V_CCAN: start 40, 24 bit, opaque, data-type-policy=OVERRIDE, i-signal-type=ARRAY, init-value=[0b00000000, 0b00000000, 0b00000000], base-type=BT_NM_Kessy_CAB_V15, compu {0=Cx0_Init (CM_NM_Kessy_CAB_V15_Cx0_Init), 1=Cx1_CAB_01_Antrieb (CM_NM_Kessy_CAB_V15_Cx1_CAB_01_Antrieb), 2=Cx2_CAB_02_Hybrid_Laden (CM_NM_Kessy_CAB_V15_Cx2_CAB_02_Hybrid_Laden), 4=Cx4_CAB_03_Fahrwerk (CM_NM_Kessy_CAB_V15_Cx4_CAB_03_Fahrwerk), 8=Cx8_CAB_04_Fahrerassistenz (CM_NM_Kessy_CAB_V15_Cx8_CAB_04_Fahrerassistenz), 16=Cx10_CAB_05_Komfort (CM_NM_Kessy_CAB_V15_Cx10_CAB_05_Komfort), 32=Cx20_CAB_06_Anzeige (CM_NM_Kessy_CAB_V15_Cx20_CAB_06_Anzeige), 64=Cx40_CAB_07_Connect (CM_NM_Kessy_CAB_V15_Cx40_CAB_07_Connect), 128=Cx80_CAB_08_MIB (CM_NM_Kessy_CAB_V15_Cx80_CAB_08_MIB), 256=Cx100_CAB_09_Standheizung (CM_NM_Kessy_CAB_V15_Cx100_CAB_09_Standheizung), 512=Cx200_CAB_10_MDK (CM_NM_Kessy_CAB_V15_Cx200_CAB_10_MDK), 1024=Cx400_CAB_11_VLAN_Fahrerassistenz (CM_NM_Kessy_CAB_V15_Cx400_CAB_11_VLAN_Fahrerassistenz), 4096=Cx1000_CAB_13_VLAN_Connect (CM_NM_Kessy_CAB_V15_Cx1000_CAB_13_VLAN_Connect), 8192=Cx2000_CAB_14_VLAN_Infotainment (CM_NM_Kessy_CAB_V15_Cx2000_CAB_14_VLAN_Infotainment), 16384=Cx4000_CAB_15_Laden (CM_NM_Kessy_CAB_V15_Cx4000_CAB_15_Laden), 32768=Cx8000_CAB_16_Licht (CM_NM_Kessy_CAB_V15_Cx8000_CAB_16_Licht), 65536=Cx10000_CAB_17_RTM (CM_NM_Kessy_CAB_V15_Cx10000_CAB_17_RTM)}, range raw 0..65536, transfer-property=TRIGGERED  # CAB = Clusteraktivbits (V15)
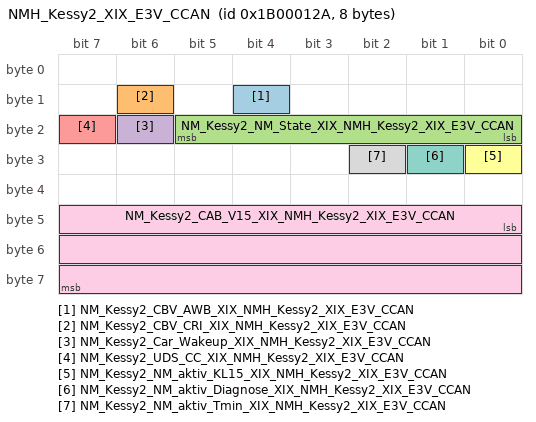
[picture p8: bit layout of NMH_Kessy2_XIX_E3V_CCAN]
      frame NMH_Kessy2_XIX_E3V_CCAN: id 0x1B00012A, to SAM, frame-length=8, can-addressing-mode=EXTENDED, can-frame-rx-behavior=CAN-20, can-frame-tx-behavior=CAN-20, rx-identifier-range={lower-can-id=452984832, upper-can-id=452985855}
        nm pdu NMH_Kessy2_XIX_E3V_CCAN: length=8, unused-bit-pattern=0
          signal NM_Kessy2_CBV_AWB_XIX_NMH_Kessy2_XIX_E3V_CCAN: start 12, 1 bit, little-endian, data-type-policy=OVERRIDE, i-signal-type=PRIMITIVE, init-value=0, base-type=BT_NM_Kessy2_CBV_AWB, compu {0=Cx0_Passiver_WakeUp (CM_NM_Kessy2_CBV_AWB_Cx0_Passiver_WakeUp), 1=Cx1_Aktiver_WakeUp (CM_NM_Kessy2_CBV_AWB_Cx1_Aktiver_WakeUp)}, range raw 0..1, transfer-property=TRIGGERED  # Das Signal ist zu setzen, wenn das SG aktiv den Bus geweckt hat
          signal NM_Kessy2_CBV_CRI_XIX_NMH_Kessy2_XIX_E3V_CCAN: start 14, 1 bit, little-endian, data-type-policy=OVERRIDE, i-signal-type=PRIMITIVE, base-type=BT_NM_Kessy2_CBV_CRI, compu {0=Cx0_Standard_Layout (CM_NM_Kessy2_CBV_CRI_Cx0_Standard_Layout), 1=Cx1_TNB_Layout (CM_NM_Kessy2_CBV_CRI_Cx1_TNB_Layout)}, range raw 0..1, transfer-property=TRIGGERED  # Das Signal ist dauerhaft gesetzt, wenn das NM-Layout dem neuen NM-Layout für Teilnetzbetrieb entspricht
          signal NM_Kessy2_NM_State_XIX_NMH_Kessy2_XIX_E3V_CCAN: start 16, 6 bit, little-endian, data-type-policy=OVERRIDE, i-signal-type=PRIMITIVE, init-value=0, base-type=BT_NM_Kessy2_NM_State, compu {0=Cx0_Init (CM_NM_Kessy2_NM_State_Cx0_Init), 1=Cx1_NM_RM_aus_BSM (CM_NM_Kessy2_NM_State_Cx1_NM_RM_aus_BSM), 2=Cx2_NM_RM_aus_PBSM (CM_NM_Kessy2_NM_State_Cx2_NM_RM_aus_PBSM), 4=Cx4_NM_NO_aus_RM (CM_NM_Kessy2_NM_State_Cx4_NM_NO_aus_RM), 8=Cx8_NM_NO_aus_RS (CM_NM_Kessy2_NM_State_Cx8_NM_NO_aus_RS), 16=Cx10_reserved (CM_NM_Kessy2_NM_State_Cx10_reserved), 32=Cx20_reserved (CM_NM_Kessy2_NM_State_Cx20_reserved)}, range raw 0..32, transfer-property=TRIGGERED, to SAM(timeout 2 s)  # 1 = Zustand Repeat Message (<-- Bus-Sleep Mode) 2 = Zustand Repeat Message (<-- Prepare Bus-Sleep Mode) 4 = Zustand Normal Operation (<-- Repeat Message) 8 = Zustand Normal Operation (<-- Ready Sleep)
          signal NM_Kessy2_Car_Wakeup_XIX_NMH_Kessy2_XIX_E3V_CCAN: start 22, 1 bit, little-endian, data-type-policy=OVERRIDE, i-signal-type=PRIMITIVE, init-value=0, base-type=BT_NM_Kessy2_Car_Wakeup, compu {0=Cx0_Inaktiv (CM_NM_Kessy2_Car_Wakeup_Cx0_Inaktiv), 1=Cx1_Car_Wakeup (CM_NM_Kessy2_Car_Wakeup_Cx1_Car_Wakeup)}, range raw 0..1, transfer-property=TRIGGERED  # Car Wakeup (Busmaster wertet aus)
          signal NM_Kessy2_UDS_CC_XIX_NMH_Kessy2_XIX_E3V_CCAN: start 23, 1 bit, little-endian, data-type-policy=OVERRIDE, i-signal-type=PRIMITIVE, init-value=0, base-type=BT_NM_Kessy2_UDS_CC, compu {0=Cx0_Init (CM_NM_Kessy2_UDS_CC_Cx0_Init), 1=Cx1_CC_aktiv (CM_NM_Kessy2_UDS_CC_Cx1_CC_aktiv)}, range raw 0..1, transfer-property=TRIGGERED  # Funktionseinschränkung aufgrund aktivem UDS-Communication Control; siehe VW80124
          signal NM_Kessy2_NM_aktiv_KL15_XIX_NMH_Kessy2_XIX_E3V_CCAN: start 24, 1 bit, little-endian, data-type-policy=OVERRIDE, i-signal-type=PRIMITIVE, init-value=0, base-type=BT_NM_Kessy2_NM_aktiv_KL15, compu {0=Cx0_Inaktiv (CM_NM_Kessy2_NM_aktiv_KL15_Cx0_Inaktiv), 1=Cx1_KL15_EIN (CM_NM_Kessy2_NM_aktiv_KL15_Cx1_KL15_EIN)}, range raw 0..1, transfer-property=TRIGGERED  # Steuergerät hat KL15-EIN erkannt
          signal NM_Kessy2_NM_aktiv_Diagnose_XIX_NMH_Kessy2_XIX_E3V_CCAN: start 25, 1 bit, little-endian, data-type-policy=OVERRIDE, i-signal-type=PRIMITIVE, init-value=0, base-type=BT_NM_Kessy2_NM_aktiv_Diagnose, compu {0=Cx0_Init (CM_NM_Kessy2_NM_aktiv_Diagnose_Cx0_Init), 1=Cx1_Diagnose_aktiv (CM_NM_Kessy2_NM_aktiv_Diagnose_Cx1_Diagnose_aktiv)}, range raw 0..1, transfer-property=TRIGGERED  # Diagnose befindet sich nach VW80124 in einer NonDefaultDiagnostic-Session, z.B. ExtendedDiagnostic-Session
          signal NM_Kessy2_NM_aktiv_Tmin_XIX_NMH_Kessy2_XIX_E3V_CCAN: start 26, 1 bit, little-endian, data-type-policy=OVERRIDE, i-signal-type=PRIMITIVE, init-value=0, base-type=BT_NM_Kessy2_NM_aktiv_Tmin, compu {0=Cx0_Inaktiv (CM_NM_Kessy2_NM_aktiv_Tmin_Cx0_Inaktiv), 1=Cx1_Mindestaktivzeit (CM_NM_Kessy2_NM_aktiv_Tmin_Cx1_Mindestaktivzeit)}, range raw 0..1, transfer-property=TRIGGERED  # Mindestaktivzeit ist noch nicht abgelaufen (bei jedem Weckereignis wird die Mindestaktivzeit neu gestartet)
          signal NM_Kessy2_CAB_V15_XIX_NMH_Kessy2_XIX_E3V_CCAN: start 40, 24 bit, opaque, data-type-policy=OVERRIDE, i-signal-type=ARRAY, init-value=[0b00000000, 0b00000000, 0b00000000], base-type=BT_NM_Kessy2_CAB_V15, compu {0=Cx0_Init (CM_NM_Kessy2_CAB_V15_Cx0_Init), 1=Cx1_CAB_01_Antrieb (CM_NM_Kessy2_CAB_V15_Cx1_CAB_01_Antrieb), 2=Cx2_CAB_02_Hybrid_Laden (CM_NM_Kessy2_CAB_V15_Cx2_CAB_02_Hybrid_Laden), 4=Cx4_CAB_03_Fahrwerk (CM_NM_Kessy2_CAB_V15_Cx4_CAB_03_Fahrwerk), 8=Cx8_CAB_04_Fahrerassistenz (CM_NM_Kessy2_CAB_V15_Cx8_CAB_04_Fahrerassistenz), 16=Cx10_CAB_05_Komfort (CM_NM_Kessy2_CAB_V15_Cx10_CAB_05_Komfort), 32=Cx20_CAB_06_Anzeige (CM_NM_Kessy2_CAB_V15_Cx20_CAB_06_Anzeige), 64=Cx40_CAB_07_Connect (CM_NM_Kessy2_CAB_V15_Cx40_CAB_07_Connect), 128=Cx80_CAB_08_MIB (CM_NM_Kessy2_CAB_V15_Cx80_CAB_08_MIB), 256=Cx100_CAB_09_Standheizung (CM_NM_Kessy2_CAB_V15_Cx100_CAB_09_Standheizung), 512=Cx200_CAB_10_MDK (CM_NM_Kessy2_CAB_V15_Cx200_CAB_10_MDK), 1024=Cx400_CAB_11_VLAN_Fahrerassistenz (CM_NM_Kessy2_CAB_V15_Cx400_CAB_11_VLAN_Fahrerassistenz), 4096=Cx1000_CAB_13_VLAN_Connect (CM_NM_Kessy2_CAB_V15_Cx1000_CAB_13_VLAN_Connect), 8192=Cx2000_CAB_14_VLAN_Infotainment (CM_NM_Kessy2_CAB_V15_Cx2000_CAB_14_VLAN_Infotainment), 16384=Cx4000_CAB_15_Laden (CM_NM_Kessy2_CAB_V15_Cx4000_CAB_15_Laden), 32768=Cx8000_CAB_16_Licht (CM_NM_Kessy2_CAB_V15_Cx8000_CAB_16_Licht), 65536=Cx10000_CAB_17_RTM (CM_NM_Kessy2_CAB_V15_Cx10000_CAB_17_RTM)}, range raw 0..65536, transfer-property=TRIGGERED  # CAB = Clusteraktivbits (V15)
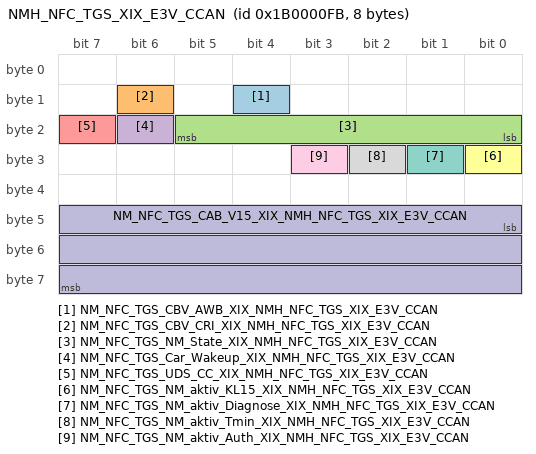
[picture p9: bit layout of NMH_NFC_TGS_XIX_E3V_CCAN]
      frame NMH_NFC_TGS_XIX_E3V_CCAN: id 0x1B0000FB, to SAM, frame-length=8, can-addressing-mode=EXTENDED, can-frame-rx-behavior=CAN-20, can-frame-tx-behavior=CAN-20, rx-identifier-range={lower-can-id=452984832, upper-can-id=452985855}
        nm pdu NMH_NFC_TGS_XIX_E3V_CCAN: length=8, unused-bit-pattern=0
          signal NM_NFC_TGS_CBV_AWB_XIX_NMH_NFC_TGS_XIX_E3V_CCAN: start 12, 1 bit, little-endian, data-type-policy=OVERRIDE, i-signal-type=PRIMITIVE, init-value=0, base-type=BT_NM_NFC_TGS_CBV_AWB, compu {0=Cx0_Passiver_WakeUp (CM_NM_NFC_TGS_CBV_AWB_Cx0_Passiver_WakeUp), 1=Cx1_Aktiver_WakeUp (CM_NM_NFC_TGS_CBV_AWB_Cx1_Aktiver_WakeUp)}, range raw 0..1, transfer-property=TRIGGERED  # Das Signal ist zu setzen, wenn das SG aktiv den Bus geweckt hat
          signal NM_NFC_TGS_CBV_CRI_XIX_NMH_NFC_TGS_XIX_E3V_CCAN: start 14, 1 bit, little-endian, data-type-policy=OVERRIDE, i-signal-type=PRIMITIVE, init-value=0, base-type=BT_NM_NFC_TGS_CBV_CRI, compu {0=Cx0_Standard_Layout (CM_NM_NFC_TGS_CBV_CRI_Cx0_Standard_Layout), 1=Cx1_TNB_Layout (CM_NM_NFC_TGS_CBV_CRI_Cx1_TNB_Layout)}, range raw 0..1, transfer-property=TRIGGERED  # Das Signal ist dauerhaft gesetzt, wenn das NM-Layout dem neuen NM-Layout für Teilnetzbetrieb entspricht
          signal NM_NFC_TGS_NM_State_XIX_NMH_NFC_TGS_XIX_E3V_CCAN: start 16, 6 bit, little-endian, data-type-policy=OVERRIDE, i-signal-type=PRIMITIVE, init-value=0, base-type=BT_NM_NFC_TGS_NM_State, compu {0=Cx0_Init (CM_NM_NFC_TGS_NM_State_Cx0_Init), 1=Cx1_NM_RM_aus_BSM (CM_NM_NFC_TGS_NM_State_Cx1_NM_RM_aus_BSM), 2=Cx2_NM_RM_aus_PBSM (CM_NM_NFC_TGS_NM_State_Cx2_NM_RM_aus_PBSM), 4=Cx4_NM_NO_aus_RM (CM_NM_NFC_TGS_NM_State_Cx4_NM_NO_aus_RM), 8=Cx8_NM_NO_aus_RS (CM_NM_NFC_TGS_NM_State_Cx8_NM_NO_aus_RS), 16=Cx10_reserved (CM_NM_NFC_TGS_NM_State_Cx10_reserved), 32=Cx20_reserved (CM_NM_NFC_TGS_NM_State_Cx20_reserved)}, range raw 0..32, transfer-property=TRIGGERED, to SAM(timeout 2 s)  # 1 = Zustand Repeat Message (<-- Bus-Sleep Mode) 2 = Zustand Repeat Message (<-- Prepare Bus-Sleep Mode) 4 = Zustand Normal Operation (<-- Repeat Message) 8 = Zustand Normal Operation (<-- Ready Sleep)
          signal NM_NFC_TGS_Car_Wakeup_XIX_NMH_NFC_TGS_XIX_E3V_CCAN: start 22, 1 bit, little-endian, data-type-policy=OVERRIDE, i-signal-type=PRIMITIVE, init-value=0, base-type=BT_NM_NFC_TGS_Car_Wakeup, compu {0=Cx0_Inaktiv (CM_NM_NFC_TGS_Car_Wakeup_Cx0_Inaktiv), 1=Cx1_Car_Wakeup (CM_NM_NFC_TGS_Car_Wakeup_Cx1_Car_Wakeup)}, range raw 0..1, transfer-property=TRIGGERED  # Car Wakeup
          signal NM_NFC_TGS_UDS_CC_XIX_NMH_NFC_TGS_XIX_E3V_CCAN: start 23, 1 bit, little-endian, data-type-policy=OVERRIDE, i-signal-type=PRIMITIVE, init-value=0, base-type=BT_NM_NFC_TGS_UDS_CC, compu {0=Cx0_Init (CM_NM_NFC_TGS_UDS_CC_Cx0_Init), 1=Cx1_CC_aktiv (CM_NM_NFC_TGS_UDS_CC_Cx1_CC_aktiv)}, range raw 0..1, transfer-property=TRIGGERED  # Funktionseinschränkung aufgrund aktivem UDS-Communication Control; siehe VW80124
          signal NM_NFC_TGS_NM_aktiv_KL15_XIX_NMH_NFC_TGS_XIX_E3V_CCAN: start 24, 1 bit, little-endian, data-type-policy=OVERRIDE, i-signal-type=PRIMITIVE, init-value=0, base-type=BT_NM_NFC_TGS_NM_aktiv_KL15, compu {0=Cx0_Inaktiv (CM_NM_NFC_TGS_NM_aktiv_KL15_Cx0_Inaktiv), 1=Cx1_KL15_EIN (CM_NM_NFC_TGS_NM_aktiv_KL15_Cx1_KL15_EIN)}, range raw 0..1, transfer-property=TRIGGERED  # Steuergerät hat KL15-EIN erkannt
          signal NM_NFC_TGS_NM_aktiv_Diagnose_XIX_NMH_NFC_TGS_XIX_E3V_CCAN: start 25, 1 bit, little-endian, data-type-policy=OVERRIDE, i-signal-type=PRIMITIVE, init-value=0, base-type=BT_NM_NFC_TGS_NM_aktiv_Diagnose, compu {0=Cx0_Init (CM_NM_NFC_TGS_NM_aktiv_Diagnose_Cx0_Init), 1=Cx1_Diagnose_aktiv (CM_NM_NFC_TGS_NM_aktiv_Diagnose_Cx1_Diagnose_aktiv)}, range raw 0..1, transfer-property=TRIGGERED  # Diagnose befindet sich nach VW80124 in einer NonDefaultDiagnostic-Session, z.B. ExtendedDiagnostic-Session
          signal NM_NFC_TGS_NM_aktiv_Tmin_XIX_NMH_NFC_TGS_XIX_E3V_CCAN: start 26, 1 bit, little-endian, data-type-policy=OVERRIDE, i-signal-type=PRIMITIVE, init-value=0, base-type=BT_NM_NFC_TGS_NM_aktiv_Tmin, compu {0=Cx0_Inaktiv (CM_NM_NFC_TGS_NM_aktiv_Tmin_Cx0_Inaktiv), 1=Cx1_Mindestaktivzeit (CM_NM_NFC_TGS_NM_aktiv_Tmin_Cx1_Mindestaktivzeit)}, range raw 0..1, transfer-property=TRIGGERED  # Mindestaktivzeit ist noch nicht abgelaufen (bei jedem Weckereignis wird die Mindestaktivzeit neu gestartet)
          signal NM_NFC_TGS_NM_aktiv_Auth_XIX_NMH_NFC_TGS_XIX_E3V_CCAN: start 27, 1 bit, little-endian, data-type-policy=OVERRIDE, i-signal-type=PRIMITIVE, init-value=0, base-type=BT_NM_NFC_TGS_NM_aktiv_Auth, compu {0=Cx0_Init (CM_NM_NFC_TGS_NM_aktiv_Auth_Cx0_Init), 1=Cx1_NFC_Kommuniktion_aktiv (CM_NM_NFC_TGS_NM_aktiv_Auth_Cx1_NFC_Kommuniktion_aktiv)}, range raw 0..1, transfer-property=TRIGGERED  # NFC-Gerät wird authentifiziert / NFC Kommunikation notwendig
          signal NM_NFC_TGS_CAB_V15_XIX_NMH_NFC_TGS_XIX_E3V_CCAN: start 40, 24 bit, opaque, data-type-policy=OVERRIDE, i-signal-type=ARRAY, init-value=[0b00000000, 0b00000000, 0b00000000], base-type=BT_NM_NFC_TGS_CAB_V15, compu {0=Cx0_Init (CM_NM_NFC_TGS_CAB_V15_Cx0_Init), 1=Cx1_CAB_01_Antrieb (CM_NM_NFC_TGS_CAB_V15_Cx1_CAB_01_Antrieb), 2=Cx2_CAB_02_Hybrid_Laden (CM_NM_NFC_TGS_CAB_V15_Cx2_CAB_02_Hybrid_Laden), 4=Cx4_CAB_03_Fahrwerk (CM_NM_NFC_TGS_CAB_V15_Cx4_CAB_03_Fahrwerk), 8=Cx8_CAB_04_Fahrerassistenz (CM_NM_NFC_TGS_CAB_V15_Cx8_CAB_04_Fahrerassistenz), 16=Cx10_CAB_05_Komfort (CM_NM_NFC_TGS_CAB_V15_Cx10_CAB_05_Komfort), 32=Cx20_CAB_06_Anzeige (CM_NM_NFC_TGS_CAB_V15_Cx20_CAB_06_Anzeige), 64=Cx40_CAB_07_Connect (CM_NM_NFC_TGS_CAB_V15_Cx40_CAB_07_Connect), 128=Cx80_CAB_08_MIB (CM_NM_NFC_TGS_CAB_V15_Cx80_CAB_08_MIB), 256=Cx100_CAB_09_Standheizung (CM_NM_NFC_TGS_CAB_V15_Cx100_CAB_09_Standheizung), 512=Cx200_CAB_10_MDK (CM_NM_NFC_TGS_CAB_V15_Cx200_CAB_10_MDK), 1024=Cx400_CAB_11_VLAN_Fahrerassistenz (CM_NM_NFC_TGS_CAB_V15_Cx400_CAB_11_VLAN_Fahrerassistenz), 4096=Cx1000_CAB_13_VLAN_Connect (CM_NM_NFC_TGS_CAB_V15_Cx1000_CAB_13_VLAN_Connect), 8192=Cx2000_CAB_14_VLAN_Infotainment (CM_NM_NFC_TGS_CAB_V15_Cx2000_CAB_14_VLAN_Infotainment), 16384=Cx4000_CAB_15_Laden (CM_NM_NFC_TGS_CAB_V15_Cx4000_CAB_15_Laden), 32768=Cx8000_CAB_16_Licht (CM_NM_NFC_TGS_CAB_V15_Cx8000_CAB_16_Licht), 65536=Cx10000_CAB_17_RTM (CM_NM_NFC_TGS_CAB_V15_Cx10000_CAB_17_RTM)}, range raw 0..65536, transfer-property=TRIGGERED  # CAB = Clusteraktivbits (V15)
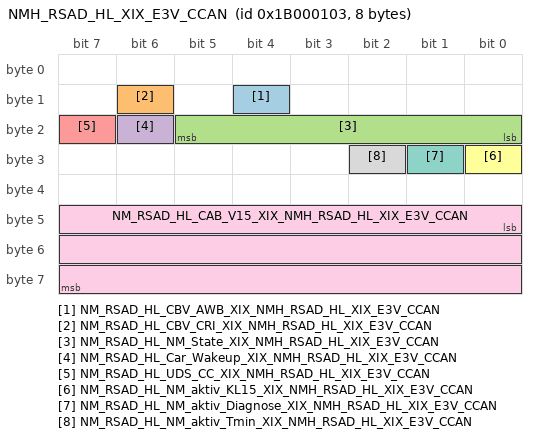
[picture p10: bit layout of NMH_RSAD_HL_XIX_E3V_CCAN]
      frame NMH_RSAD_HL_XIX_E3V_CCAN: id 0x1B000103, to SAM, frame-length=8, can-addressing-mode=EXTENDED, can-frame-rx-behavior=CAN-20, can-frame-tx-behavior=CAN-20, rx-identifier-range={lower-can-id=452984832, upper-can-id=452985855}
        nm pdu NMH_RSAD_HL_XIX_E3V_CCAN: length=8, unused-bit-pattern=0
          signal NM_RSAD_HL_CBV_AWB_XIX_NMH_RSAD_HL_XIX_E3V_CCAN: start 12, 1 bit, little-endian, data-type-policy=OVERRIDE, i-signal-type=PRIMITIVE, init-value=0, base-type=BT_NM_RSAD_HL_CBV_AWB, compu {0=Cx0_Passiver_WakeUp (CM_NM_RSAD_HL_CBV_AWB_Cx0_Passiver_WakeUp), 1=Cx1_Aktiver_WakeUp (CM_NM_RSAD_HL_CBV_AWB_Cx1_Aktiver_WakeUp)}, range raw 0..1, transfer-property=TRIGGERED  # Das Signal ist zu setzen, wenn das SG aktiv den Bus geweckt hat 0 = Passiver_WakeUp = SG hat das Netzwerk nicht aktiv geweckt 1 = Akitiver_WakeUp = SG hat das Netzwerk aktiv geweckt
          signal NM_RSAD_HL_CBV_CRI_XIX_NMH_RSAD_HL_XIX_E3V_CCAN: start 14, 1 bit, little-endian, data-type-policy=OVERRIDE, i-signal-type=PRIMITIVE, init-value=0, base-type=BT_NM_RSAD_HL_CBV_CRI, compu {0=Cx0_NM_ohne_Clusteranforderungen (CM_NM_RSAD_HL_CBV_CRI_Cx0_NM_ohne_Clusteranforderungen), 1=Cx1_NM_mit_Clusteranforderungen (CM_NM_RSAD_HL_CBV_CRI_Cx1_NM_mit_Clusteranforderungen)}, range raw 0..1, transfer-property=TRIGGERED  # Das Signal ist dauerhaft gesetzt, wenn das NM-Layout Cluster- Anforderungen enthält
          signal NM_RSAD_HL_NM_State_XIX_NMH_RSAD_HL_XIX_E3V_CCAN: start 16, 6 bit, little-endian, data-type-policy=OVERRIDE, i-signal-type=PRIMITIVE, init-value=0, base-type=BT_NM_RSAD_HL_NM_State, compu {0=Cx0_Init (CM_NM_RSAD_HL_NM_State_Cx0_Init), 1=Cx1_NM_RM_aus_BSM (CM_NM_RSAD_HL_NM_State_Cx1_NM_RM_aus_BSM), 2=Cx2_NM_RM_aus_PBSM (CM_NM_RSAD_HL_NM_State_Cx2_NM_RM_aus_PBSM), 4=Cx4_NM_NO_aus_RM (CM_NM_RSAD_HL_NM_State_Cx4_NM_NO_aus_RM), 8=Cx8_NM_NO_aus_RS (CM_NM_RSAD_HL_NM_State_Cx8_NM_NO_aus_RS), 16=Cx10_reserved (CM_NM_RSAD_HL_NM_State_Cx10_reserved), 32=Cx20_reserved (CM_NM_RSAD_HL_NM_State_Cx20_reserved)}, range raw 0..32, transfer-property=TRIGGERED, to SAM(timeout 2 s)  # 1 = Zustand Repeat Message (<-- Bus-Sleep Mode) 2 = Zustand Repeat Message (<-- Prepare Bus-Sleep Mode) 4 = Zustand Normal Operation (<-- Repeat Message) 8 = Zustand Normal Operation (<-- Ready Sleep)
          signal NM_RSAD_HL_Car_Wakeup_XIX_NMH_RSAD_HL_XIX_E3V_CCAN: start 22, 1 bit, little-endian, data-type-policy=OVERRIDE, i-signal-type=PRIMITIVE, init-value=0, base-type=BT_NM_RSAD_HL_Car_Wakeup, compu {0=Cx0_Inaktiv (CM_NM_RSAD_HL_Car_Wakeup_Cx0_Inaktiv), 1=Cx1_Car_Wakeup (CM_NM_RSAD_HL_Car_Wakeup_Cx1_Car_Wakeup)}, range raw 0..1, transfer-property=TRIGGERED  # Car Wakeup (Busmaster wertet aus)
          signal NM_RSAD_HL_UDS_CC_XIX_NMH_RSAD_HL_XIX_E3V_CCAN: start 23, 1 bit, little-endian, data-type-policy=OVERRIDE, i-signal-type=PRIMITIVE, init-value=0, base-type=BT_NM_RSAD_HL_UDS_CC, compu {0=Cx0_Inaktiv (CM_NM_RSAD_HL_UDS_CC_Cx0_Inaktiv), 1=Cx1_CC_aktiv (CM_NM_RSAD_HL_UDS_CC_Cx1_CC_aktiv)}, range raw 0..1, transfer-property=TRIGGERED  # Funktionseinschränkung aufgrund aktivem UDS-Communication Control, siehe VW80124
          signal NM_RSAD_HL_NM_aktiv_KL15_XIX_NMH_RSAD_HL_XIX_E3V_CCAN: start 24, 1 bit, little-endian, data-type-policy=OVERRIDE, i-signal-type=PRIMITIVE, init-value=0, base-type=BT_NM_RSAD_HL_NM_aktiv_KL15, compu {0=Cx0_Inaktiv (CM_NM_RSAD_HL_NM_aktiv_KL15_Cx0_Inaktiv), 1=Cx1_KL15_EIN (CM_NM_RSAD_HL_NM_aktiv_KL15_Cx1_KL15_EIN)}, range raw 0..1, transfer-property=TRIGGERED  # Steuergerät hat KL15-EIN erkannt
          signal NM_RSAD_HL_NM_aktiv_Diagnose_XIX_NMH_RSAD_HL_XIX_E3V_CCAN: start 25, 1 bit, little-endian, data-type-policy=OVERRIDE, i-signal-type=PRIMITIVE, init-value=0, base-type=BT_NM_RSAD_HL_NM_aktiv_Diagnose, compu {0=Cx0_Init (CM_NM_RSAD_HL_NM_aktiv_Diagnose_Cx0_Init), 1=Cx1_Diagnose_aktiv (CM_NM_RSAD_HL_NM_aktiv_Diagnose_Cx1_Diagnose_aktiv)}, range raw 0..1, transfer-property=TRIGGERED  # Diagnose befindet sich nach VW80124 in einer NonDefaultDiagnostic-Session, z.B. ExtendedDiagnostic-Session
          signal NM_RSAD_HL_NM_aktiv_Tmin_XIX_NMH_RSAD_HL_XIX_E3V_CCAN: start 26, 1 bit, little-endian, data-type-policy=OVERRIDE, i-signal-type=PRIMITIVE, init-value=0, base-type=BT_NM_RSAD_HL_NM_aktiv_Tmin, compu {0=Cx0_Inaktiv (CM_NM_RSAD_HL_NM_aktiv_Tmin_Cx0_Inaktiv), 1=Cx1_Mindestaktivzeit (CM_NM_RSAD_HL_NM_aktiv_Tmin_Cx1_Mindestaktivzeit)}, range raw 0..1, transfer-property=TRIGGERED  # Mindestaktivzeit ist noch nicht abgelaufen (bei jedem Weckereignis wird die Mindestaktivzeit neu gestartet)
          signal NM_RSAD_HL_CAB_V15_XIX_NMH_RSAD_HL_XIX_E3V_CCAN: start 40, 24 bit, opaque, data-type-policy=OVERRIDE, i-signal-type=ARRAY, base-type=BT_NM_RSAD_HL_CAB_V15, compu {0=Cx0_Init (CM_NM_RSAD_HL_CAB_V15_Cx0_Init), 1=Cx1_CAB_01_Antrieb (CM_NM_RSAD_HL_CAB_V15_Cx1_CAB_01_Antrieb), 2=Cx2_CAB_02_Hybrid_Laden (CM_NM_RSAD_HL_CAB_V15_Cx2_CAB_02_Hybrid_Laden), 4=Cx4_CAB_03_Fahrwerk (CM_NM_RSAD_HL_CAB_V15_Cx4_CAB_03_Fahrwerk), 8=Cx8_CAB_04_Fahrerassistenz (CM_NM_RSAD_HL_CAB_V15_Cx8_CAB_04_Fahrerassistenz), 16=Cx10_CAB_05_Komfort (CM_NM_RSAD_HL_CAB_V15_Cx10_CAB_05_Komfort), 32=Cx20_CAB_06_Anzeige (CM_NM_RSAD_HL_CAB_V15_Cx20_CAB_06_Anzeige), 64=Cx40_CAB_07_Connect (CM_NM_RSAD_HL_CAB_V15_Cx40_CAB_07_Connect), 128=Cx80_CAB_08_MIB (CM_NM_RSAD_HL_CAB_V15_Cx80_CAB_08_MIB), 256=Cx100_CAB_09_Standheizung (CM_NM_RSAD_HL_CAB_V15_Cx100_CAB_09_Standheizung), 512=Cx200_CAB_10_MDK (CM_NM_RSAD_HL_CAB_V15_Cx200_CAB_10_MDK), 1024=Cx400_CAB_11_VLAN_Fahrerassistenz (CM_NM_RSAD_HL_CAB_V15_Cx400_CAB_11_VLAN_Fahrerassistenz), 4096=Cx1000_CAB_13_VLAN_Connect (CM_NM_RSAD_HL_CAB_V15_Cx1000_CAB_13_VLAN_Connect), 8192=Cx2000_CAB_14_VLAN_Infotainment (CM_NM_RSAD_HL_CAB_V15_Cx2000_CAB_14_VLAN_Infotainment), 16384=Cx4000_CAB_15_Laden (CM_NM_RSAD_HL_CAB_V15_Cx4000_CAB_15_Laden), 32768=Cx8000_CAB_16_Licht (CM_NM_RSAD_HL_CAB_V15_Cx8000_CAB_16_Licht), 65536=Cx10000_CAB_17_RTM (CM_NM_RSAD_HL_CAB_V15_Cx10000_CAB_17_RTM)}, range raw 0..65536, transfer-property=TRIGGERED  # CAB = Clusteraktivbits (V15)
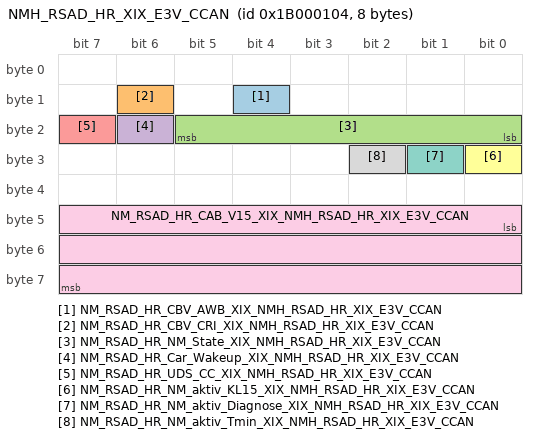
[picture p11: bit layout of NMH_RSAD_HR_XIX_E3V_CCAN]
      frame NMH_RSAD_HR_XIX_E3V_CCAN: id 0x1B000104, to SAM, frame-length=8, can-addressing-mode=EXTENDED, can-frame-rx-behavior=CAN-20, can-frame-tx-behavior=CAN-20, rx-identifier-range={lower-can-id=452984832, upper-can-id=452985855}
        nm pdu NMH_RSAD_HR_XIX_E3V_CCAN: length=8, unused-bit-pattern=0
          signal NM_RSAD_HR_CBV_AWB_XIX_NMH_RSAD_HR_XIX_E3V_CCAN: start 12, 1 bit, little-endian, data-type-policy=OVERRIDE, i-signal-type=PRIMITIVE, init-value=0, base-type=BT_NM_RSAD_HR_CBV_AWB, compu {0=Cx0_Passiver_WakeUp (CM_NM_RSAD_HR_CBV_AWB_Cx0_Passiver_WakeUp), 1=Cx1_Aktiver_WakeUp (CM_NM_RSAD_HR_CBV_AWB_Cx1_Aktiver_WakeUp)}, range raw 0..1, transfer-property=TRIGGERED  # Das Signal ist zu setzen, wenn das SG aktiv den Bus geweckt hat 0 = Passiver_WakeUp = SG hat das Netzwerk nicht aktiv geweckt 1 = Akitiver_WakeUp = SG hat das Netzwerk aktiv geweckt
          signal NM_RSAD_HR_CBV_CRI_XIX_NMH_RSAD_HR_XIX_E3V_CCAN: start 14, 1 bit, little-endian, data-type-policy=OVERRIDE, i-signal-type=PRIMITIVE, init-value=0, base-type=BT_NM_RSAD_HR_CBV_CRI, compu {0=Cx0_NM_ohne_Clusteranforderungen (CM_NM_RSAD_HR_CBV_CRI_Cx0_NM_ohne_Clusteranforderungen), 1=Cx1_NM_mit_Clusteranforderungen (CM_NM_RSAD_HR_CBV_CRI_Cx1_NM_mit_Clusteranforderungen)}, range raw 0..1, transfer-property=TRIGGERED  # Das Signal ist dauerhaft gesetzt, wenn das NM-Layout Cluster- Anforderungen enthält
          signal NM_RSAD_HR_NM_State_XIX_NMH_RSAD_HR_XIX_E3V_CCAN: start 16, 6 bit, little-endian, data-type-policy=OVERRIDE, i-signal-type=PRIMITIVE, init-value=0, base-type=BT_NM_RSAD_HR_NM_State, compu {0=Cx0_Init (CM_NM_RSAD_HR_NM_State_Cx0_Init), 1=Cx1_NM_RM_aus_BSM (CM_NM_RSAD_HR_NM_State_Cx1_NM_RM_aus_BSM), 2=Cx2_NM_RM_aus_PBSM (CM_NM_RSAD_HR_NM_State_Cx2_NM_RM_aus_PBSM), 4=Cx4_NM_NO_aus_RM (CM_NM_RSAD_HR_NM_State_Cx4_NM_NO_aus_RM), 8=Cx8_NM_NO_aus_RS (CM_NM_RSAD_HR_NM_State_Cx8_NM_NO_aus_RS), 16=Cx10_reserved (CM_NM_RSAD_HR_NM_State_Cx10_reserved), 32=Cx20_reserved (CM_NM_RSAD_HR_NM_State_Cx20_reserved)}, range raw 0..32, transfer-property=TRIGGERED, to SAM(timeout 2 s)  # 1 = Zustand Repeat Message (<-- Bus-Sleep Mode) 2 = Zustand Repeat Message (<-- Prepare Bus-Sleep Mode) 4 = Zustand Normal Operation (<-- Repeat Message) 8 = Zustand Normal Operation (<-- Ready Sleep)
          signal NM_RSAD_HR_Car_Wakeup_XIX_NMH_RSAD_HR_XIX_E3V_CCAN: start 22, 1 bit, little-endian, data-type-policy=OVERRIDE, i-signal-type=PRIMITIVE, init-value=0, base-type=BT_NM_RSAD_HR_Car_Wakeup, compu {0=Cx0_Inaktiv (CM_NM_RSAD_HR_Car_Wakeup_Cx0_Inaktiv), 1=Cx1_Car_Wakeup (CM_NM_RSAD_HR_Car_Wakeup_Cx1_Car_Wakeup)}, range raw 0..1, transfer-property=TRIGGERED  # Car Wakeup (Busmaster wertet aus)
          signal NM_RSAD_HR_UDS_CC_XIX_NMH_RSAD_HR_XIX_E3V_CCAN: start 23, 1 bit, little-endian, data-type-policy=OVERRIDE, i-signal-type=PRIMITIVE, init-value=0, base-type=BT_NM_RSAD_HR_UDS_CC, compu {0=Cx0_Inaktiv (CM_NM_RSAD_HR_UDS_CC_Cx0_Inaktiv), 1=Cx1_CC_aktiv (CM_NM_RSAD_HR_UDS_CC_Cx1_CC_aktiv)}, range raw 0..1, transfer-property=TRIGGERED  # Funktionseinschränkung aufgrund aktivem UDS-Communication Control, siehe VW80124
          signal NM_RSAD_HR_NM_aktiv_KL15_XIX_NMH_RSAD_HR_XIX_E3V_CCAN: start 24, 1 bit, little-endian, data-type-policy=OVERRIDE, i-signal-type=PRIMITIVE, init-value=0, base-type=BT_NM_RSAD_HR_NM_aktiv_KL15, compu {0=Cx0_Inaktiv (CM_NM_RSAD_HR_NM_aktiv_KL15_Cx0_Inaktiv), 1=Cx1_KL15_EIN (CM_NM_RSAD_HR_NM_aktiv_KL15_Cx1_KL15_EIN)}, range raw 0..1, transfer-property=TRIGGERED  # Steuergerät hat KL15-EIN erkannt
          signal NM_RSAD_HR_NM_aktiv_Diagnose_XIX_NMH_RSAD_HR_XIX_E3V_CCAN: start 25, 1 bit, little-endian, data-type-policy=OVERRIDE, i-signal-type=PRIMITIVE, init-value=0, base-type=BT_NM_RSAD_HR_NM_aktiv_Diagnose, compu {0=Cx0_Init (CM_NM_RSAD_HR_NM_aktiv_Diagnose_Cx0_Init), 1=Cx1_Diagnose_aktiv (CM_NM_RSAD_HR_NM_aktiv_Diagnose_Cx1_Diagnose_aktiv)}, range raw 0..1, transfer-property=TRIGGERED  # Diagnose befindet sich nach VW80124 in einer NonDefaultDiagnostic-Session, z.B. ExtendedDiagnostic-Session
          signal NM_RSAD_HR_NM_aktiv_Tmin_XIX_NMH_RSAD_HR_XIX_E3V_CCAN: start 26, 1 bit, little-endian, data-type-policy=OVERRIDE, i-signal-type=PRIMITIVE, init-value=0, base-type=BT_NM_RSAD_HR_NM_aktiv_Tmin, compu {0=Cx0_Inaktiv (CM_NM_RSAD_HR_NM_aktiv_Tmin_Cx0_Inaktiv), 1=Cx1_Mindestaktivzeit (CM_NM_RSAD_HR_NM_aktiv_Tmin_Cx1_Mindestaktivzeit)}, range raw 0..1, transfer-property=TRIGGERED  # Mindestaktivzeit ist noch nicht abgelaufen (bei jedem Weckereignis wird die Mindestaktivzeit neu gestartet)
          signal NM_RSAD_HR_CAB_V15_XIX_NMH_RSAD_HR_XIX_E3V_CCAN: start 40, 24 bit, opaque, data-type-policy=OVERRIDE, i-signal-type=ARRAY, base-type=BT_NM_RSAD_HR_CAB_V15, compu {0=Cx0_Init (CM_NM_RSAD_HR_CAB_V15_Cx0_Init), 1=Cx1_CAB_01_Antrieb (CM_NM_RSAD_HR_CAB_V15_Cx1_CAB_01_Antrieb), 2=Cx2_CAB_02_Hybrid_Laden (CM_NM_RSAD_HR_CAB_V15_Cx2_CAB_02_Hybrid_Laden), 4=Cx4_CAB_03_Fahrwerk (CM_NM_RSAD_HR_CAB_V15_Cx4_CAB_03_Fahrwerk), 8=Cx8_CAB_04_Fahrerassistenz (CM_NM_RSAD_HR_CAB_V15_Cx8_CAB_04_Fahrerassistenz), 16=Cx10_CAB_05_Komfort (CM_NM_RSAD_HR_CAB_V15_Cx10_CAB_05_Komfort), 32=Cx20_CAB_06_Anzeige (CM_NM_RSAD_HR_CAB_V15_Cx20_CAB_06_Anzeige), 64=Cx40_CAB_07_Connect (CM_NM_RSAD_HR_CAB_V15_Cx40_CAB_07_Connect), 128=Cx80_CAB_08_MIB (CM_NM_RSAD_HR_CAB_V15_Cx80_CAB_08_MIB), 256=Cx100_CAB_09_Standheizung (CM_NM_RSAD_HR_CAB_V15_Cx100_CAB_09_Standheizung), 512=Cx200_CAB_10_MDK (CM_NM_RSAD_HR_CAB_V15_Cx200_CAB_10_MDK), 1024=Cx400_CAB_11_VLAN_Fahrerassistenz (CM_NM_RSAD_HR_CAB_V15_Cx400_CAB_11_VLAN_Fahrerassistenz), 4096=Cx1000_CAB_13_VLAN_Connect (CM_NM_RSAD_HR_CAB_V15_Cx1000_CAB_13_VLAN_Connect), 8192=Cx2000_CAB_14_VLAN_Infotainment (CM_NM_RSAD_HR_CAB_V15_Cx2000_CAB_14_VLAN_Infotainment), 16384=Cx4000_CAB_15_Laden (CM_NM_RSAD_HR_CAB_V15_Cx4000_CAB_15_Laden), 32768=Cx8000_CAB_16_Licht (CM_NM_RSAD_HR_CAB_V15_Cx8000_CAB_16_Licht), 65536=Cx10000_CAB_17_RTM (CM_NM_RSAD_HR_CAB_V15_Cx10000_CAB_17_RTM)}, range raw 0..65536, transfer-property=TRIGGERED  # CAB = Clusteraktivbits (V15)
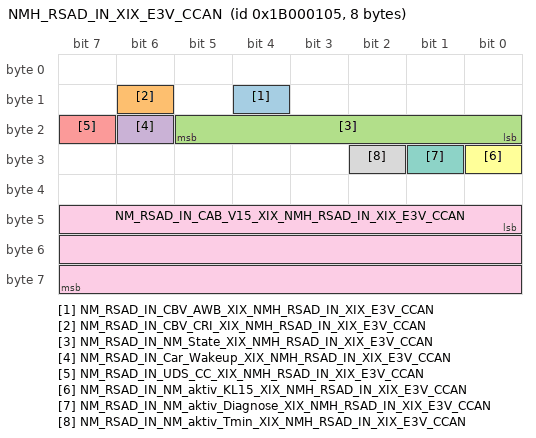
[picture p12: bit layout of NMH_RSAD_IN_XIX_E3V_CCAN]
      frame NMH_RSAD_IN_XIX_E3V_CCAN: id 0x1B000105, to SAM, frame-length=8, can-addressing-mode=EXTENDED, can-frame-rx-behavior=CAN-20, can-frame-tx-behavior=CAN-20, rx-identifier-range={lower-can-id=452984832, upper-can-id=452985855}
        nm pdu NMH_RSAD_IN_XIX_E3V_CCAN: length=8, unused-bit-pattern=0
          signal NM_RSAD_IN_CBV_AWB_XIX_NMH_RSAD_IN_XIX_E3V_CCAN: start 12, 1 bit, little-endian, data-type-policy=OVERRIDE, i-signal-type=PRIMITIVE, init-value=0, base-type=BT_NM_RSAD_IN_CBV_AWB, compu {0=Cx0_Passiver_WakeUp (CM_NM_RSAD_IN_CBV_AWB_Cx0_Passiver_WakeUp), 1=Cx1_Aktiver_WakeUp (CM_NM_RSAD_IN_CBV_AWB_Cx1_Aktiver_WakeUp)}, range raw 0..1, transfer-property=TRIGGERED  # Das Signal ist zu setzen, wenn das SG aktiv den Bus geweckt hat 0 = Passiver_WakeUp = SG hat das Netzwerk nicht aktiv geweckt 1 = Akitiver_WakeUp = SG hat das Netzwerk aktiv geweckt
          signal NM_RSAD_IN_CBV_CRI_XIX_NMH_RSAD_IN_XIX_E3V_CCAN: start 14, 1 bit, little-endian, data-type-policy=OVERRIDE, i-signal-type=PRIMITIVE, init-value=0, base-type=BT_NM_RSAD_IN_CBV_CRI, compu {0=Cx0_NM_ohne_Clusteranforderungen (CM_NM_RSAD_IN_CBV_CRI_Cx0_NM_ohne_Clusteranforderungen), 1=Cx1_NM_mit_Clusteranforderungen (CM_NM_RSAD_IN_CBV_CRI_Cx1_NM_mit_Clusteranforderungen)}, range raw 0..1, transfer-property=TRIGGERED  # Das Signal ist dauerhaft gesetzt, wenn das NM-Layout Cluster- Anforderungen enthält
          signal NM_RSAD_IN_NM_State_XIX_NMH_RSAD_IN_XIX_E3V_CCAN: start 16, 6 bit, little-endian, data-type-policy=OVERRIDE, i-signal-type=PRIMITIVE, init-value=0, base-type=BT_NM_RSAD_IN_NM_State, compu {0=Cx0_Init (CM_NM_RSAD_IN_NM_State_Cx0_Init), 1=Cx1_NM_RM_aus_BSM (CM_NM_RSAD_IN_NM_State_Cx1_NM_RM_aus_BSM), 2=Cx2_NM_RM_aus_PBSM (CM_NM_RSAD_IN_NM_State_Cx2_NM_RM_aus_PBSM), 4=Cx4_NM_NO_aus_RM (CM_NM_RSAD_IN_NM_State_Cx4_NM_NO_aus_RM), 8=Cx8_NM_NO_aus_RS (CM_NM_RSAD_IN_NM_State_Cx8_NM_NO_aus_RS), 16=Cx10_reserved (CM_NM_RSAD_IN_NM_State_Cx10_reserved), 32=Cx20_reserved (CM_NM_RSAD_IN_NM_State_Cx20_reserved)}, range raw 0..32, transfer-property=TRIGGERED, to SAM(timeout 2 s)  # 1 = Zustand Repeat Message (<-- Bus-Sleep Mode) 2 = Zustand Repeat Message (<-- Prepare Bus-Sleep Mode) 4 = Zustand Normal Operation (<-- Repeat Message) 8 = Zustand Normal Operation (<-- Ready Sleep)
          signal NM_RSAD_IN_Car_Wakeup_XIX_NMH_RSAD_IN_XIX_E3V_CCAN: start 22, 1 bit, little-endian, data-type-policy=OVERRIDE, i-signal-type=PRIMITIVE, init-value=0, base-type=BT_NM_RSAD_IN_Car_Wakeup, compu {0=Cx0_Inaktiv (CM_NM_RSAD_IN_Car_Wakeup_Cx0_Inaktiv), 1=Cx1_Car_Wakeup (CM_NM_RSAD_IN_Car_Wakeup_Cx1_Car_Wakeup)}, range raw 0..1, transfer-property=TRIGGERED  # Car Wakeup (Busmaster wertet aus)
          signal NM_RSAD_IN_UDS_CC_XIX_NMH_RSAD_IN_XIX_E3V_CCAN: start 23, 1 bit, little-endian, data-type-policy=OVERRIDE, i-signal-type=PRIMITIVE, init-value=0, base-type=BT_NM_RSAD_IN_UDS_CC, compu {0=Cx0_Inaktiv (CM_NM_RSAD_IN_UDS_CC_Cx0_Inaktiv), 1=Cx1_CC_aktiv (CM_NM_RSAD_IN_UDS_CC_Cx1_CC_aktiv)}, range raw 0..1, transfer-property=TRIGGERED  # Funktionseinschränkung aufgrund aktivem UDS-Communication Control, siehe VW80124
          signal NM_RSAD_IN_NM_aktiv_KL15_XIX_NMH_RSAD_IN_XIX_E3V_CCAN: start 24, 1 bit, little-endian, data-type-policy=OVERRIDE, i-signal-type=PRIMITIVE, init-value=0, base-type=BT_NM_RSAD_IN_NM_aktiv_KL15, compu {0=Cx0_Inaktiv (CM_NM_RSAD_IN_NM_aktiv_KL15_Cx0_Inaktiv), 1=Cx1_KL15_EIN (CM_NM_RSAD_IN_NM_aktiv_KL15_Cx1_KL15_EIN)}, range raw 0..1, transfer-property=TRIGGERED  # Steuergerät hat KL15-EIN erkannt
          signal NM_RSAD_IN_NM_aktiv_Diagnose_XIX_NMH_RSAD_IN_XIX_E3V_CCAN: start 25, 1 bit, little-endian, data-type-policy=OVERRIDE, i-signal-type=PRIMITIVE, init-value=0, base-type=BT_NM_RSAD_IN_NM_aktiv_Diagnose, compu {0=Cx0_Init (CM_NM_RSAD_IN_NM_aktiv_Diagnose_Cx0_Init), 1=Cx1_Diagnose_aktiv (CM_NM_RSAD_IN_NM_aktiv_Diagnose_Cx1_Diagnose_aktiv)}, range raw 0..1, transfer-property=TRIGGERED  # Diagnose befindet sich nach VW80124 in einer NonDefaultDiagnostic-Session, z.B. ExtendedDiagnostic-Session
          signal NM_RSAD_IN_NM_aktiv_Tmin_XIX_NMH_RSAD_IN_XIX_E3V_CCAN: start 26, 1 bit, little-endian, data-type-policy=OVERRIDE, i-signal-type=PRIMITIVE, init-value=0, base-type=BT_NM_RSAD_IN_NM_aktiv_Tmin, compu {0=Cx0_Inaktiv (CM_NM_RSAD_IN_NM_aktiv_Tmin_Cx0_Inaktiv), 1=Cx1_Mindestaktivzeit (CM_NM_RSAD_IN_NM_aktiv_Tmin_Cx1_Mindestaktivzeit)}, range raw 0..1, transfer-property=TRIGGERED  # Mindestaktivzeit ist noch nicht abgelaufen (bei jedem Weckereignis wird die Mindestaktivzeit neu gestartet)
          signal NM_RSAD_IN_CAB_V15_XIX_NMH_RSAD_IN_XIX_E3V_CCAN: start 40, 24 bit, opaque, data-type-policy=OVERRIDE, i-signal-type=ARRAY, base-type=BT_NM_RSAD_IN_CAB_V15, compu {0=Cx0_Init (CM_NM_RSAD_IN_CAB_V15_Cx0_Init), 1=Cx1_CAB_01_Antrieb (CM_NM_RSAD_IN_CAB_V15_Cx1_CAB_01_Antrieb), 2=Cx2_CAB_02_Hybrid_Laden (CM_NM_RSAD_IN_CAB_V15_Cx2_CAB_02_Hybrid_Laden), 4=Cx4_CAB_03_Fahrwerk (CM_NM_RSAD_IN_CAB_V15_Cx4_CAB_03_Fahrwerk), 8=Cx8_CAB_04_Fahrerassistenz (CM_NM_RSAD_IN_CAB_V15_Cx8_CAB_04_Fahrerassistenz), 16=Cx10_CAB_05_Komfort (CM_NM_RSAD_IN_CAB_V15_Cx10_CAB_05_Komfort), 32=Cx20_CAB_06_Anzeige (CM_NM_RSAD_IN_CAB_V15_Cx20_CAB_06_Anzeige), 64=Cx40_CAB_07_Connect (CM_NM_RSAD_IN_CAB_V15_Cx40_CAB_07_Connect), 128=Cx80_CAB_08_MIB (CM_NM_RSAD_IN_CAB_V15_Cx80_CAB_08_MIB), 256=Cx100_CAB_09_Standheizung (CM_NM_RSAD_IN_CAB_V15_Cx100_CAB_09_Standheizung), 512=Cx200_CAB_10_MDK (CM_NM_RSAD_IN_CAB_V15_Cx200_CAB_10_MDK), 1024=Cx400_CAB_11_VLAN_Fahrerassistenz (CM_NM_RSAD_IN_CAB_V15_Cx400_CAB_11_VLAN_Fahrerassistenz), 4096=Cx1000_CAB_13_VLAN_Connect (CM_NM_RSAD_IN_CAB_V15_Cx1000_CAB_13_VLAN_Connect), 8192=Cx2000_CAB_14_VLAN_Infotainment (CM_NM_RSAD_IN_CAB_V15_Cx2000_CAB_14_VLAN_Infotainment), 16384=Cx4000_CAB_15_Laden (CM_NM_RSAD_IN_CAB_V15_Cx4000_CAB_15_Laden), 32768=Cx8000_CAB_16_Licht (CM_NM_RSAD_IN_CAB_V15_Cx8000_CAB_16_Licht), 65536=Cx10000_CAB_17_RTM (CM_NM_RSAD_IN_CAB_V15_Cx10000_CAB_17_RTM)}, range raw 0..65536, transfer-property=TRIGGERED  # CAB = Clusteraktivbits (V15)
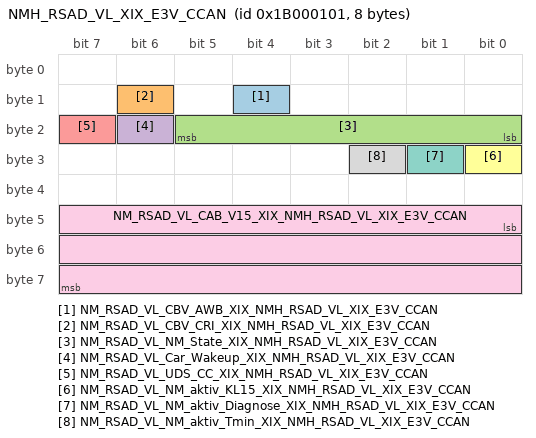
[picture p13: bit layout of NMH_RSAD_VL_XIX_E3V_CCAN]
      frame NMH_RSAD_VL_XIX_E3V_CCAN: id 0x1B000101, to SAM, frame-length=8, can-addressing-mode=EXTENDED, can-frame-rx-behavior=CAN-20, can-frame-tx-behavior=CAN-20, rx-identifier-range={lower-can-id=452984832, upper-can-id=452985855}
        nm pdu NMH_RSAD_VL_XIX_E3V_CCAN: length=8, unused-bit-pattern=0
          signal NM_RSAD_VL_CBV_AWB_XIX_NMH_RSAD_VL_XIX_E3V_CCAN: start 12, 1 bit, little-endian, data-type-policy=OVERRIDE, i-signal-type=PRIMITIVE, init-value=0, base-type=BT_NM_RSAD_VL_CBV_AWB, compu {0=Cx0_Passiver_WakeUp (CM_NM_RSAD_VL_CBV_AWB_Cx0_Passiver_WakeUp), 1=Cx1_Aktiver_WakeUp (CM_NM_RSAD_VL_CBV_AWB_Cx1_Aktiver_WakeUp)}, range raw 0..1, transfer-property=TRIGGERED  # Das Signal ist zu setzen, wenn das SG aktiv den Bus geweckt hat 0 = Passiver_WakeUp = SG hat das Netzwerk nicht aktiv geweckt 1 = Akitiver_WakeUp = SG hat das Netzwerk aktiv geweckt
          signal NM_RSAD_VL_CBV_CRI_XIX_NMH_RSAD_VL_XIX_E3V_CCAN: start 14, 1 bit, little-endian, data-type-policy=OVERRIDE, i-signal-type=PRIMITIVE, init-value=0, base-type=BT_NM_RSAD_VL_CBV_CRI, compu {0=Cx0_NM_ohne_Clusteranforderungen (CM_NM_RSAD_VL_CBV_CRI_Cx0_NM_ohne_Clusteranforderungen), 1=Cx1_NM_mit_Clusteranforderungen (CM_NM_RSAD_VL_CBV_CRI_Cx1_NM_mit_Clusteranforderungen)}, range raw 0..1, transfer-property=TRIGGERED  # Das Signal ist dauerhaft gesetzt, wenn das NM-Layout Cluster- Anforderungen enthält
          signal NM_RSAD_VL_NM_State_XIX_NMH_RSAD_VL_XIX_E3V_CCAN: start 16, 6 bit, little-endian, data-type-policy=OVERRIDE, i-signal-type=PRIMITIVE, init-value=0, base-type=BT_NM_RSAD_VL_NM_State, compu {0=Cx0_Init (CM_NM_RSAD_VL_NM_State_Cx0_Init), 1=Cx1_NM_RM_aus_BSM (CM_NM_RSAD_VL_NM_State_Cx1_NM_RM_aus_BSM), 2=Cx2_NM_RM_aus_PBSM (CM_NM_RSAD_VL_NM_State_Cx2_NM_RM_aus_PBSM), 4=Cx4_NM_NO_aus_RM (CM_NM_RSAD_VL_NM_State_Cx4_NM_NO_aus_RM), 8=Cx8_NM_NO_aus_RS (CM_NM_RSAD_VL_NM_State_Cx8_NM_NO_aus_RS), 16=Cx10_reserved (CM_NM_RSAD_VL_NM_State_Cx10_reserved), 32=Cx20_reserved (CM_NM_RSAD_VL_NM_State_Cx20_reserved)}, range raw 0..32, transfer-property=TRIGGERED, to SAM(timeout 2 s)  # 1 = Zustand Repeat Message (<-- Bus-Sleep Mode) 2 = Zustand Repeat Message (<-- Prepare Bus-Sleep Mode) 4 = Zustand Normal Operation (<-- Repeat Message) 8 = Zustand Normal Operation (<-- Ready Sleep)
          signal NM_RSAD_VL_Car_Wakeup_XIX_NMH_RSAD_VL_XIX_E3V_CCAN: start 22, 1 bit, little-endian, data-type-policy=OVERRIDE, i-signal-type=PRIMITIVE, init-value=0, base-type=BT_NM_RSAD_VL_Car_Wakeup, compu {0=Cx0_Inaktiv (CM_NM_RSAD_VL_Car_Wakeup_Cx0_Inaktiv), 1=Cx1_Car_Wakeup (CM_NM_RSAD_VL_Car_Wakeup_Cx1_Car_Wakeup)}, range raw 0..1, transfer-property=TRIGGERED  # Car Wakeup (Busmaster wertet aus)
          signal NM_RSAD_VL_UDS_CC_XIX_NMH_RSAD_VL_XIX_E3V_CCAN: start 23, 1 bit, little-endian, data-type-policy=OVERRIDE, i-signal-type=PRIMITIVE, init-value=0, base-type=BT_NM_RSAD_VL_UDS_CC, compu {0=Cx0_Inaktiv (CM_NM_RSAD_VL_UDS_CC_Cx0_Inaktiv), 1=Cx1_CC_aktiv (CM_NM_RSAD_VL_UDS_CC_Cx1_CC_aktiv)}, range raw 0..1, transfer-property=TRIGGERED  # Funktionseinschränkung aufgrund aktivem UDS-Communication Control, siehe VW80124
          signal NM_RSAD_VL_NM_aktiv_KL15_XIX_NMH_RSAD_VL_XIX_E3V_CCAN: start 24, 1 bit, little-endian, data-type-policy=OVERRIDE, i-signal-type=PRIMITIVE, init-value=0, base-type=BT_NM_RSAD_VL_NM_aktiv_KL15, compu {0=Cx0_Inaktiv (CM_NM_RSAD_VL_NM_aktiv_KL15_Cx0_Inaktiv), 1=Cx1_KL15_EIN (CM_NM_RSAD_VL_NM_aktiv_KL15_Cx1_KL15_EIN)}, range raw 0..1, transfer-property=TRIGGERED  # Steuergerät hat KL15-EIN erkannt
          signal NM_RSAD_VL_NM_aktiv_Diagnose_XIX_NMH_RSAD_VL_XIX_E3V_CCAN: start 25, 1 bit, little-endian, data-type-policy=OVERRIDE, i-signal-type=PRIMITIVE, init-value=0, base-type=BT_NM_RSAD_VL_NM_aktiv_Diagnose, compu {0=Cx0_Init (CM_NM_RSAD_VL_NM_aktiv_Diagnose_Cx0_Init), 1=Cx1_Diagnose_aktiv (CM_NM_RSAD_VL_NM_aktiv_Diagnose_Cx1_Diagnose_aktiv)}, range raw 0..1, transfer-property=TRIGGERED  # Diagnose befindet sich nach VW80124 in einer NonDefaultDiagnostic-Session, z.B. ExtendedDiagnostic-Session
          signal NM_RSAD_VL_NM_aktiv_Tmin_XIX_NMH_RSAD_VL_XIX_E3V_CCAN: start 26, 1 bit, little-endian, data-type-policy=OVERRIDE, i-signal-type=PRIMITIVE, init-value=0, base-type=BT_NM_RSAD_VL_NM_aktiv_Tmin, compu {0=Cx0_Inaktiv (CM_NM_RSAD_VL_NM_aktiv_Tmin_Cx0_Inaktiv), 1=Cx1_Mindestaktivzeit (CM_NM_RSAD_VL_NM_aktiv_Tmin_Cx1_Mindestaktivzeit)}, range raw 0..1, transfer-property=TRIGGERED  # Mindestaktivzeit ist noch nicht abgelaufen (bei jedem Weckereignis wird die Mindestaktivzeit neu gestartet)
          signal NM_RSAD_VL_CAB_V15_XIX_NMH_RSAD_VL_XIX_E3V_CCAN: start 40, 24 bit, opaque, data-type-policy=OVERRIDE, i-signal-type=ARRAY, base-type=BT_NM_RSAD_VL_CAB_V15, compu {0=Cx0_Init (CM_NM_RSAD_VL_CAB_V15_Cx0_Init), 1=Cx1_CAB_01_Antrieb (CM_NM_RSAD_VL_CAB_V15_Cx1_CAB_01_Antrieb), 2=Cx2_CAB_02_Hybrid_Laden (CM_NM_RSAD_VL_CAB_V15_Cx2_CAB_02_Hybrid_Laden), 4=Cx4_CAB_03_Fahrwerk (CM_NM_RSAD_VL_CAB_V15_Cx4_CAB_03_Fahrwerk), 8=Cx8_CAB_04_Fahrerassistenz (CM_NM_RSAD_VL_CAB_V15_Cx8_CAB_04_Fahrerassistenz), 16=Cx10_CAB_05_Komfort (CM_NM_RSAD_VL_CAB_V15_Cx10_CAB_05_Komfort), 32=Cx20_CAB_06_Anzeige (CM_NM_RSAD_VL_CAB_V15_Cx20_CAB_06_Anzeige), 64=Cx40_CAB_07_Connect (CM_NM_RSAD_VL_CAB_V15_Cx40_CAB_07_Connect), 128=Cx80_CAB_08_MIB (CM_NM_RSAD_VL_CAB_V15_Cx80_CAB_08_MIB), 256=Cx100_CAB_09_Standheizung (CM_NM_RSAD_VL_CAB_V15_Cx100_CAB_09_Standheizung), 512=Cx200_CAB_10_MDK (CM_NM_RSAD_VL_CAB_V15_Cx200_CAB_10_MDK), 1024=Cx400_CAB_11_VLAN_Fahrerassistenz (CM_NM_RSAD_VL_CAB_V15_Cx400_CAB_11_VLAN_Fahrerassistenz), 4096=Cx1000_CAB_13_VLAN_Connect (CM_NM_RSAD_VL_CAB_V15_Cx1000_CAB_13_VLAN_Connect), 8192=Cx2000_CAB_14_VLAN_Infotainment (CM_NM_RSAD_VL_CAB_V15_Cx2000_CAB_14_VLAN_Infotainment), 16384=Cx4000_CAB_15_Laden (CM_NM_RSAD_VL_CAB_V15_Cx4000_CAB_15_Laden), 32768=Cx8000_CAB_16_Licht (CM_NM_RSAD_VL_CAB_V15_Cx8000_CAB_16_Licht), 65536=Cx10000_CAB_17_RTM (CM_NM_RSAD_VL_CAB_V15_Cx10000_CAB_17_RTM)}, range raw 0..65536, transfer-property=TRIGGERED  # CAB = Clusteraktivbits (V15)
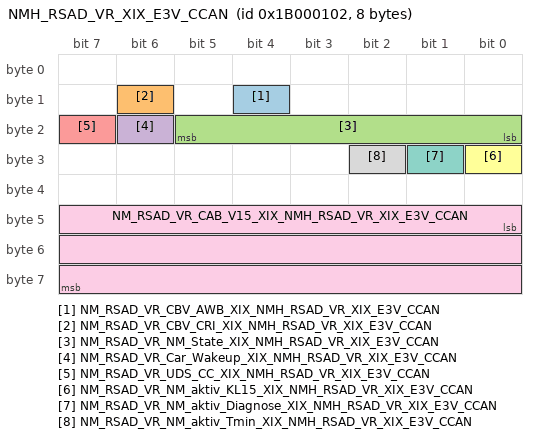
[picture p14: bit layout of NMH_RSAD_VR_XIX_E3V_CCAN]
      frame NMH_RSAD_VR_XIX_E3V_CCAN: id 0x1B000102, to SAM, frame-length=8, can-addressing-mode=EXTENDED, can-frame-rx-behavior=CAN-20, can-frame-tx-behavior=CAN-20, rx-identifier-range={lower-can-id=452984832, upper-can-id=452985855}
        nm pdu NMH_RSAD_VR_XIX_E3V_CCAN: length=8, unused-bit-pattern=0
          signal NM_RSAD_VR_CBV_AWB_XIX_NMH_RSAD_VR_XIX_E3V_CCAN: start 12, 1 bit, little-endian, data-type-policy=OVERRIDE, i-signal-type=PRIMITIVE, init-value=0, base-type=BT_NM_RSAD_VR_CBV_AWB, compu {0=Cx0_Passiver_WakeUp (CM_NM_RSAD_VR_CBV_AWB_Cx0_Passiver_WakeUp), 1=Cx1_Aktiver_WakeUp (CM_NM_RSAD_VR_CBV_AWB_Cx1_Aktiver_WakeUp)}, range raw 0..1, transfer-property=TRIGGERED  # Das Signal ist zu setzen, wenn das SG aktiv den Bus geweckt hat 0 = Passiver_WakeUp = SG hat das Netzwerk nicht aktiv geweckt 1 = Akitiver_WakeUp = SG hat das Netzwerk aktiv geweckt
          signal NM_RSAD_VR_CBV_CRI_XIX_NMH_RSAD_VR_XIX_E3V_CCAN: start 14, 1 bit, little-endian, data-type-policy=OVERRIDE, i-signal-type=PRIMITIVE, init-value=0, base-type=BT_NM_RSAD_VR_CBV_CRI, compu {0=Cx0_NM_ohne_Clusteranforderungen (CM_NM_RSAD_VR_CBV_CRI_Cx0_NM_ohne_Clusteranforderungen), 1=Cx1_NM_mit_Clusteranforderungen (CM_NM_RSAD_VR_CBV_CRI_Cx1_NM_mit_Clusteranforderungen)}, range raw 0..1, transfer-property=TRIGGERED  # Das Signal ist dauerhaft gesetzt, wenn das NM-Layout Cluster- Anforderungen enthält
          signal NM_RSAD_VR_NM_State_XIX_NMH_RSAD_VR_XIX_E3V_CCAN: start 16, 6 bit, little-endian, data-type-policy=OVERRIDE, i-signal-type=PRIMITIVE, init-value=0, base-type=BT_NM_RSAD_VR_NM_State, compu {0=Cx0_Init (CM_NM_RSAD_VR_NM_State_Cx0_Init), 1=Cx1_NM_RM_aus_BSM (CM_NM_RSAD_VR_NM_State_Cx1_NM_RM_aus_BSM), 2=Cx2_NM_RM_aus_PBSM (CM_NM_RSAD_VR_NM_State_Cx2_NM_RM_aus_PBSM), 4=Cx4_NM_NO_aus_RM (CM_NM_RSAD_VR_NM_State_Cx4_NM_NO_aus_RM), 8=Cx8_NM_NO_aus_RS (CM_NM_RSAD_VR_NM_State_Cx8_NM_NO_aus_RS), 16=Cx10_reserved (CM_NM_RSAD_VR_NM_State_Cx10_reserved), 32=Cx20_reserved (CM_NM_RSAD_VR_NM_State_Cx20_reserved)}, range raw 0..32, transfer-property=TRIGGERED, to SAM(timeout 2 s)  # 1 = Zustand Repeat Message (<-- Bus-Sleep Mode) 2 = Zustand Repeat Message (<-- Prepare Bus-Sleep Mode) 4 = Zustand Normal Operation (<-- Repeat Message) 8 = Zustand Normal Operation (<-- Ready Sleep)
          signal NM_RSAD_VR_Car_Wakeup_XIX_NMH_RSAD_VR_XIX_E3V_CCAN: start 22, 1 bit, little-endian, data-type-policy=OVERRIDE, i-signal-type=PRIMITIVE, init-value=0, base-type=BT_NM_RSAD_VR_Car_Wakeup, compu {0=Cx0_Inaktiv (CM_NM_RSAD_VR_Car_Wakeup_Cx0_Inaktiv), 1=Cx1_Car_Wakeup (CM_NM_RSAD_VR_Car_Wakeup_Cx1_Car_Wakeup)}, range raw 0..1, transfer-property=TRIGGERED  # Car Wakeup (Busmaster wertet aus)
          signal NM_RSAD_VR_UDS_CC_XIX_NMH_RSAD_VR_XIX_E3V_CCAN: start 23, 1 bit, little-endian, data-type-policy=OVERRIDE, i-signal-type=PRIMITIVE, init-value=0, base-type=BT_NM_RSAD_VR_UDS_CC, compu {0=Cx0_Inaktiv (CM_NM_RSAD_VR_UDS_CC_Cx0_Inaktiv), 1=Cx1_CC_aktiv (CM_NM_RSAD_VR_UDS_CC_Cx1_CC_aktiv)}, range raw 0..1, transfer-property=TRIGGERED  # Funktionseinschränkung aufgrund aktivem UDS-Communication Control, siehe VW80124
          signal NM_RSAD_VR_NM_aktiv_KL15_XIX_NMH_RSAD_VR_XIX_E3V_CCAN: start 24, 1 bit, little-endian, data-type-policy=OVERRIDE, i-signal-type=PRIMITIVE, init-value=0, base-type=BT_NM_RSAD_VR_NM_aktiv_KL15, compu {0=Cx0_Inaktiv (CM_NM_RSAD_VR_NM_aktiv_KL15_Cx0_Inaktiv), 1=Cx1_KL15_EIN (CM_NM_RSAD_VR_NM_aktiv_KL15_Cx1_KL15_EIN)}, range raw 0..1, transfer-property=TRIGGERED  # Steuergerät hat KL15-EIN erkannt
          signal NM_RSAD_VR_NM_aktiv_Diagnose_XIX_NMH_RSAD_VR_XIX_E3V_CCAN: start 25, 1 bit, little-endian, data-type-policy=OVERRIDE, i-signal-type=PRIMITIVE, init-value=0, base-type=BT_NM_RSAD_VR_NM_aktiv_Diagnose, compu {0=Cx0_Init (CM_NM_RSAD_VR_NM_aktiv_Diagnose_Cx0_Init), 1=Cx1_Diagnose_aktiv (CM_NM_RSAD_VR_NM_aktiv_Diagnose_Cx1_Diagnose_aktiv)}, range raw 0..1, transfer-property=TRIGGERED  # Diagnose befindet sich nach VW80124 in einer NonDefaultDiagnostic-Session, z.B. ExtendedDiagnostic-Session
          signal NM_RSAD_VR_NM_aktiv_Tmin_XIX_NMH_RSAD_VR_XIX_E3V_CCAN: start 26, 1 bit, little-endian, data-type-policy=OVERRIDE, i-signal-type=PRIMITIVE, init-value=0, base-type=BT_NM_RSAD_VR_NM_aktiv_Tmin, compu {0=Cx0_Inaktiv (CM_NM_RSAD_VR_NM_aktiv_Tmin_Cx0_Inaktiv), 1=Cx1_Mindestaktivzeit (CM_NM_RSAD_VR_NM_aktiv_Tmin_Cx1_Mindestaktivzeit)}, range raw 0..1, transfer-property=TRIGGERED  # Mindestaktivzeit ist noch nicht abgelaufen (bei jedem Weckereignis wird die Mindestaktivzeit neu gestartet)
          signal NM_RSAD_VR_CAB_V15_XIX_NMH_RSAD_VR_XIX_E3V_CCAN: start 40, 24 bit, opaque, data-type-policy=OVERRIDE, i-signal-type=ARRAY, base-type=BT_NM_RSAD_VR_CAB_V15, compu {0=Cx0_Init (CM_NM_RSAD_VR_CAB_V15_Cx0_Init), 1=Cx1_CAB_01_Antrieb (CM_NM_RSAD_VR_CAB_V15_Cx1_CAB_01_Antrieb), 2=Cx2_CAB_02_Hybrid_Laden (CM_NM_RSAD_VR_CAB_V15_Cx2_CAB_02_Hybrid_Laden), 4=Cx4_CAB_03_Fahrwerk (CM_NM_RSAD_VR_CAB_V15_Cx4_CAB_03_Fahrwerk), 8=Cx8_CAB_04_Fahrerassistenz (CM_NM_RSAD_VR_CAB_V15_Cx8_CAB_04_Fahrerassistenz), 16=Cx10_CAB_05_Komfort (CM_NM_RSAD_VR_CAB_V15_Cx10_CAB_05_Komfort), 32=Cx20_CAB_06_Anzeige (CM_NM_RSAD_VR_CAB_V15_Cx20_CAB_06_Anzeige), 64=Cx40_CAB_07_Connect (CM_NM_RSAD_VR_CAB_V15_Cx40_CAB_07_Connect), 128=Cx80_CAB_08_MIB (CM_NM_RSAD_VR_CAB_V15_Cx80_CAB_08_MIB), 256=Cx100_CAB_09_Standheizung (CM_NM_RSAD_VR_CAB_V15_Cx100_CAB_09_Standheizung), 512=Cx200_CAB_10_MDK (CM_NM_RSAD_VR_CAB_V15_Cx200_CAB_10_MDK), 1024=Cx400_CAB_11_VLAN_Fahrerassistenz (CM_NM_RSAD_VR_CAB_V15_Cx400_CAB_11_VLAN_Fahrerassistenz), 4096=Cx1000_CAB_13_VLAN_Connect (CM_NM_RSAD_VR_CAB_V15_Cx1000_CAB_13_VLAN_Connect), 8192=Cx2000_CAB_14_VLAN_Infotainment (CM_NM_RSAD_VR_CAB_V15_Cx2000_CAB_14_VLAN_Infotainment), 16384=Cx4000_CAB_15_Laden (CM_NM_RSAD_VR_CAB_V15_Cx4000_CAB_15_Laden), 32768=Cx8000_CAB_16_Licht (CM_NM_RSAD_VR_CAB_V15_Cx8000_CAB_16_Licht), 65536=Cx10000_CAB_17_RTM (CM_NM_RSAD_VR_CAB_V15_Cx10000_CAB_17_RTM)}, range raw 0..65536, transfer-property=TRIGGERED  # CAB = Clusteraktivbits (V15)
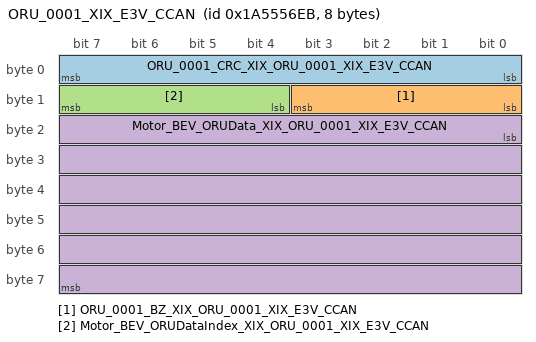
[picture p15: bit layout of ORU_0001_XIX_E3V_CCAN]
      frame ORU_0001_XIX_E3V_CCAN: id 0x1A5556EB, to SAM, frame-length=8, can-addressing-mode=EXTENDED, can-frame-rx-behavior=CAN-20, can-frame-tx-behavior=CAN-20
        pdu ORU_0001_XIX_E3V_CCAN_E2E: length=8, transmission-mode-true-timing=event-controlled-timing={number-of-repetitions=0, repetition-period=0.0}, unused-bit-pattern=0  # Fuer die Botschaft ist das Cyclic-Timing 0.5 zu verwenden.
          signal ORU_0001_CRC_XIX_ORU_0001_XIX_E3V_CCAN: start 0, 8 bit, little-endian, data-type-policy=OVERRIDE, i-signal-type=PRIMITIVE, init-value=0, base-type=BT_ORU_0001_CRC, compu {phys=raw for raw 0..255}, range phys 0..255, raw 0..255, to SAM(timeout 5 s)  # Für MLB: Berechnung siehe Lastenheft "Kommunikationsabsicherung für FlexRay und CAN" Ab MQB und MLBevo: Berechnung siehe Lastenheft "End-to-End Kommunikationsabsicherung" Endwerte siehe Begleitdokument "S-PDU Kennungsfolgen"
          signal ORU_0001_BZ_XIX_ORU_0001_XIX_E3V_CCAN: start 8, 4 bit, little-endian, data-type-policy=OVERRIDE, i-signal-type=PRIMITIVE, init-value=0, base-type=BT_ORU_0001_BZ, compu {phys=raw for raw 0..15}, range phys 0..15, raw 0..15, to SAM(timeout 5 s)  # 4bit Botschaftszähler, wird mit jeder Sendebotschaft inkrementiert
          signal Motor_BEV_ORUDataIndex_XIX_ORU_0001_XIX_E3V_CCAN: start 12, 4 bit, little-endian, data-type-policy=OVERRIDE, i-signal-type=PRIMITIVE, init-value=0, base-type=BT_Motor_BEV_ORUDataIndex, compu {phys=raw for raw 0..15}, range phys 0..15, raw 0..15, to SAM(timeout 5 s)  # Data index of the last 6 Bytes
          signal Motor_BEV_ORUData_XIX_ORU_0001_XIX_E3V_CCAN: start 16, 48 bit, little-endian, data-type-policy=OVERRIDE, i-signal-type=PRIMITIVE, init-value=0, base-type=BT_Motor_BEV_ORUData, compu {phys=raw for raw 0..281474976710655}, range phys 0..281474976710655, raw 0..281474976710655, to SAM(timeout 5 s)  # ORU information multiplexed - diagnostic address (2 bytes) - HW-part no (11 bytes) - HW version no. (3 bytes) - SW version no. (4 bytes) - IVD-P Value (64 bytes) need to be sent in combination with ORUDataIndex
          mapping SG_ORU_0001_XIX_E3V_CCAN: i-signal-group=SG_ORU_0001_XIX_E3V_CCAN, transfer-property=TRIGGERED-WITHOUT-REPETITION
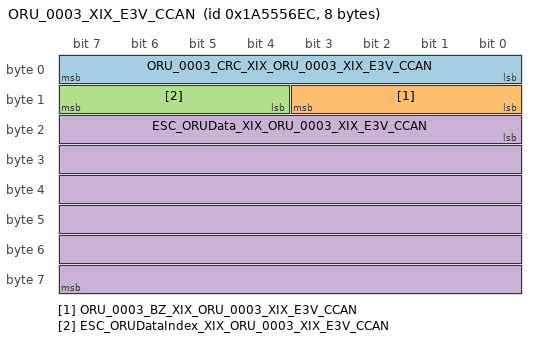
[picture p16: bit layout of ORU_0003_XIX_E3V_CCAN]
      frame ORU_0003_XIX_E3V_CCAN: id 0x1A5556EC, to SAM, frame-length=8, can-addressing-mode=EXTENDED, can-frame-rx-behavior=CAN-20, can-frame-tx-behavior=CAN-20
        pdu ORU_0003_XIX_E3V_CCAN_E2E: length=8, transmission-mode-true-timing=event-controlled-timing={number-of-repetitions=0, repetition-period=0.0}, unused-bit-pattern=0  # Fuer die Botschaft ist das Cyclic-Timing 0.5 zu verwenden.
          signal ORU_0003_CRC_XIX_ORU_0003_XIX_E3V_CCAN: start 0, 8 bit, little-endian, data-type-policy=OVERRIDE, i-signal-type=PRIMITIVE, init-value=0, base-type=BT_ORU_0003_CRC, compu {phys=raw for raw 0..255}, range phys 0..255, raw 0..255, to SAM(timeout 5 s)  # Für MLB: Berechnung siehe Lastenheft "Kommunikationsabsicherung für FlexRay und CAN" Ab MQB und MLBevo: Berechnung siehe Lastenheft "End-to-End Kommunikationsabsicherung" Endwerte siehe Begleitdokument "S-PDU Kennungsfolgen"
          signal ORU_0003_BZ_XIX_ORU_0003_XIX_E3V_CCAN: start 8, 4 bit, little-endian, data-type-policy=OVERRIDE, i-signal-type=PRIMITIVE, init-value=0, base-type=BT_ORU_0003_BZ, compu {phys=raw for raw 0..15}, range phys 0..15, raw 0..15, to SAM(timeout 5 s)  # 4bit Botschaftszähler, wird mit jeder Sendebotschaft inkrementiert
          signal ESC_ORUDataIndex_XIX_ORU_0003_XIX_E3V_CCAN: start 12, 4 bit, little-endian, data-type-policy=OVERRIDE, i-signal-type=PRIMITIVE, init-value=0, base-type=BT_ESC_ORUDataIndex, compu {phys=raw for raw 0..15}, range phys 0..15, raw 0..15, to SAM(timeout 5 s)  # Data index of the last 6 Bytes
          signal ESC_ORUData_XIX_ORU_0003_XIX_E3V_CCAN: start 16, 48 bit, little-endian, data-type-policy=OVERRIDE, i-signal-type=PRIMITIVE, init-value=0, base-type=BT_ESC_ORUData, compu {phys=raw for raw 0..281474976710655}, range phys 0..281474976710655, raw 0..281474976710655, to SAM(timeout 5 s)  # ORU information multiplexed - diagnostic address (2 bytes) - HW-part no (11 bytes) - HW version no. (3 bytes) - SW version no. (4 bytes) - IVD-P Value (64 bytes) need to be sent in combination with ORUDataIndex
          mapping SG_ORU_0003_XIX_E3V_CCAN: i-signal-group=SG_ORU_0003_XIX_E3V_CCAN, transfer-property=TRIGGERED-WITHOUT-REPETITION
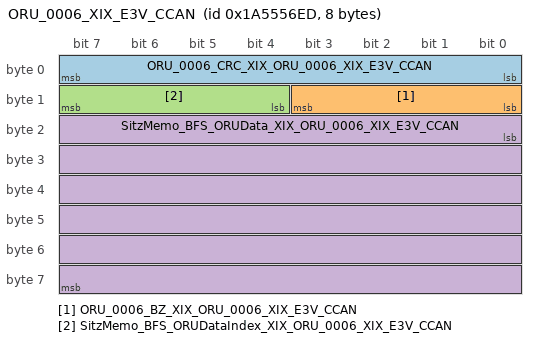
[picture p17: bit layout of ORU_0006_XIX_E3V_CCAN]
      frame ORU_0006_XIX_E3V_CCAN: id 0x1A5556ED, to SAM, frame-length=8, can-addressing-mode=EXTENDED, can-frame-rx-behavior=CAN-20, can-frame-tx-behavior=CAN-20
        pdu ORU_0006_XIX_E3V_CCAN_E2E: length=8, transmission-mode-true-timing=event-controlled-timing={number-of-repetitions=0, repetition-period=0.0}, unused-bit-pattern=0  # Fuer die Botschaft ist das Cyclic-Timing 0.5 zu verwenden.
          signal ORU_0006_CRC_XIX_ORU_0006_XIX_E3V_CCAN: start 0, 8 bit, little-endian, data-type-policy=OVERRIDE, i-signal-type=PRIMITIVE, init-value=0, base-type=BT_ORU_0006_CRC, compu {phys=raw for raw 0..255}, range phys 0..255, raw 0..255, to SAM(timeout 5 s)  # Für MLB: Berechnung siehe Lastenheft "Kommunikationsabsicherung für FlexRay und CAN" Ab MQB und MLBevo: Berechnung siehe Lastenheft "End-to-End Kommunikationsabsicherung" Endwerte siehe Begleitdokument "S-PDU Kennungsfolgen"
          signal ORU_0006_BZ_XIX_ORU_0006_XIX_E3V_CCAN: start 8, 4 bit, little-endian, data-type-policy=OVERRIDE, i-signal-type=PRIMITIVE, init-value=0, base-type=BT_ORU_0006_BZ, compu {phys=raw for raw 0..15}, range phys 0..15, raw 0..15, to SAM(timeout 5 s)  # 4bit Botschaftszähler, wird mit jeder Sendebotschaft inkrementiert
          signal SitzMemo_BFS_ORUDataIndex_XIX_ORU_0006_XIX_E3V_CCAN: start 12, 4 bit, little-endian, data-type-policy=OVERRIDE, i-signal-type=PRIMITIVE, init-value=0, base-type=BT_SitzMemo_BFS_ORUDataIndex, compu {phys=raw for raw 0..15}, range phys 0..15, raw 0..15, to SAM(timeout 5 s)  # Data index of the last 6 Bytes
          signal SitzMemo_BFS_ORUData_XIX_ORU_0006_XIX_E3V_CCAN: start 16, 48 bit, little-endian, data-type-policy=OVERRIDE, i-signal-type=PRIMITIVE, init-value=0, base-type=BT_SitzMemo_BFS_ORUData, compu {phys=raw for raw 0..281474976710655}, range phys 0..281474976710655, raw 0..281474976710655, to SAM(timeout 5 s)  # ORU information multiplexed - diagnostic address (2 bytes) - HW-part no (11 bytes) - HW version no. (3 bytes) - SW version no. (4 bytes) - IVD-P Value (64 bytes) need to be sent in combination with ORUDataIndex
          mapping SG_ORU_0006_XIX_E3V_CCAN: i-signal-group=SG_ORU_0006_XIX_E3V_CCAN, transfer-property=TRIGGERED-WITHOUT-REPETITION
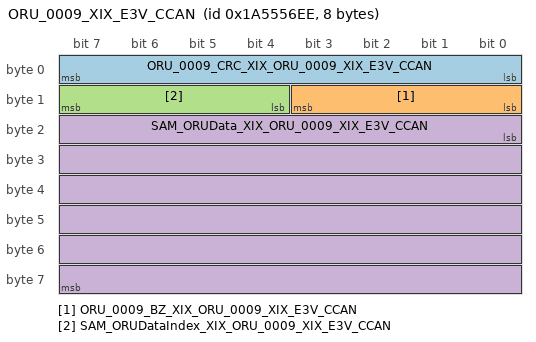
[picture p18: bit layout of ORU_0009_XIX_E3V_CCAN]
      frame ORU_0009_XIX_E3V_CCAN: id 0x1A5556EE, from SAM, frame-length=8, can-addressing-mode=EXTENDED, can-frame-rx-behavior=CAN-20, can-frame-tx-behavior=CAN-20
        pdu ORU_0009_XIX_E3V_CCAN_E2E: length=8, transmission-mode-true-timing=event-controlled-timing={number-of-repetitions=0, repetition-period=0.0}, unused-bit-pattern=0  # Fuer die Botschaft ist das Cyclic-Timing 0.5 zu verwenden.
          signal ORU_0009_CRC_XIX_ORU_0009_XIX_E3V_CCAN: start 0, 8 bit, little-endian, data-type-policy=OVERRIDE, i-signal-type=PRIMITIVE, init-value=0, base-type=BT_ORU_0009_CRC, compu {phys=raw for raw 0..255}, range phys 0..255, raw 0..255  # Für MLB: Berechnung siehe Lastenheft "Kommunikationsabsicherung für FlexRay und CAN" Ab MQB und MLBevo: Berechnung siehe Lastenheft "End-to-End Kommunikationsabsicherung" Endwerte siehe Begleitdokument "S-PDU Kennungsfolgen"
          signal ORU_0009_BZ_XIX_ORU_0009_XIX_E3V_CCAN: start 8, 4 bit, little-endian, data-type-policy=OVERRIDE, i-signal-type=PRIMITIVE, init-value=0, base-type=BT_ORU_0009_BZ, compu {phys=raw for raw 0..15}, range phys 0..15, raw 0..15  # 4bit Botschaftszähler, wird mit jeder Sendebotschaft inkrementiert
          signal SAM_ORUDataIndex_XIX_ORU_0009_XIX_E3V_CCAN: start 12, 4 bit, little-endian, data-type-policy=OVERRIDE, i-signal-type=PRIMITIVE, init-value=0, base-type=BT_SAM_ORUDataIndex, compu {phys=raw for raw 0..15}, range phys 0..15, raw 0..15  # Data index of the last 6 Bytes
          signal SAM_ORUData_XIX_ORU_0009_XIX_E3V_CCAN: start 16, 48 bit, little-endian, data-type-policy=OVERRIDE, i-signal-type=PRIMITIVE, init-value=0, base-type=BT_SAM_ORUData, compu {phys=raw for raw 0..281474976710655}, range phys 0..281474976710655, raw 0..281474976710655  # ORU information multiplexed - diagnostic address (2 bytes) - HW-part no (11 bytes) - HW version no. (3 bytes) - SW version no. (4 bytes) - IVD-P Value (64 bytes) need to be sent in combination with ORUDataIndex
          mapping SG_ORU_0009_XIX_E3V_CCAN: i-signal-group=SG_ORU_0009_XIX_E3V_CCAN, transfer-property=TRIGGERED-WITHOUT-REPETITION
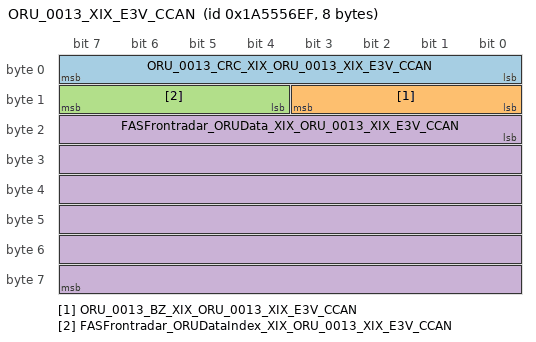
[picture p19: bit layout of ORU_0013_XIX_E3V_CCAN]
      frame ORU_0013_XIX_E3V_CCAN: id 0x1A5556EF, to SAM, frame-length=8, can-addressing-mode=EXTENDED, can-frame-rx-behavior=CAN-20, can-frame-tx-behavior=CAN-20
        pdu ORU_0013_XIX_E3V_CCAN_E2E: length=8, transmission-mode-true-timing=event-controlled-timing={number-of-repetitions=0, repetition-period=0.0}, unused-bit-pattern=0  # Fuer die Botschaft ist das Cyclic-Timing 0.5 zu verwenden.
          signal ORU_0013_CRC_XIX_ORU_0013_XIX_E3V_CCAN: start 0, 8 bit, little-endian, data-type-policy=OVERRIDE, i-signal-type=PRIMITIVE, base-type=BT_ORU_0013_CRC, compu {phys=raw for raw 0..255}, range phys 0..255, raw 0..255, to SAM(timeout 5 s)  # Für MLB: Berechnung siehe Lastenheft "Kommunikationsabsicherung für FlexRay und CAN" Ab MQB und MLBevo: Berechnung siehe Lastenheft "End-to-End Kommunikationsabsicherung" Endwerte siehe Begleitdokument "S-PDU Kennungsfolgen"
          signal ORU_0013_BZ_XIX_ORU_0013_XIX_E3V_CCAN: start 8, 4 bit, little-endian, data-type-policy=OVERRIDE, i-signal-type=PRIMITIVE, base-type=BT_ORU_0013_BZ, compu {phys=raw for raw 0..15}, range phys 0..15, raw 0..15, to SAM(timeout 5 s)  # 4bit Botschaftszähler, wird mit jeder Sendebotschaft inkrementiert
          signal FASFrontradar_ORUDataIndex_XIX_ORU_0013_XIX_E3V_CCAN: start 12, 4 bit, little-endian, data-type-policy=OVERRIDE, i-signal-type=PRIMITIVE, init-value=0, base-type=BT_FASFrontradar_ORUDataIndex, compu {phys=raw for raw 0..15}, range phys 0..15, raw 0..15, to SAM(timeout 5 s)  # Data index of the last 6 Bytes
          signal FASFrontradar_ORUData_XIX_ORU_0013_XIX_E3V_CCAN: start 16, 48 bit, little-endian, data-type-policy=OVERRIDE, i-signal-type=PRIMITIVE, init-value=0, base-type=BT_FASFrontradar_ORUData, compu {phys=raw for raw 0..281474976710655}, range phys 0..281474976710655, raw 0..281474976710655, to SAM(timeout 5 s)  # ORU information multiplexed - diagnostic address (2 bytes) - HW-part no (11 bytes) - HW version no. (3 bytes) - SW version no. (4 bytes) - IVD-P Value (64 bytes) need to be sent in combination with ORUDataIndex
          mapping SG_ORU_0013_XIX_E3V_CCAN: i-signal-group=SG_ORU_0013_XIX_E3V_CCAN, transfer-property=TRIGGERED-WITHOUT-REPETITION
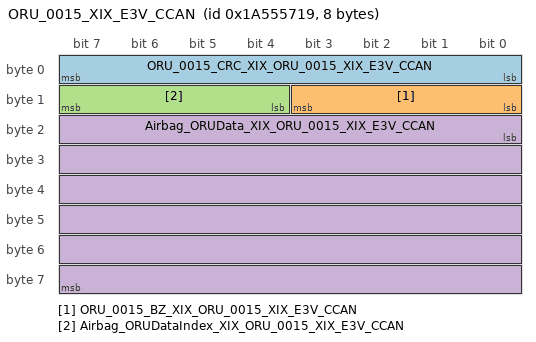
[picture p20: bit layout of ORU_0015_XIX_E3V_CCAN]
      frame ORU_0015_XIX_E3V_CCAN: id 0x1A555719, to SAM, frame-length=8, can-addressing-mode=EXTENDED, can-frame-rx-behavior=CAN-20, can-frame-tx-behavior=CAN-20
        pdu ORU_0015_XIX_E3V_CCAN_E2E: length=8, transmission-mode-true-timing=event-controlled-timing={number-of-repetitions=0, repetition-period=0.0}, unused-bit-pattern=0  # Fuer die Botschaft ist das Cyclic-Timing 0.5 zu verwenden.
          signal ORU_0015_CRC_XIX_ORU_0015_XIX_E3V_CCAN: start 0, 8 bit, little-endian, data-type-policy=OVERRIDE, i-signal-type=PRIMITIVE, init-value=0, base-type=BT_ORU_0015_CRC, compu {phys=raw for raw 0..255}, range phys 0..255, raw 0..255, to SAM(timeout 5 s)  # Für MLB: Berechnung siehe Lastenheft "Kommunikationsabsicherung für FlexRay und CAN" Ab MQB und MLBevo: Berechnung siehe Lastenheft "End-to-End Kommunikationsabsicherung" Endwerte siehe Begleitdokument "S-PDU Kennungsfolgen"
          signal ORU_0015_BZ_XIX_ORU_0015_XIX_E3V_CCAN: start 8, 4 bit, little-endian, data-type-policy=OVERRIDE, i-signal-type=PRIMITIVE, init-value=0, base-type=BT_ORU_0015_BZ, compu {phys=raw for raw 0..15}, range phys 0..15, raw 0..15, to SAM(timeout 5 s)  # 4bit Botschaftszähler, wird mit jeder Sendebotschaft inkrementiert
          signal Airbag_ORUDataIndex_XIX_ORU_0015_XIX_E3V_CCAN: start 12, 4 bit, little-endian, data-type-policy=OVERRIDE, i-signal-type=PRIMITIVE, init-value=0, base-type=BT_Airbag_ORUDataIndex, compu {phys=raw for raw 0..15}, range phys 0..15, raw 0..15, to SAM(timeout 5 s)  # Data index of the last 6 Bytes
          signal Airbag_ORUData_XIX_ORU_0015_XIX_E3V_CCAN: start 16, 48 bit, little-endian, data-type-policy=OVERRIDE, i-signal-type=PRIMITIVE, init-value=0, base-type=BT_Airbag_ORUData, compu {phys=raw for raw 0..281474976710655}, range phys 0..281474976710655, raw 0..281474976710655, to SAM(timeout 5 s)  # ORU information multiplexed - diagnostic address (2 bytes) - HW-part no (11 bytes) - HW version no. (3 bytes) - SW version no. (4 bytes) - IVD-P Value (64 bytes) need to be sent in combination with ORUDataIndex
          mapping SG_ORU_0015_XIX_E3V_CCAN: i-signal-group=SG_ORU_0015_XIX_E3V_CCAN, transfer-property=TRIGGERED-WITHOUT-REPETITION
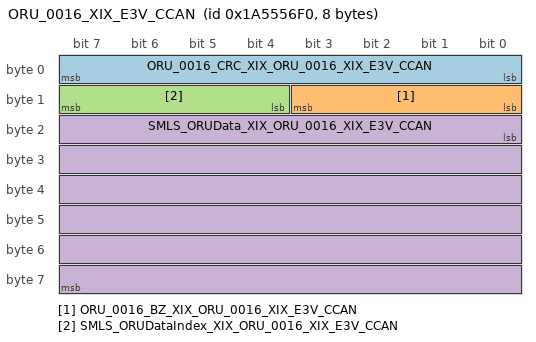
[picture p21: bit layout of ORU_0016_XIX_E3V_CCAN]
      frame ORU_0016_XIX_E3V_CCAN: id 0x1A5556F0, to SAM, frame-length=8, can-addressing-mode=EXTENDED, can-frame-rx-behavior=CAN-20, can-frame-tx-behavior=CAN-20
        pdu ORU_0016_XIX_E3V_CCAN_E2E: length=8, transmission-mode-true-timing=event-controlled-timing={number-of-repetitions=0, repetition-period=0.0}, unused-bit-pattern=0  # Fuer die Botschaft ist das Cyclic-Timing 0.5 zu verwenden.
          signal ORU_0016_CRC_XIX_ORU_0016_XIX_E3V_CCAN: start 0, 8 bit, little-endian, data-type-policy=OVERRIDE, i-signal-type=PRIMITIVE, init-value=0, base-type=BT_ORU_0016_CRC, compu {phys=raw for raw 0..255}, range phys 0..255, raw 0..255, to SAM(timeout 5 s)  # Für MLB: Berechnung siehe Lastenheft "Kommunikationsabsicherung für FlexRay und CAN" Ab MQB und MLBevo: Berechnung siehe Lastenheft "End-to-End Kommunikationsabsicherung" Endwerte siehe Begleitdokument "S-PDU Kennungsfolgen"
          signal ORU_0016_BZ_XIX_ORU_0016_XIX_E3V_CCAN: start 8, 4 bit, little-endian, data-type-policy=OVERRIDE, i-signal-type=PRIMITIVE, init-value=0, base-type=BT_ORU_0016_BZ, compu {phys=raw for raw 0..15}, range phys 0..15, raw 0..15, to SAM(timeout 5 s)  # 4bit Botschaftszähler, wird mit jeder Sendebotschaft inkrementiert
          signal SMLS_ORUDataIndex_XIX_ORU_0016_XIX_E3V_CCAN: start 12, 4 bit, little-endian, data-type-policy=OVERRIDE, i-signal-type=PRIMITIVE, init-value=0, base-type=BT_SMLS_ORUDataIndex, compu {phys=raw for raw 0..15}, range phys 0..15, raw 0..15, to SAM(timeout 5 s)  # Data index of the last 6 Bytes
          signal SMLS_ORUData_XIX_ORU_0016_XIX_E3V_CCAN: start 16, 48 bit, little-endian, data-type-policy=OVERRIDE, i-signal-type=PRIMITIVE, init-value=0, base-type=BT_SMLS_ORUData, compu {phys=raw for raw 0..281474976710655}, range phys 0..281474976710655, raw 0..281474976710655, to SAM(timeout 5 s)  # ORU information multiplexed - diagnostic address (2 bytes) - HW-part no (11 bytes) - HW version no. (3 bytes) - SW version no. (4 bytes) - IVD-P Value (64 bytes) need to be sent in combination with ORUDataIndex
          mapping SG_ORU_0016_XIX_E3V_CCAN: i-signal-group=SG_ORU_0016_XIX_E3V_CCAN, transfer-property=TRIGGERED-WITHOUT-REPETITION
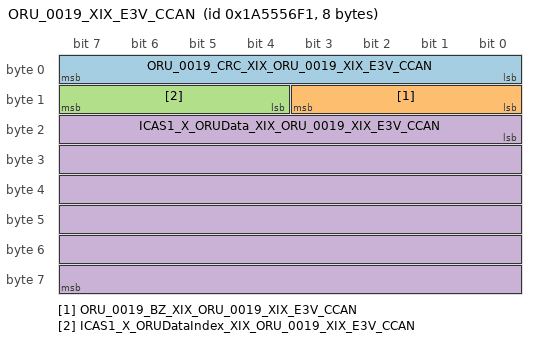
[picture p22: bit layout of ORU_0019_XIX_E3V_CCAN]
      frame ORU_0019_XIX_E3V_CCAN: id 0x1A5556F1, to SAM, frame-length=8, can-addressing-mode=EXTENDED, can-frame-rx-behavior=CAN-20, can-frame-tx-behavior=CAN-20
        pdu ORU_0019_XIX_E3V_CCAN_E2E: length=8, transmission-mode-true-timing=event-controlled-timing={number-of-repetitions=0, repetition-period=0.0}, unused-bit-pattern=0  # Fuer die Botschaft ist das Cyclic-Timing 0.5 zu verwenden.
          signal ORU_0019_CRC_XIX_ORU_0019_XIX_E3V_CCAN: start 0, 8 bit, little-endian, data-type-policy=OVERRIDE, i-signal-type=PRIMITIVE, init-value=0, base-type=BT_ORU_0019_CRC, compu {phys=raw for raw 0..255}, range phys 0..255, raw 0..255, to SAM(timeout 5 s)  # Für MLB: Berechnung siehe Lastenheft "Kommunikationsabsicherung für FlexRay und CAN" Ab MQB und MLBevo: Berechnung siehe Lastenheft "End-to-End Kommunikationsabsicherung" Endwerte siehe Begleitdokument "S-PDU Kennungsfolgen"
          signal ORU_0019_BZ_XIX_ORU_0019_XIX_E3V_CCAN: start 8, 4 bit, little-endian, data-type-policy=OVERRIDE, i-signal-type=PRIMITIVE, init-value=0, base-type=BT_ORU_0019_BZ, compu {phys=raw for raw 0..15}, range phys 0..15, raw 0..15, to SAM(timeout 5 s)  # 4bit Botschaftszähler, wird mit jeder Sendebotschaft inkrementiert
          signal ICAS1_X_ORUDataIndex_XIX_ORU_0019_XIX_E3V_CCAN: start 12, 4 bit, little-endian, data-type-policy=OVERRIDE, i-signal-type=PRIMITIVE, init-value=0, base-type=BT_ICAS1_X_ORUDataIndex, compu {phys=raw for raw 0..15}, range phys 0..15, raw 0..15, to SAM(timeout 5 s)  # Data index of the last 6 Bytes
          signal ICAS1_X_ORUData_XIX_ORU_0019_XIX_E3V_CCAN: start 16, 48 bit, little-endian, data-type-policy=OVERRIDE, i-signal-type=PRIMITIVE, init-value=0, base-type=BT_ICAS1_X_ORUData, compu {phys=raw for raw 0..281474976710655}, range phys 0..281474976710655, raw 0..281474976710655, to SAM(timeout 5 s)  # ORU information multiplexed - diagnostic address (2 bytes) - HW-part no (11 bytes) - HW version no. (3 bytes) - SW version no. (4 bytes) - IVD-P Value (64 bytes) need to be sent in combination with ORUDataIndex
          mapping SG_ORU_0019_XIX_E3V_CCAN: i-signal-group=SG_ORU_0019_XIX_E3V_CCAN, transfer-property=TRIGGERED-WITHOUT-REPETITION
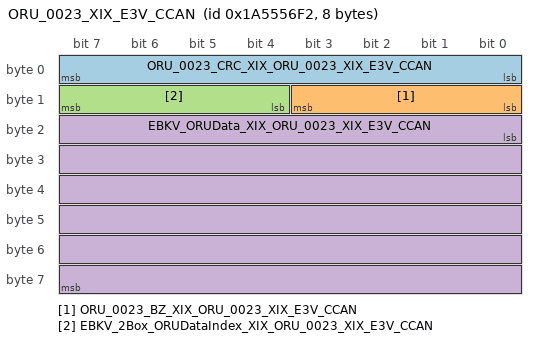
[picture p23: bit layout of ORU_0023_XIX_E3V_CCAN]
      frame ORU_0023_XIX_E3V_CCAN: id 0x1A5556F2, to SAM, frame-length=8, can-addressing-mode=EXTENDED, can-frame-rx-behavior=CAN-20, can-frame-tx-behavior=CAN-20
        pdu ORU_0023_XIX_E3V_CCAN_E2E: length=8, transmission-mode-true-timing=event-controlled-timing={number-of-repetitions=0, repetition-period=0.0}, unused-bit-pattern=0  # Fuer die Botschaft ist das Cyclic-Timing 0.5 zu verwenden.
          signal ORU_0023_CRC_XIX_ORU_0023_XIX_E3V_CCAN: start 0, 8 bit, little-endian, data-type-policy=OVERRIDE, i-signal-type=PRIMITIVE, init-value=0, base-type=BT_ORU_0023_CRC, compu {phys=raw for raw 0..255}, range phys 0..255, raw 0..255, to SAM(timeout 5 s)  # Für MLB: Berechnung siehe Lastenheft "Kommunikationsabsicherung für FlexRay und CAN" Ab MQB und MLBevo: Berechnung siehe Lastenheft "End-to-End Kommunikationsabsicherung" Endwerte siehe Begleitdokument "S-PDU Kennungsfolgen"
          signal ORU_0023_BZ_XIX_ORU_0023_XIX_E3V_CCAN: start 8, 4 bit, little-endian, data-type-policy=OVERRIDE, i-signal-type=PRIMITIVE, init-value=0, base-type=BT_ORU_0023_BZ, compu {phys=raw for raw 0..15}, range phys 0..15, raw 0..15, to SAM(timeout 5 s)  # 4bit Botschaftszähler, wird mit jeder Sendebotschaft inkrementiert
          signal EBKV_2Box_ORUDataIndex_XIX_ORU_0023_XIX_E3V_CCAN: start 12, 4 bit, little-endian, data-type-policy=OVERRIDE, i-signal-type=PRIMITIVE, init-value=0, base-type=BT_EBKV_2Box_ORUDataIndex, compu {phys=raw for raw 0..15}, range phys 0..15, raw 0..15, to SAM(timeout 5 s)  # Data index of the last 6 Bytes
          signal EBKV_ORUData_XIX_ORU_0023_XIX_E3V_CCAN: start 16, 48 bit, little-endian, data-type-policy=OVERRIDE, i-signal-type=PRIMITIVE, init-value=0, base-type=BT_EBKV_ORUData, compu {phys=raw for raw 0..281474976710655}, range phys 0..281474976710655, raw 0..281474976710655, to SAM(timeout 5 s)  # ORU information multiplexed - diagnostic address (2 bytes) - HW-part no (11 bytes) - HW version no. (3 bytes) - SW version no. (4 bytes) - IVD-P Value (64 bytes) need to be sent in combination with ORUDataIndex
          mapping SG_ORU_0023_XIX_E3V_CCAN: i-signal-group=SG_ORU_0023_XIX_E3V_CCAN, transfer-property=TRIGGERED-WITHOUT-REPETITION
      frame ORU_0036_XIX_E3V_CCAN: id 0x1A5556F3, to SAM, frame-length=8, can-addressing-mode=EXTENDED, can-frame-rx-behavior=CAN-20, can-frame-tx-behavior=CAN-20
        pdu ORU_0036_XIX_E3V_CCAN_E2E: length=8, transmission-mode-true-timing=event-controlled-timing={number-of-repetitions=0, repetition-period=0.0}, unused-bit-pattern=0  # Fuer die Botschaft ist das Cyclic-Timing 0.5 zu verwenden.
          signal ORU_0036_CRC_XIX_ORU_0036_XIX_E3V_CCAN: start 0, 8 bit, little-endian, data-type-policy=OVERRIDE, i-signal-type=PRIMITIVE, init-value=0, base-type=BT_ORU_0036_CRC, compu {phys=raw for raw 0..255}, range phys 0..255, raw 0..255, to SAM(timeout 5 s)  # Für MLB: Berechnung siehe Lastenheft "Kommunikationsabsicherung für FlexRay und CAN" Ab MQB und MLBevo: Berechnung siehe Lastenheft "End-to-End Kommunikationsabsicherung" Endwerte siehe Begleitdokument "S-PDU Kennungsfolgen"
          signal ORU_0036_BZ_XIX_ORU_0036_XIX_E3V_CCAN: start 8, 4 bit, little-endian, data-type-policy=OVERRIDE, i-signal-type=PRIMITIVE, init-value=0, base-type=BT_ORU_0036_BZ, compu {phys=raw for raw 0..15}, range phys 0..15, raw 0..15, to SAM(timeout 5 s)  # 4bit Botschaftszähler, wird mit jeder Sendebotschaft inkrementiert
          signal SitzMemo_FS_ORUDataIndex_XIX_ORU_0036_XIX_E3V_CCAN: start 12, 4 bit, little-endian, data-type-policy=OVERRIDE, i-signal-type=PRIMITIVE, init-value=0, base-type=BT_SitzMemo_FS_ORUDataIndex, compu {phys=raw for raw 0..15}, range phys 0..15, raw 0..15, to SAM(timeout 5 s)  # Data index of the last 6 Bytes
          signal SitzMemo_FS_ORUData_XIX_ORU_0036_XIX_E3V_CCAN: start 16, 48 bit, little-endian, data-type-policy=OVERRIDE, i-signal-type=PRIMITIVE, init-value=0, base-type=BT_SitzMemo_FS_ORUData, compu {phys=raw for raw 0..281474976710655}, range phys 0..281474976710655, raw 0..281474976710655, to SAM(timeout 5 s)  # ORU information multiplexed - diagnostic address (2 bytes) - HW-part no (11 bytes) - HW version no. (3 bytes) - SW version no. (4 bytes) - IVD-P Value (64 bytes) need to be sent in combination with ORUDataIndex
          mapping SG_ORU_0036_XIX_E3V_CCAN: i-signal-group=SG_ORU_0036_XIX_E3V_CCAN, transfer-property=TRIGGERED-WITHOUT-REPETITION
      frame ORU_0042_XIX_E3V_CCAN: id 0x1A5556F5, to SAM, frame-length=8, can-addressing-mode=EXTENDED, can-frame-rx-behavior=CAN-20, can-frame-tx-behavior=CAN-20
        pdu ORU_0042_XIX_E3V_CCAN_E2E: length=8, transmission-mode-true-timing=event-controlled-timing={number-of-repetitions=0, repetition-period=0.0}, unused-bit-pattern=0  # Fuer die Botschaft ist das Cyclic-Timing 0.5 zu verwenden.
          signal ORU_0042_CRC_XIX_ORU_0042_XIX_E3V_CCAN: start 0, 8 bit, little-endian, data-type-policy=OVERRIDE, i-signal-type=PRIMITIVE, init-value=0, base-type=BT_ORU_0042_CRC, compu {phys=raw for raw 0..255}, range phys 0..255, raw 0..255, to SAM(timeout 5 s)  # Für MLB: Berechnung siehe Lastenheft "Kommunikationsabsicherung für FlexRay und CAN" Ab MQB und MLBevo: Berechnung siehe Lastenheft "End-to-End Kommunikationsabsicherung" Endwerte siehe Begleitdokument "S-PDU Kennungsfolgen"
          signal ORU_0042_BZ_XIX_ORU_0042_XIX_E3V_CCAN: start 8, 4 bit, little-endian, data-type-policy=OVERRIDE, i-signal-type=PRIMITIVE, init-value=0, base-type=BT_ORU_0042_BZ, compu {phys=raw for raw 0..15}, range phys 0..15, raw 0..15, to SAM(timeout 5 s)  # 4bit Botschaftszähler, wird mit jeder Sendebotschaft inkrementiert
          signal TSG_FS_ORUDataIndex_XIX_ORU_0042_XIX_E3V_CCAN: start 12, 4 bit, little-endian, data-type-policy=OVERRIDE, i-signal-type=PRIMITIVE, init-value=0, base-type=BT_TSG_FS_ORUDataIndex, compu {phys=raw for raw 0..15}, range phys 0..15, raw 0..15, to SAM(timeout 5 s)  # Data index of the last 6 Bytes
          signal TSG_FS_ORUData_XIX_ORU_0042_XIX_E3V_CCAN: start 16, 48 bit, little-endian, data-type-policy=OVERRIDE, i-signal-type=PRIMITIVE, init-value=0, base-type=BT_TSG_FS_ORUData, compu {phys=raw for raw 0..281474976710655}, range phys 0..281474976710655, raw 0..281474976710655, to SAM(timeout 5 s)  # ORU information multiplexed - diagnostic address (2 bytes) - HW-part no (11 bytes) - HW version no. (3 bytes) - SW version no. (4 bytes) - IVD-P Value (64 bytes) need to be sent in combination with ORUDataIndex
          mapping SG_ORU_0042_XIX_E3V_CCAN: i-signal-group=SG_ORU_0042_XIX_E3V_CCAN, transfer-property=TRIGGERED-WITHOUT-REPETITION
      frame ORU_0044_XIX_E3V_CCAN: id 0x1A55570F, to SAM, frame-length=8, can-addressing-mode=EXTENDED, can-frame-rx-behavior=CAN-20, can-frame-tx-behavior=CAN-20
        pdu ORU_0044_XIX_E3V_CCAN_E2E: length=8, transmission-mode-true-timing=event-controlled-timing={number-of-repetitions=0, repetition-period=0.0}, unused-bit-pattern=0  # Fuer die Botschaft ist das Cyclic-Timing 0.5 zu verwenden.
          signal ORU_0044_CRC_XIX_ORU_0044_XIX_E3V_CCAN: start 0, 8 bit, little-endian, data-type-policy=OVERRIDE, i-signal-type=PRIMITIVE, init-value=0, base-type=BT_ORU_0044_CRC, compu {phys=raw for raw 0..255}, range phys 0..255, raw 0..255, to SAM(timeout 5 s)  # Für MLB: Berechnung siehe Lastenheft "Kommunikationsabsicherung für FlexRay und CAN" Ab MQB und MLBevo: Berechnung siehe Lastenheft "End-to-End Kommunikationsabsicherung" Endwerte siehe Begleitdokument "S-PDU Kennungsfolgen"
          signal ORU_0044_BZ_XIX_ORU_0044_XIX_E3V_CCAN: start 8, 4 bit, little-endian, data-type-policy=OVERRIDE, i-signal-type=PRIMITIVE, init-value=0, base-type=BT_ORU_0044_BZ, compu {phys=raw for raw 0..15}, range phys 0..15, raw 0..15, to SAM(timeout 5 s)  # 4bit Botschaftszähler, wird mit jeder Sendebotschaft inkrementiert
          signal Lenkhilfe_EPS_ORUDataIndex_XIX_ORU_0044_XIX_E3V_CCAN: start 12, 4 bit, little-endian, data-type-policy=OVERRIDE, i-signal-type=PRIMITIVE, init-value=0, base-type=BT_Lenkhilfe_EPS_ORUDataIndex, compu {phys=raw for raw 0..15}, range phys 0..15, raw 0..15, to SAM(timeout 5 s)  # Data index of the last 6 Bytes
          signal Lenkhilfe_EPS_ORUData_XIX_ORU_0044_XIX_E3V_CCAN: start 16, 48 bit, little-endian, data-type-policy=OVERRIDE, i-signal-type=PRIMITIVE, init-value=0, base-type=BT_Lenkhilfe_EPS_ORUData, compu {phys=raw for raw 0..281474976710655}, range phys 0..281474976710655, raw 0..281474976710655, to SAM(timeout 5 s)  # ORU information multiplexed - diagnostic address (2 bytes) - HW-part no (11 bytes) - HW version no. (3 bytes) - SW version no. (4 bytes) - IVD-P Value (64 bytes) need to be sent in combination with ORUDataIndex
          mapping SG_ORU_0044_XIX_E3V_CCAN: i-signal-group=SG_ORU_0044_XIX_E3V_CCAN, transfer-property=TRIGGERED-WITHOUT-REPETITION
